VERSION "canboat-NMEA2000-curated"

NS_ :

BS_:

BU_: Vector__XXX
BO_ 2583628544 PGN_130827_furunoNavpilotStatus: 13 Vector__XXX
 SG_ Manufacturer_Code : 0|11@1+ (1.0,0) [0|2047] "" Vector__XXX
 SG_ Industry_Code : 13|3@1+ (1.0,0) [0|7] "" Vector__XXX
 SG_ Message_ID : 16|8@1+ (1.0,0) [0|255] "" Vector__XXX
 SG_ Rudder_Angle : 24|16@1+ (0.0001,0) [0.0|6.5535000000000005] "" Vector__XXX
 SG_ A : 40|16@1- (1.0,0) [-32768|32767] "" Vector__XXX
 SG_ B : 56|8@1+ (1.0,0) [0|255] "" Vector__XXX
 SG_ Commanded_Course : 64|16@1+ (0.0001,0) [0.0|6.5535000000000005] "" Vector__XXX
 SG_ C : 80|8@1+ (1.0,0) [0|255] "" Vector__XXX
 SG_ D : 88|16@1+ (1.0,0) [0|65535] "" Vector__XXX

BO_ 2583628544 PGN_130827_lowranceUnknown: 10 Vector__XXX
 SG_ Manufacturer_Code : 0|11@1+ (1.0,0) [0|2047] "" Vector__XXX
 SG_ Industry_Code : 13|3@1+ (1.0,0) [0|7] "" Vector__XXX
 SG_ A : 16|8@1+ (1.0,0) [0|255] "" Vector__XXX
 SG_ B : 24|8@1+ (1.0,0) [0|255] "" Vector__XXX
 SG_ C : 32|8@1+ (1.0,0) [0|255] "" Vector__XXX
 SG_ D : 40|8@1+ (1.0,0) [0|255] "" Vector__XXX
 SG_ E : 48|16@1+ (1.0,0) [0|65535] "" Vector__XXX
 SG_ F : 64|16@1+ (1.0,0) [0|65535] "" Vector__XXX

BO_ 2583628544 PGN_130827_sleipnerThrusterStatus: 13 Vector__XXX
 SG_ Manufacturer_Code : 0|11@1+ (1.0,0) [0|2047] "" Vector__XXX
 SG_ Industry_Code : 13|3@1+ (1.0,0) [0|7] "" Vector__XXX
 SG_ Controller_Type : 16|8@1+ (1.0,0) [0|255] "" Vector__XXX
 SG_ Thruster_Id : 24|4@1+ (1.0,0) [0|15] "" Vector__XXX
 SG_ State : 28|4@1+ (1.0,0) [0|15] "" Vector__XXX
 SG_ Unique_Number : 32|24@1+ (1.0,0) [0|16777215] "" Vector__XXX
 SG_ A : 56|8@1+ (1.0,0) [0|255] "" Vector__XXX
 SG_ B : 64|8@1+ (1.0,0) [0|255] "" Vector__XXX
 SG_ C : 72|8@1+ (1.0,0) [0|255] "" Vector__XXX
 SG_ D : 80|8@1+ (1.0,0) [0|255] "" Vector__XXX
 SG_ Thrust : 88|8@1- (1.0,0) [-128|127] "%" Vector__XXX
 SG_ E : 96|8@1+ (1.0,0) [0|255] "" Vector__XXX

BO_ 2315193344 PGN_130828_maretronDometicHvacControlStatus: 14 Vector__XXX
 SG_ Manufacturer_Code : 0|11@1+ (1.0,0) [0|2047] "" Vector__XXX
 SG_ Industry_Code : 13|3@1+ (1.0,0) [0|7] "" Vector__XXX
 SG_ CAN_ID : 16|32@1+ (1.0,0) [0|4294967295] "" Vector__XXX
 SG_ Configuration_Mode : 48|8@1+ (1.0,0) [0|255] "" Vector__XXX
 SG_ Status : 56|8@1+ (1.0,0) [0|255] "" Vector__XXX
 SG_ Fan_Mode_Speed : 64|8@1+ (1.0,0) [0|255] "" Vector__XXX
 SG_ Setpoint_Temperature : 72|8@1+ (1.0,0) [0|255] "" Vector__XXX
 SG_ Ambient_Temperature : 80|8@1+ (1.0,0) [0|255] "" Vector__XXX
 SG_ Outdoor_Temperature : 88|8@1+ (1.0,0) [0|255] "" Vector__XXX
 SG_ Fault_Status : 96|8@1+ (1.0,0) [0|255] "" Vector__XXX
 SG_ Additional_Sensor_Temperature : 104|8@1+ (1.0,0) [0|255] "" Vector__XXX

BO_ 2583628800 PGN_130828_simnetSetSerialNumber: 8 Vector__XXX
 SG_ Manufacturer_Code : 0|11@1+ (1.0,0) [0|2047] "" Vector__XXX
 SG_ Industry_Code : 13|3@1+ (1.0,0) [0|7] "" Vector__XXX

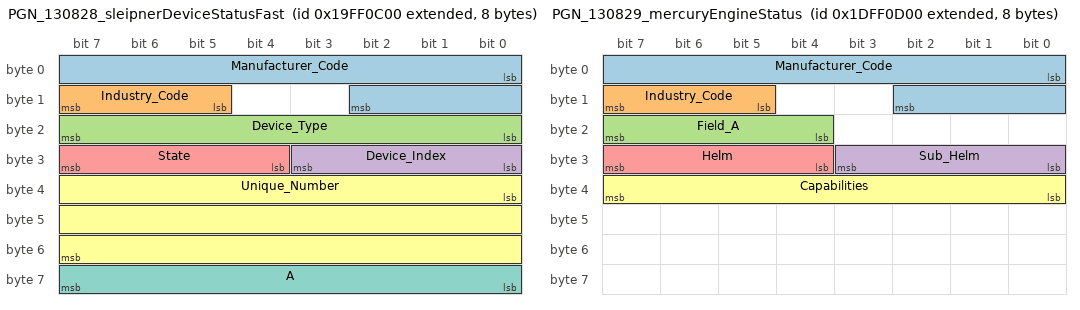
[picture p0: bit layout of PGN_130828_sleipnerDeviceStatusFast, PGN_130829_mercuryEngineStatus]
BO_ 2583628800 PGN_130828_sleipnerDeviceStatusFast: 8 Vector__XXX
 SG_ Manufacturer_Code : 0|11@1+ (1.0,0) [0|2047] "" Vector__XXX
 SG_ Industry_Code : 13|3@1+ (1.0,0) [0|7] "" Vector__XXX
 SG_ Device_Type : 16|8@1+ (1.0,0) [0|255] "" Vector__XXX
 SG_ Device_Index : 24|4@1+ (1.0,0) [0|15] "" Vector__XXX
 SG_ State : 28|4@1+ (1.0,0) [0|15] "" Vector__XXX
 SG_ Unique_Number : 32|24@1+ (1.0,0) [0|16777215] "" Vector__XXX
 SG_ A : 56|8@1+ (1.0,0) [0|255] "" Vector__XXX

BO_ 2650737920 PGN_130829_mercuryEngineStatus: 8 Vector__XXX
 SG_ Manufacturer_Code : 0|11@1+ (1.0,0) [0|2047] "" Vector__XXX
 SG_ Industry_Code : 13|3@1+ (1.0,0) [0|7] "" Vector__XXX
 SG_ Field_A : 20|4@1+ (1.0,0) [0|15] "" Vector__XXX
 SG_ Sub_Helm : 24|4@1+ (1.0,0) [0|15] "" Vector__XXX
 SG_ Helm : 28|4@1+ (1.0,0) [0|15] "" Vector__XXX
 SG_ Capabilities : 32|8@1+ (1.0,0) [0|255] "" Vector__XXX

BO_ 2516520448 PGN_130830_maretronDometicHvacStatus: 12 Vector__XXX
 SG_ Manufacturer_Code : 0|11@1+ (1.0,0) [0|2047] "" Vector__XXX
 SG_ Industry_Code : 13|3@1+ (1.0,0) [0|7] "" Vector__XXX
 SG_ Additional_Sensor_Temperature : 16|8@1+ (1.0,0) [0|255] "" Vector__XXX
 SG_ CAN_ID : 24|32@1+ (1.0,0) [0|4294967295] "" Vector__XXX
 SG_ State : 56|8@1+ (1.0,0) [0|255] "" Vector__XXX
 SG_ Hardware_Status : 64|8@1+ (1.0,0) [0|255] "" Vector__XXX
 SG_ Faults : 72|8@1+ (1.0,0) [0|255] "" Vector__XXX
 SG_ Line_Voltage : 80|8@1+ (1.0,0) [0|255] "" Vector__XXX
 SG_ Compressor_Current : 88|8@1+ (1.0,0) [0|255] "" Vector__XXX

BO_ 2583629312 PGN_130830_suzukiEngineData: 8 Vector__XXX
 SG_ Manufacturer_Code : 0|11@1+ (1.0,0) [0|2047] "" Vector__XXX
 SG_ Industry_Code : 13|3@1+ (1.0,0) [0|7] "" Vector__XXX

BO_ 2583629568 PGN_130831_maretronUniversalConfigurationFp: 223 Vector__XXX
 SG_ Manufacturer_Code : 0|11@1+ (1.0,0) [0|2047] "" Vector__XXX
 SG_ Industry_Code : 13|3@1+ (1.0,0) [0|7] "" Vector__XXX
 SG_ Data : 16|1768@1+ (1.0,0) [0|16635364987126134419907490844611231857889171561340108669757218330385068731224834608417815051548234195819468783937845710359164977421616154908223175941492902641772198991471137845920843845811776377869137773379678289214194183661112800944378464511794046030758602257005203964634516091405743061582849883160885255175229773660916874237270946647032424101972117051870087763059119895517977437771543686400460392041962138103436564399831189767740372774280024852942859855049773927338342604171805121253257539126169331943684033945189625789470637817855] "" Vector__XXX

BO_ 2583629568 PGN_130831_suzukiEngineAndStorageDeviceConfig: 8 Vector__XXX
 SG_ Manufacturer_Code : 0|11@1+ (1.0,0) [0|2047] "" Vector__XXX
 SG_ Industry_Code : 13|3@1+ (1.0,0) [0|7] "" Vector__XXX

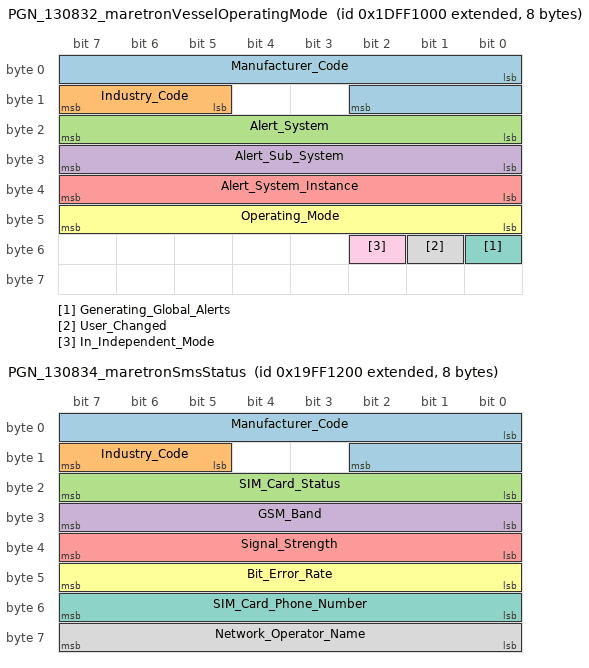
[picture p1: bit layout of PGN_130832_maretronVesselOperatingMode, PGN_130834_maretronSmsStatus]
BO_ 2650738688 PGN_130832_maretronVesselOperatingMode: 8 Vector__XXX
 SG_ Manufacturer_Code : 0|11@1+ (1.0,0) [0|2047] "" Vector__XXX
 SG_ Industry_Code : 13|3@1+ (1.0,0) [0|7] "" Vector__XXX
 SG_ Alert_System : 16|8@1+ (1.0,0) [0|255] "" Vector__XXX
 SG_ Alert_Sub_System : 24|8@1+ (1.0,0) [0|255] "" Vector__XXX
 SG_ Alert_System_Instance : 32|8@1+ (1.0,0) [0|255] "" Vector__XXX
 SG_ Operating_Mode : 40|8@1+ (1.0,0) [0|255] "" Vector__XXX
 SG_ Generating_Global_Alerts : 48|1@1+ (1.0,0) [0|1] "" Vector__XXX
 SG_ User_Changed : 49|1@1+ (1.0,0) [0|1] "" Vector__XXX
 SG_ In_Independent_Mode : 50|1@1+ (1.0,0) [0|1] "" Vector__XXX

BO_ 2583629824 PGN_130832_simnetFuelUsedHighResolution: 8 Vector__XXX
 SG_ Manufacturer_Code : 0|11@1+ (1.0,0) [0|2047] "" Vector__XXX
 SG_ Industry_Code : 13|3@1+ (1.0,0) [0|7] "" Vector__XXX

BO_ 2583630080 PGN_130833_bGUserAndRemoteRename: 30 Vector__XXX
 SG_ Manufacturer_Code : 0|11@1+ (1.0,0) [0|2047] "" Vector__XXX
 SG_ Industry_Code : 13|3@1+ (1.0,0) [0|7] "" Vector__XXX
 SG_ Data_Type : 16|12@1+ (1.0,0) [0|4095] "" Vector__XXX
 SG_ Length : 28|4@1+ (1.0,0) [0|15] "" Vector__XXX
 SG_ Decimals : 40|8@1+ (1.0,0) [0|255] "" Vector__XXX
 SG_ Short_name : 48|64@1+ (1.0,0) [0|18446744073709551615] "" Vector__XXX
 SG_ Long_name : 112|128@1+ (1.0,0) [0|340282366920938463463374607431768211455] "" Vector__XXX

BO_ 2650738944 PGN_130833_furunoShipParametersAndAntennaPosition: 15 Vector__XXX
 SG_ Manufacturer_Code : 0|11@1+ (1.0,0) [0|2047] "" Vector__XXX
 SG_ Industry_Code : 13|3@1+ (1.0,0) [0|7] "" Vector__XXX
 SG_ Equipment_Identification : 16|8@1+ (1.0,0) [0|255] "" Vector__XXX
 SG_ Antenna_position_X : 24|16@1- (0.01,0) [-327.68|327.67] "" Vector__XXX
 SG_ Antenna_position_Y : 40|16@1+ (0.1,0) [0.0|6553.5] "" Vector__XXX
 SG_ Antenna_position_Z : 56|16@1+ (0.1,0) [0.0|6553.5] "" Vector__XXX
 SG_ Ship_s_width : 72|16@1+ (0.1,0) [0.0|6553.5] "" Vector__XXX
 SG_ Ship_s_length : 88|16@1+ (0.1,0) [0.0|6553.5] "" Vector__XXX
 SG_ Ship_s_height : 104|16@1+ (0.1,0) [0.0|6553.5] "" Vector__XXX

BO_ 2650738944 PGN_130833_maretronVesselDataRecorderStatus: 19 Vector__XXX
 SG_ Manufacturer_Code : 0|11@1+ (1.0,0) [0|2047] "" Vector__XXX
 SG_ Industry_Code : 13|3@1+ (1.0,0) [0|7] "" Vector__XXX
 SG_ VDR_Recording_Status : 16|8@1+ (1.0,0) [0|255] "" Vector__XXX
 SG_ Memory_Capacity : 24|64@1+ (1.0,0) [0|18446744073709551615] "" Vector__XXX
 SG_ Memory_Used : 88|64@1+ (1.0,0) [0|18446744073709551615] "" Vector__XXX

BO_ 2650739200 PGN_130834_furunoSpeedCalculationPosition: 9 Vector__XXX
 SG_ Manufacturer_Code : 0|11@1+ (1.0,0) [0|2047] "" Vector__XXX
 SG_ Industry_Code : 13|3@1+ (1.0,0) [0|7] "" Vector__XXX
 SG_ Point_index : 16|8@1+ (1.0,0) [0|255] "" Vector__XXX
 SG_ Position_Y : 40|16@1+ (0.1,0) [0.0|6553.5] "" Vector__XXX
 SG_ Position_Z : 56|16@1+ (0.1,0) [0.0|6553.5] "" Vector__XXX

BO_ 2583630336 PGN_130834_maretronSmsStatus: 8 Vector__XXX
 SG_ Manufacturer_Code : 0|11@1+ (1.0,0) [0|2047] "" Vector__XXX
 SG_ Industry_Code : 13|3@1+ (1.0,0) [0|7] "" Vector__XXX
 SG_ SIM_Card_Status : 16|8@1+ (1.0,0) [0|255] "" Vector__XXX
 SG_ GSM_Band : 24|8@1+ (1.0,0) [0|255] "" Vector__XXX
 SG_ Signal_Strength : 32|8@1+ (1.0,0) [0|255] "" Vector__XXX
 SG_ Bit_Error_Rate : 40|8@1+ (1.0,0) [0|255] "" Vector__XXX
 SG_ SIM_Card_Phone_Number : 48|8@1+ (1.0,0) [0|255] "" Vector__XXX
 SG_ Network_Operator_Name : 56|8@1+ (1.0,0) [0|255] "" Vector__XXX

BO_ 2583630336 PGN_130834_simnetEngineAndTankConfiguration: 8 Vector__XXX
 SG_ Manufacturer_Code : 0|11@1+ (1.0,0) [0|2047] "" Vector__XXX
 SG_ Industry_Code : 13|3@1+ (1.0,0) [0|7] "" Vector__XXX

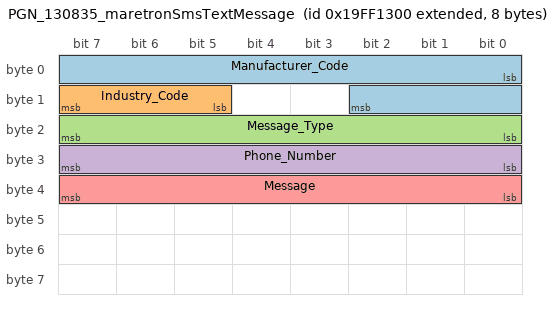
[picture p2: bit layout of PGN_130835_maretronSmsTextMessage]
BO_ 2583630592 PGN_130835_maretronSmsTextMessage: 8 Vector__XXX
 SG_ Manufacturer_Code : 0|11@1+ (1.0,0) [0|2047] "" Vector__XXX
 SG_ Industry_Code : 13|3@1+ (1.0,0) [0|7] "" Vector__XXX
 SG_ Message_Type : 16|8@1+ (1.0,0) [0|255] "" Vector__XXX
 SG_ Phone_Number : 24|8@1+ (1.0,0) [0|255] "" Vector__XXX
 SG_ Message : 32|8@1+ (1.0,0) [0|255] "" Vector__XXX

BO_ 2583630592 PGN_130835_simnetSetEngineAndTankConfiguration: 8 Vector__XXX
 SG_ Manufacturer_Code : 0|11@1+ (1.0,0) [0|2047] "" Vector__XXX
 SG_ Industry_Code : 13|3@1+ (1.0,0) [0|7] "" Vector__XXX

BO_ 2583630848 PGN_130836_maretronSwitchStatusCounter: 23 Vector__XXX
 SG_ Manufacturer_Code : 0|11@1+ (1.0,0) [0|2047] "" Vector__XXX
 SG_ Industry_Code : 13|3@1+ (1.0,0) [0|7] "" Vector__XXX
 SG_ Instance : 16|8@1+ (1.0,0) [0|255] "" Vector__XXX
 SG_ Indicator_Number : 24|8@1+ (1.0,0) [0|255] "" Vector__XXX
 SG_ Start_Date : 32|16@1+ (1.0,0) [0|65535] "" Vector__XXX
 SG_ Start_Time : 48|32@1+ (0.0001,0) [0.0|86401.0] "" Vector__XXX
 SG_ OFF_Counter : 80|32@1+ (1.0,0) [0|4294967295] "" Vector__XXX
 SG_ ON_Counter : 112|32@1+ (1.0,0) [0|4294967295] "" Vector__XXX
 SG_ ERROR_Counter : 144|32@1+ (1.0,0) [0|4294967295] "" Vector__XXX
 SG_ Switch_Status : 176|2@1+ (1.0,0) [0|3] "" Vector__XXX

BO_ 2583630848 PGN_130836_simnetFluidLevelSensorConfiguration: 14 Vector__XXX
 SG_ Manufacturer_Code : 0|11@1+ (1.0,0) [0|2047] "" Vector__XXX
 SG_ Industry_Code : 13|3@1+ (1.0,0) [0|7] "" Vector__XXX
 SG_ C : 16|8@1+ (1.0,0) [0|255] "" Vector__XXX
 SG_ Device : 24|8@1+ (1.0,0) [0|255] "" Vector__XXX
 SG_ Instance : 32|8@1+ (1.0,0) [0|255] "" Vector__XXX
 SG_ F : 40|4@1+ (1.0,0) [0|15] "" Vector__XXX
 SG_ Tank_type : 44|4@1+ (1.0,0) [0|15] "" Vector__XXX
 SG_ Capacity : 48|32@1+ (0.1,0) [0.0|429496729.5] "" Vector__XXX
 SG_ G : 80|8@1+ (1.0,0) [0|255] "" Vector__XXX
 SG_ H : 88|16@1- (1.0,0) [-32768|32767] "" Vector__XXX
 SG_ I : 104|8@1- (1.0,0) [-128|127] "" Vector__XXX

CM_ BO_ 2583628544 "NMEA2000: PGN 130827 - Furuno: NavPilot Status (type: Fast)";
CM_ BO_ 2583628544 "NMEA2000: PGN 130827 - Lowrance: unknown (type: Fast)";
CM_ BO_ 2583628544 "NMEA2000: PGN 130827 - Sleipner: Thruster Status (type: Fast)";
CM_ BO_ 2315193344 "NMEA2000: PGN 130828 - Maretron: Dometic HVAC Control Status (type: Fast)";
CM_ BO_ 2583628800 "NMEA2000: PGN 130828 - Simnet: Set Serial Number (type: Fast)";
CM_ BO_ 2583628800 "NMEA2000: PGN 130828 - Sleipner: Device Status (Fast) (type: Fast)";
CM_ BO_ 2650737920 "NMEA2000: PGN 130829 - Mercury: Engine Status (type: Fast)";
CM_ BO_ 2516520448 "NMEA2000: PGN 130830 - Maretron: Dometic HVAC Status (type: Fast)";
CM_ BO_ 2583629312 "NMEA2000: PGN 130830 - Suzuki: Engine Data (type: Fast)";
CM_ BO_ 2583629568 "NMEA2000: PGN 130831 - Maretron: Universal Configuration FP (type: Fast)";
CM_ BO_ 2583629568 "NMEA2000: PGN 130831 - Suzuki: Engine and Storage Device Config (type: Fast)";
CM_ BO_ 2650738688 "NMEA2000: PGN 130832 - Maretron: Vessel Operating Mode (type: Fast)";
CM_ BO_ 2583629824 "NMEA2000: PGN 130832 - Simnet: Fuel Used - High Resolution (type: Fast)";
CM_ BO_ 2583630080 "NMEA2000: PGN 130833 - B&G: User and Remote rename (type: Fast)";
CM_ BO_ 2650738944 "NMEA2000: PGN 130833 - Furuno: Ship Parameters and Antenna Position (type: Fast)";
CM_ BO_ 2650738944 "NMEA2000: PGN 130833 - Maretron: Vessel Data Recorder Status (type: Fast)";
CM_ BO_ 2650739200 "NMEA2000: PGN 130834 - Furuno: Speed-calculation Position (type: Fast)";
CM_ BO_ 2583630336 "NMEA2000: PGN 130834 - Maretron: SMS Status (type: Fast)";
CM_ BO_ 2583630336 "NMEA2000: PGN 130834 - Simnet: Engine and Tank Configuration (type: Fast)";
CM_ BO_ 2583630592 "NMEA2000: PGN 130835 - Maretron: SMS Text Message (type: Fast)";
CM_ BO_ 2583630592 "NMEA2000: PGN 130835 - Simnet: Set Engine and Tank Configuration (type: Fast)";
CM_ BO_ 2583630848 "NMEA2000: PGN 130836 - Maretron: Switch Status Counter (type: Fast)";
CM_ BO_ 2583630848 "NMEA2000: PGN 130836 - Simnet: Fluid Level Sensor Configuration (type: Fast)";
CM_ SG_ 2583628544 Manufacturer_Code "Furuno; canboat type: LOOKUP";
CM_ SG_ 2583628544 Industry_Code "Marine Industry; canboat type: LOOKUP";
CM_ SG_ 2583628544 Message_ID "NavPilot Status; canboat type: UINT8";
CM_ SG_ 2583628544 Rudder_Angle "canboat type: ANGLE_UFIX16";
CM_ SG_ 2583628544 A "canboat type: INT16";
CM_ SG_ 2583628544 B "canboat type: UINT8";
CM_ SG_ 2583628544 Commanded_Course "canboat type: ANGLE_UFIX16";
CM_ SG_ 2583628544 C "canboat type: UINT8";
CM_ SG_ 2583628544 D "canboat type: UINT16";
CM_ SG_ 2583628544 Manufacturer_Code "Lowrance; canboat type: LOOKUP";
CM_ SG_ 2583628544 Industry_Code "Marine Industry; canboat type: LOOKUP";
CM_ SG_ 2583628544 A "canboat type: UINT8";
CM_ SG_ 2583628544 B "canboat type: UINT8";
CM_ SG_ 2583628544 C "canboat type: UINT8";
CM_ SG_ 2583628544 D "canboat type: UINT8";
CM_ SG_ 2583628544 E "canboat type: UINT16";
CM_ SG_ 2583628544 F "canboat type: UINT16";
CM_ SG_ 2583628544 Manufacturer_Code "Sleipner Motor; canboat type: LOOKUP";
CM_ SG_ 2583628544 Industry_Code "Marine Industry; canboat type: LOOKUP";
CM_ SG_ 2583628544 Controller_Type "Constant per device; 24 = PPC520, 25 = PPC820; canboat type: UINT8";
CM_ SG_ 2583628544 Thruster_Id "Stable per-unit index within the thruster group; canboat type: UNSIGNED_INTEGER";
CM_ SG_ 2583628544 State "canboat type: LOOKUP";
CM_ SG_ 2583628544 Unique_Number "ISO Identity Number, as claimed by this device in PGN 60928; canboat type: UNSIGNED_INTEGER";
CM_ SG_ 2583628544 A "canboat type: UINT8";
CM_ SG_ 2583628544 B "canboat type: UINT8";
CM_ SG_ 2583628544 C "canboat type: UINT8";
CM_ SG_ 2583628544 D "canboat type: UINT8";
CM_ SG_ 2583628544 Thrust "Reported thrust, -100 to 100%; the sign is the direction; canboat type: PERCENTAGE_INT8";
CM_ SG_ 2583628544 E "canboat type: UINT8";
CM_ SG_ 2315193344 Manufacturer_Code "Maretron; canboat type: LOOKUP";
CM_ SG_ 2315193344 Industry_Code "Marine Industry; canboat type: LOOKUP";
CM_ SG_ 2315193344 CAN_ID "canboat type: UINT32";
CM_ SG_ 2315193344 Configuration_Mode "canboat type: UINT8";
CM_ SG_ 2315193344 Status "canboat type: UINT8";
CM_ SG_ 2315193344 Fan_Mode_Speed "canboat type: UINT8";
CM_ SG_ 2315193344 Setpoint_Temperature "canboat type: UINT8";
CM_ SG_ 2315193344 Ambient_Temperature "canboat type: UINT8";
CM_ SG_ 2315193344 Outdoor_Temperature "canboat type: UINT8";
CM_ SG_ 2315193344 Fault_Status "canboat type: UINT8";
CM_ SG_ 2315193344 Additional_Sensor_Temperature "canboat type: UINT8";
CM_ SG_ 2583628800 Manufacturer_Code "Simrad; canboat type: LOOKUP";
CM_ SG_ 2583628800 Industry_Code "Marine Industry; canboat type: LOOKUP";
CM_ SG_ 2583628800 Manufacturer_Code "Sleipner Motor; canboat type: LOOKUP";
CM_ SG_ 2583628800 Industry_Code "Marine Industry; canboat type: LOOKUP";
CM_ SG_ 2583628800 Device_Type "Constant per device; canboat type: UINT8";
CM_ SG_ 2583628800 Device_Index "Stable per-device index; canboat type: UNSIGNED_INTEGER";
CM_ SG_ 2583628800 State "canboat type: LOOKUP";
CM_ SG_ 2583628800 Unique_Number "ISO Identity Number, as claimed by this device in PGN 60928; canboat type: UNSIGNED_INTEGER";
CM_ SG_ 2583628800 A "canboat type: UINT8";
CM_ SG_ 2650737920 Manufacturer_Code "Mercury Marine; canboat type: LOOKUP";
CM_ SG_ 2650737920 Industry_Code "Marine Industry; canboat type: LOOKUP";
CM_ SG_ 2650737920 Field_A "Reserved (unused); canboat type: BINARY";
CM_ SG_ 2650737920 Sub_Helm "Helm-station sub-address (Mercury multi-helm); byte 3 low nibble; canboat type: BINARY";
CM_ SG_ 2650737920 Helm "Helm-station address (Mercury multi-helm); byte 3 high nibble; canboat type: BINARY";
CM_ SG_ 2650737920 Capabilities "Capability bitmask: bit0 = Beacon, bit1 = Cruise Control capability; canboat type: BINARY";
CM_ SG_ 2516520448 Manufacturer_Code "Maretron; canboat type: LOOKUP";
CM_ SG_ 2516520448 Industry_Code "Marine Industry; canboat type: LOOKUP";
CM_ SG_ 2516520448 Additional_Sensor_Temperature "canboat type: UINT8";
CM_ SG_ 2516520448 CAN_ID "canboat type: UINT32";
CM_ SG_ 2516520448 State "canboat type: UINT8";
CM_ SG_ 2516520448 Hardware_Status "canboat type: UINT8";
CM_ SG_ 2516520448 Faults "canboat type: UINT8";
CM_ SG_ 2516520448 Line_Voltage "canboat type: UINT8";
CM_ SG_ 2516520448 Compressor_Current "canboat type: UINT8";
CM_ SG_ 2583629312 Manufacturer_Code "Suzuki Motor Corporation; canboat type: LOOKUP";
CM_ SG_ 2583629312 Industry_Code "Marine Industry; canboat type: LOOKUP";
CM_ SG_ 2583629568 Manufacturer_Code "Maretron; canboat type: LOOKUP";
CM_ SG_ 2583629568 Industry_Code "Marine Industry; canboat type: LOOKUP";
CM_ SG_ 2583629568 Data "canboat type: BINARY";
CM_ SG_ 2583629568 Manufacturer_Code "Suzuki Motor Corporation; canboat type: LOOKUP";
CM_ SG_ 2583629568 Industry_Code "Marine Industry; canboat type: LOOKUP";
CM_ SG_ 2650738688 Manufacturer_Code "Maretron; canboat type: LOOKUP";
CM_ SG_ 2650738688 Industry_Code "Marine Industry; canboat type: LOOKUP";
CM_ SG_ 2650738688 Alert_System "canboat type: UINT8";
CM_ SG_ 2650738688 Alert_Sub_System "canboat type: UINT8";
CM_ SG_ 2650738688 Alert_System_Instance "canboat type: UINT8";
CM_ SG_ 2650738688 Operating_Mode "canboat type: UINT8";
CM_ SG_ 2650738688 Generating_Global_Alerts "canboat type: UNSIGNED_INTEGER";
CM_ SG_ 2650738688 User_Changed "canboat type: UNSIGNED_INTEGER";
CM_ SG_ 2650738688 In_Independent_Mode "canboat type: UNSIGNED_INTEGER";
CM_ SG_ 2583629824 Manufacturer_Code "Simrad; canboat type: LOOKUP";
CM_ SG_ 2583629824 Industry_Code "Marine Industry; canboat type: LOOKUP";
CM_ SG_ 2583630080 Manufacturer_Code "B & G; canboat type: LOOKUP";
CM_ SG_ 2583630080 Industry_Code "Marine Industry; canboat type: LOOKUP";
CM_ SG_ 2583630080 Data_Type "canboat type: DYNAMIC_FIELD_KEY";
CM_ SG_ 2583630080 Length "Length of field 8; canboat type: UNSIGNED_INTEGER";
CM_ SG_ 2583630080 Decimals "canboat type: LOOKUP";
CM_ SG_ 2583630080 Short_name "canboat type: STRING_FIX";
CM_ SG_ 2583630080 Long_name "canboat type: STRING_FIX";
CM_ SG_ 2650738944 Manufacturer_Code "Furuno; canboat type: LOOKUP";
CM_ SG_ 2650738944 Industry_Code "Marine Industry; canboat type: LOOKUP";
CM_ SG_ 2650738944 Equipment_Identification "canboat type: UINT8";
CM_ SG_ 2650738944 Antenna_position_X "Athwartship offset; canboat type: DISTANCE_FIX16_CM";
CM_ SG_ 2650738944 Antenna_position_Y "canboat type: LENGTH_UFIX16_DM";
CM_ SG_ 2650738944 Antenna_position_Z "canboat type: LENGTH_UFIX16_DM";
CM_ SG_ 2650738944 Ship_s_width "canboat type: LENGTH_UFIX16_DM";
CM_ SG_ 2650738944 Ship_s_length "canboat type: LENGTH_UFIX16_DM";
CM_ SG_ 2650738944 Ship_s_height "canboat type: LENGTH_UFIX16_DM";
CM_ SG_ 2650738944 Manufacturer_Code "Maretron; canboat type: LOOKUP";
CM_ SG_ 2650738944 Industry_Code "Marine Industry; canboat type: LOOKUP";
CM_ SG_ 2650738944 VDR_Recording_Status "canboat type: UINT8";
CM_ SG_ 2650738944 Memory_Capacity "canboat type: UINT64";
CM_ SG_ 2650738944 Memory_Used "canboat type: UINT64";
CM_ SG_ 2650739200 Manufacturer_Code "Furuno; canboat type: LOOKUP";
CM_ SG_ 2650739200 Industry_Code "Marine Industry; canboat type: LOOKUP";
CM_ SG_ 2650739200 Point_index "canboat type: UINT8";
CM_ SG_ 2650739200 Position_Y "canboat type: LENGTH_UFIX16_DM";
CM_ SG_ 2650739200 Position_Z "canboat type: LENGTH_UFIX16_DM";
CM_ SG_ 2583630336 Manufacturer_Code "Maretron; canboat type: LOOKUP";
CM_ SG_ 2583630336 Industry_Code "Marine Industry; canboat type: LOOKUP";
CM_ SG_ 2583630336 SIM_Card_Status "canboat type: UINT8";
CM_ SG_ 2583630336 GSM_Band "canboat type: UINT8";
CM_ SG_ 2583630336 Signal_Strength "canboat type: UINT8";
CM_ SG_ 2583630336 Bit_Error_Rate "canboat type: UINT8";
CM_ SG_ 2583630336 SIM_Card_Phone_Number "canboat type: STRING_LAU";
CM_ SG_ 2583630336 Network_Operator_Name "canboat type: STRING_LAU";
CM_ SG_ 2583630336 Manufacturer_Code "Simrad; canboat type: LOOKUP";
CM_ SG_ 2583630336 Industry_Code "Marine Industry; canboat type: LOOKUP";
CM_ SG_ 2583630592 Manufacturer_Code "Maretron; canboat type: LOOKUP";
CM_ SG_ 2583630592 Industry_Code "Marine Industry; canboat type: LOOKUP";
CM_ SG_ 2583630592 Message_Type "canboat type: UINT8";
CM_ SG_ 2583630592 Phone_Number "canboat type: STRING_LAU";
CM_ SG_ 2583630592 Message "canboat type: STRING_LAU";
CM_ SG_ 2583630592 Manufacturer_Code "Simrad; canboat type: LOOKUP";
CM_ SG_ 2583630592 Industry_Code "Marine Industry; canboat type: LOOKUP";
CM_ SG_ 2583630848 Manufacturer_Code "Maretron; canboat type: LOOKUP";
CM_ SG_ 2583630848 Industry_Code "Marine Industry; canboat type: LOOKUP";
CM_ SG_ 2583630848 Instance "canboat type: UINT8";
CM_ SG_ 2583630848 Indicator_Number "canboat type: UINT8";
CM_ SG_ 2583630848 Start_Date "canboat type: DATE";
CM_ SG_ 2583630848 Start_Time "Seconds since midnight; canboat type: TIME";
CM_ SG_ 2583630848 OFF_Counter "canboat type: UINT32";
CM_ SG_ 2583630848 ON_Counter "canboat type: UINT32";
CM_ SG_ 2583630848 ERROR_Counter "canboat type: UINT32";
CM_ SG_ 2583630848 Switch_Status "canboat type: LOOKUP";
CM_ SG_ 2583630848 Manufacturer_Code "Simrad; canboat type: LOOKUP";
CM_ SG_ 2583630848 Industry_Code "Marine Industry; canboat type: LOOKUP";
CM_ SG_ 2583630848 C "canboat type: UINT8";
CM_ SG_ 2583630848 Device "canboat type: UINT8";
CM_ SG_ 2583630848 Instance "canboat type: UINT8";
CM_ SG_ 2583630848 F "canboat type: UNSIGNED_INTEGER";
CM_ SG_ 2583630848 Tank_type "canboat type: LOOKUP";
CM_ SG_ 2583630848 Capacity "canboat type: VOLUME_UFIX32_DL";
CM_ SG_ 2583630848 G "canboat type: UINT8";
CM_ SG_ 2583630848 H "canboat type: INT16";
CM_ SG_ 2583630848 I "canboat type: INT8";
VAL_ 2583628544 Manufacturer_Code 69 "ARKS Enterprises" 78 "FW Murphy/Enovation Controls" 80 "Twin Disc" 85 "Kohler Power Systems" 88 "Hemisphere GPS" 135 "Airmar" 137 "Maretron" 140 "Lowrance" 144 "Mercury Marine" 147 "Nautibus Electronic" 148 "Blue Water Data" 154 "Westerbeke" 157 "ISSPRO" 161 "Offshore Systems (UK)" 163 "Evinrude/BRP" 165 "CPAC Systems" 168 "Xantrex Technology" 169 "Marlin Technologies" 172 "Yanmar Marine" 174 "Volvo Penta" 176 "Carling Technologies Inc. (Moritz Aerospace)" 185 "Beede Instruments" 192 "Floscan Instrument" 193 "Nobeltec" 198 "Mystic Valley Communications" 199 "Actia" 201 "Disenos Y Technologia" 211 "Digital Switching Systems" 215 "Xintex/Atena" 224 "EMMI NETWORK" 228 "ZF" 229 "Garmin" 233 "Yacht Monitoring Solutions" 235 "Sailormade Marine Telemetry/Tetra Technology" 243 "Eride" 257 "Honda Motor" 272 "Groco" 273 "Actisense" 274 "Amphenol LTW Technology" 275 "Navico" 283 "Hamilton Jet" 285 "Sea Recovery" 286 "Coelmo SRL Italy" 295 "BEP Marine" 304 "Empir Bus" 305 "NovAtel" 306 "Sleipner Motor" 307 "MBW Technologies" 315 "ICOM" 328 "Qwerty" 329 "Dief" 341 "Boening Automationstechnologie" 345 "Korean Maritime University" 351 "Thrane and Thrane" 355 "Mastervolt" 356 "Fischer Panda Generators" 358 "Victron Energy" 370 "Rolls Royce Marine" 373 "Electronic Design" 374 "Northern Lights" 378 "Glendinning" 381 "B & G" 384 "Rose Point Navigation Systems" 385 "Johnson Outdoors Marine Electronics Inc Geonav" 394 "Capi 2" 396 "Beyond Measure" 400 "Livorsi Marine" 404 "ComNav" 409 "Chetco" 419 "Fusion Electronics" 421 "Standard Horizon" 422 "True Heading" 426 "Egersund Marine Electronics" 427 "em-trak Marine Electronics" 431 "Tohatsu Co, JP" 437 "Digital Yacht" 438 "Comar Systems Limited" 440 "Cummins" 443 "VDO (aka Continental-Corporation)" 451 "Parker Hannifin aka Village Marine Tech" 459 "Alltek Marine Electronics" 460 "SAN GIORGIO S.E.I.N" 466 "Veethree Electronics & Marine" 470 "SI-TEX Marine Electronics" 471 "Sea Cross Marine" 475 "GME aka Standard Communications" 476 "Humminbird Marine Electronics" 478 "Ocean Sat" 481 "Chetco Digital Instruments" 493 "Watcheye" 499 "Lcj Capteurs" 502 "Attwood Marine" 503 "Naviop S.R.L." 504 "Vesper Marine" 510 "Marinesoft" 513 "Simarine" 517 "NoLand Engineering" 518 "Transas USA" 529 "National Instruments Korea" 530 "National Marine Electronics Association" 532 "Onwa Marine" 540 "Webasto" 571 "Marinecraft (South Korea)" 573 "McMurdo Group aka Orolia" 578 "Advansea" 579 "KVH" 580 "San Jose Technology" 583 "Yacht Control" 586 "Suzuki Motor" 591 "US Coast Guard" 595 "Ship Module aka Customware" 600 "Aquatic AV" 605 "Aventics" 606 "Intellian" 612 "SamwonIT" 614 "Arlt Tecnologies" 637 "Bavaria Yachts" 641 "Diverse Yacht Services" 644 "Wema U.S.A dba KUS" 658 "Shenzhen Jiuzhou Himunication" 688 "Rockford" 699 "Harman International" 704 "JL Audio" 708 "Lars Thrane" 715 "Autonnic" 717 "Yacht Devices" 734 "REAP Systems" 735 "AEM Performance Electronics" 739 "LxNav" 741 "Littelfuse, Inc (formerly Carling Technologies)" 743 "DaeMyung" 744 "Woosung" 748 "ISOTTA IFRA srl" 773 "Clarion US" 776 "HMI Systems" 777 "Ocean Signal" 778 "Seakeeper" 781 "Poly Planar" 785 "Fischer Panda DE" 795 "Broyda Industries" 796 "Canadian Automotive" 797 "Tides Marine" 798 "Lumishore" 799 "Still Water Designs and Audio" 802 "BJ Technologies (Beneteau)" 803 "Gill Sensors" 811 "Blue Water Desalination" 815 "FLIR" 824 "Undheim Systems" 826 "Lewmar" 838 "TeamSurv" 844 "Fell Marine" 847 "Oceanvolt" 862 "Prospec" 868 "Data Panel" 890 "L3 Technologies" 894 "Rhodan Marine Systems" 896 "Nexfour Solutions" 905 "ASA Electronics" 909 "Marines Co (South Korea)" 911 "Nautic-on" 917 "Sentinel" 929 "JL Marine Systems" 930 "Ecotronix" 944 "Zontisa Marine" 951 "EXOR International" 962 "Timbolier Industries" 963 "TJC Micro" 968 "Cox Powertrain" 969 "Blue Seas" 981 "Kobelt Manufacturing" 992 "Blue Ocean IOT" 997 "Xenta Systems" 999 "Signal K" 1004 "Ultraflex" 1008 "Lintest SmartBoat" 1011 "Soundmax" 1020 "Team Italia Marine (Onyx Marine Automation s.r.l)" 1021 "Entratech" 1022 "ITC" 1029 "The Marine Guardian" 1047 "Sonic" 1051 "ProNav" 1053 "Vetus Maxwell INC." 1056 "Lithium Pros" 1059 "Boatrax" 1062 "Marol Co ltd" 1065 "CALYPSO Instruments" 1066 "Spot Zero Water" 1069 "Lithionics Battery" 1070 "Quick-teck Electronics" 1075 "Uniden America" 1083 "Nauticoncept" 1084 "Shadow-Caster LED lighting" 1085 "Wet Sounds" 1088 "E-T-A Circuit Breakers" 1092 "Scheiber" 1100 "Smart Yachts International Limited" 1109 "Dockmate" 1114 "Bobs Machine" 1118 "L3Harris ASV" 1119 "Balmar" 1120 "Elettromedia" 1127 "Electromaax" 1140 "Across Oceans Systems" 1145 "Kiwi Yachting" 1150 "BSB Artificial Intelligence" 1151 "Orca Technologies" 1154 "TBS Electronics" 1158 "Technoton Electroics" 1160 "MG Energy Systems" 1169 "Sea Machine Robotics" 1171 "Vista Manufacturing" 1183 "Zipwake" 1186 "Sailmon" 1192 "Airmoniq Pro Kft" 1194 "Sierra Marine" 1200 "Xinuo Information Technology (Xiamen)" 1218 "Septentrio" 1233 "NKE Marine Electronics" 1238 "SuperTrack Aps" 1239 "Honda Electronics" 1245 "Raritan Engineering" 1249 "Integrated Power Solutions AG" 1260 "Interactive Technologies" 1283 "LTG-Tech" 1299 "Energy Solutions (UK)" 1300 "WATT Fuel Cell" 1302 "Pro Mainer" 1305 "Dragonfly Energy" 1306 "Koden Electronics" 1311 "Humphree" 1316 "Hinkley Yachts" 1317 "Global Marine Management GmbH (GMM)" 1320 "Triskel Marine" 1330 "Warwick Control Technologies" 1331 "Dolphin Charger" 1337 "Barnacle Systems" 1348 "Radian IoT" 1353 "Ocean LED Marine" 1359 "BluNav" 1361 "OVA (Nantong Saiyang Electronics Co., Ltd)" 1368 "RAD Propulsion" 1369 "Electric Yacht" 1372 "Elco Motor Yachts" 1384 "Tecnoseal Foundry S.r.l" 1385 "Pro Charging Systems" 1389 "EVEX" 1398 "Gobius Sensor Technology" 1403 "Arco Marine" 1408 "Lenco Marine" 1413 "Naocontrol" 1417 "Revatek" 1438 "Aeolionics" 1439 "PredictWind" 1440 "Egis Mobile Electric" 1445 "Starboard Yacht Group" 1446 "Roswell Marine" 1451 "ePropulsion (Guangdong ePropulsion Technology Ltd.)" 1452 "Micro-Air" 1453 "Vital Battery" 1458 "Ride Controller" 1460 "Tocaro Blue" 1461 "Vanquish Yachts" 1471 "FT Technologies" 1478 "Alps Alpine" 1481 "E-Force Marine" 1482 "CMC Marine" 1483 "Nanjing Sandemarine Information Technology" 1850 "Teleflex Marine (SeaStar Solutions)" 1851 "Raymarine" 1852 "Navionics" 1853 "Japan Radio" 1854 "Northstar Technologies" 1855 "Furuno" 1856 "Trimble" 1857 "Simrad" 1858 "Litton" 1859 "Kvasar" 1860 "MMP" 1861 "Vector Cantech" 1862 "Yamaha Marine" 1863 "Faria Instruments" ;
VAL_ 2583628544 Industry_Code 0 "Global" 1 "Highway" 2 "Agriculture" 3 "Construction" 4 "Marine Industry" 5 "Industrial" ;
VAL_ 2583628544 Manufacturer_Code 69 "ARKS Enterprises" 78 "FW Murphy/Enovation Controls" 80 "Twin Disc" 85 "Kohler Power Systems" 88 "Hemisphere GPS" 135 "Airmar" 137 "Maretron" 140 "Lowrance" 144 "Mercury Marine" 147 "Nautibus Electronic" 148 "Blue Water Data" 154 "Westerbeke" 157 "ISSPRO" 161 "Offshore Systems (UK)" 163 "Evinrude/BRP" 165 "CPAC Systems" 168 "Xantrex Technology" 169 "Marlin Technologies" 172 "Yanmar Marine" 174 "Volvo Penta" 176 "Carling Technologies Inc. (Moritz Aerospace)" 185 "Beede Instruments" 192 "Floscan Instrument" 193 "Nobeltec" 198 "Mystic Valley Communications" 199 "Actia" 201 "Disenos Y Technologia" 211 "Digital Switching Systems" 215 "Xintex/Atena" 224 "EMMI NETWORK" 228 "ZF" 229 "Garmin" 233 "Yacht Monitoring Solutions" 235 "Sailormade Marine Telemetry/Tetra Technology" 243 "Eride" 257 "Honda Motor" 272 "Groco" 273 "Actisense" 274 "Amphenol LTW Technology" 275 "Navico" 283 "Hamilton Jet" 285 "Sea Recovery" 286 "Coelmo SRL Italy" 295 "BEP Marine" 304 "Empir Bus" 305 "NovAtel" 306 "Sleipner Motor" 307 "MBW Technologies" 315 "ICOM" 328 "Qwerty" 329 "Dief" 341 "Boening Automationstechnologie" 345 "Korean Maritime University" 351 "Thrane and Thrane" 355 "Mastervolt" 356 "Fischer Panda Generators" 358 "Victron Energy" 370 "Rolls Royce Marine" 373 "Electronic Design" 374 "Northern Lights" 378 "Glendinning" 381 "B & G" 384 "Rose Point Navigation Systems" 385 "Johnson Outdoors Marine Electronics Inc Geonav" 394 "Capi 2" 396 "Beyond Measure" 400 "Livorsi Marine" 404 "ComNav" 409 "Chetco" 419 "Fusion Electronics" 421 "Standard Horizon" 422 "True Heading" 426 "Egersund Marine Electronics" 427 "em-trak Marine Electronics" 431 "Tohatsu Co, JP" 437 "Digital Yacht" 438 "Comar Systems Limited" 440 "Cummins" 443 "VDO (aka Continental-Corporation)" 451 "Parker Hannifin aka Village Marine Tech" 459 "Alltek Marine Electronics" 460 "SAN GIORGIO S.E.I.N" 466 "Veethree Electronics & Marine" 470 "SI-TEX Marine Electronics" 471 "Sea Cross Marine" 475 "GME aka Standard Communications" 476 "Humminbird Marine Electronics" 478 "Ocean Sat" 481 "Chetco Digital Instruments" 493 "Watcheye" 499 "Lcj Capteurs" 502 "Attwood Marine" 503 "Naviop S.R.L." 504 "Vesper Marine" 510 "Marinesoft" 513 "Simarine" 517 "NoLand Engineering" 518 "Transas USA" 529 "National Instruments Korea" 530 "National Marine Electronics Association" 532 "Onwa Marine" 540 "Webasto" 571 "Marinecraft (South Korea)" 573 "McMurdo Group aka Orolia" 578 "Advansea" 579 "KVH" 580 "San Jose Technology" 583 "Yacht Control" 586 "Suzuki Motor" 591 "US Coast Guard" 595 "Ship Module aka Customware" 600 "Aquatic AV" 605 "Aventics" 606 "Intellian" 612 "SamwonIT" 614 "Arlt Tecnologies" 637 "Bavaria Yachts" 641 "Diverse Yacht Services" 644 "Wema U.S.A dba KUS" 658 "Shenzhen Jiuzhou Himunication" 688 "Rockford" 699 "Harman International" 704 "JL Audio" 708 "Lars Thrane" 715 "Autonnic" 717 "Yacht Devices" 734 "REAP Systems" 735 "AEM Performance Electronics" 739 "LxNav" 741 "Littelfuse, Inc (formerly Carling Technologies)" 743 "DaeMyung" 744 "Woosung" 748 "ISOTTA IFRA srl" 773 "Clarion US" 776 "HMI Systems" 777 "Ocean Signal" 778 "Seakeeper" 781 "Poly Planar" 785 "Fischer Panda DE" 795 "Broyda Industries" 796 "Canadian Automotive" 797 "Tides Marine" 798 "Lumishore" 799 "Still Water Designs and Audio" 802 "BJ Technologies (Beneteau)" 803 "Gill Sensors" 811 "Blue Water Desalination" 815 "FLIR" 824 "Undheim Systems" 826 "Lewmar" 838 "TeamSurv" 844 "Fell Marine" 847 "Oceanvolt" 862 "Prospec" 868 "Data Panel" 890 "L3 Technologies" 894 "Rhodan Marine Systems" 896 "Nexfour Solutions" 905 "ASA Electronics" 909 "Marines Co (South Korea)" 911 "Nautic-on" 917 "Sentinel" 929 "JL Marine Systems" 930 "Ecotronix" 944 "Zontisa Marine" 951 "EXOR International" 962 "Timbolier Industries" 963 "TJC Micro" 968 "Cox Powertrain" 969 "Blue Seas" 981 "Kobelt Manufacturing" 992 "Blue Ocean IOT" 997 "Xenta Systems" 999 "Signal K" 1004 "Ultraflex" 1008 "Lintest SmartBoat" 1011 "Soundmax" 1020 "Team Italia Marine (Onyx Marine Automation s.r.l)" 1021 "Entratech" 1022 "ITC" 1029 "The Marine Guardian" 1047 "Sonic" 1051 "ProNav" 1053 "Vetus Maxwell INC." 1056 "Lithium Pros" 1059 "Boatrax" 1062 "Marol Co ltd" 1065 "CALYPSO Instruments" 1066 "Spot Zero Water" 1069 "Lithionics Battery" 1070 "Quick-teck Electronics" 1075 "Uniden America" 1083 "Nauticoncept" 1084 "Shadow-Caster LED lighting" 1085 "Wet Sounds" 1088 "E-T-A Circuit Breakers" 1092 "Scheiber" 1100 "Smart Yachts International Limited" 1109 "Dockmate" 1114 "Bobs Machine" 1118 "L3Harris ASV" 1119 "Balmar" 1120 "Elettromedia" 1127 "Electromaax" 1140 "Across Oceans Systems" 1145 "Kiwi Yachting" 1150 "BSB Artificial Intelligence" 1151 "Orca Technologies" 1154 "TBS Electronics" 1158 "Technoton Electroics" 1160 "MG Energy Systems" 1169 "Sea Machine Robotics" 1171 "Vista Manufacturing" 1183 "Zipwake" 1186 "Sailmon" 1192 "Airmoniq Pro Kft" 1194 "Sierra Marine" 1200 "Xinuo Information Technology (Xiamen)" 1218 "Septentrio" 1233 "NKE Marine Electronics" 1238 "SuperTrack Aps" 1239 "Honda Electronics" 1245 "Raritan Engineering" 1249 "Integrated Power Solutions AG" 1260 "Interactive Technologies" 1283 "LTG-Tech" 1299 "Energy Solutions (UK)" 1300 "WATT Fuel Cell" 1302 "Pro Mainer" 1305 "Dragonfly Energy" 1306 "Koden Electronics" 1311 "Humphree" 1316 "Hinkley Yachts" 1317 "Global Marine Management GmbH (GMM)" 1320 "Triskel Marine" 1330 "Warwick Control Technologies" 1331 "Dolphin Charger" 1337 "Barnacle Systems" 1348 "Radian IoT" 1353 "Ocean LED Marine" 1359 "BluNav" 1361 "OVA (Nantong Saiyang Electronics Co., Ltd)" 1368 "RAD Propulsion" 1369 "Electric Yacht" 1372 "Elco Motor Yachts" 1384 "Tecnoseal Foundry S.r.l" 1385 "Pro Charging Systems" 1389 "EVEX" 1398 "Gobius Sensor Technology" 1403 "Arco Marine" 1408 "Lenco Marine" 1413 "Naocontrol" 1417 "Revatek" 1438 "Aeolionics" 1439 "PredictWind" 1440 "Egis Mobile Electric" 1445 "Starboard Yacht Group" 1446 "Roswell Marine" 1451 "ePropulsion (Guangdong ePropulsion Technology Ltd.)" 1452 "Micro-Air" 1453 "Vital Battery" 1458 "Ride Controller" 1460 "Tocaro Blue" 1461 "Vanquish Yachts" 1471 "FT Technologies" 1478 "Alps Alpine" 1481 "E-Force Marine" 1482 "CMC Marine" 1483 "Nanjing Sandemarine Information Technology" 1850 "Teleflex Marine (SeaStar Solutions)" 1851 "Raymarine" 1852 "Navionics" 1853 "Japan Radio" 1854 "Northstar Technologies" 1855 "Furuno" 1856 "Trimble" 1857 "Simrad" 1858 "Litton" 1859 "Kvasar" 1860 "MMP" 1861 "Vector Cantech" 1862 "Yamaha Marine" 1863 "Faria Instruments" ;
VAL_ 2583628544 Industry_Code 0 "Global" 1 "Highway" 2 "Agriculture" 3 "Construction" 4 "Marine Industry" 5 "Industrial" ;
VAL_ 2583628544 Manufacturer_Code 69 "ARKS Enterprises" 78 "FW Murphy/Enovation Controls" 80 "Twin Disc" 85 "Kohler Power Systems" 88 "Hemisphere GPS" 135 "Airmar" 137 "Maretron" 140 "Lowrance" 144 "Mercury Marine" 147 "Nautibus Electronic" 148 "Blue Water Data" 154 "Westerbeke" 157 "ISSPRO" 161 "Offshore Systems (UK)" 163 "Evinrude/BRP" 165 "CPAC Systems" 168 "Xantrex Technology" 169 "Marlin Technologies" 172 "Yanmar Marine" 174 "Volvo Penta" 176 "Carling Technologies Inc. (Moritz Aerospace)" 185 "Beede Instruments" 192 "Floscan Instrument" 193 "Nobeltec" 198 "Mystic Valley Communications" 199 "Actia" 201 "Disenos Y Technologia" 211 "Digital Switching Systems" 215 "Xintex/Atena" 224 "EMMI NETWORK" 228 "ZF" 229 "Garmin" 233 "Yacht Monitoring Solutions" 235 "Sailormade Marine Telemetry/Tetra Technology" 243 "Eride" 257 "Honda Motor" 272 "Groco" 273 "Actisense" 274 "Amphenol LTW Technology" 275 "Navico" 283 "Hamilton Jet" 285 "Sea Recovery" 286 "Coelmo SRL Italy" 295 "BEP Marine" 304 "Empir Bus" 305 "NovAtel" 306 "Sleipner Motor" 307 "MBW Technologies" 315 "ICOM" 328 "Qwerty" 329 "Dief" 341 "Boening Automationstechnologie" 345 "Korean Maritime University" 351 "Thrane and Thrane" 355 "Mastervolt" 356 "Fischer Panda Generators" 358 "Victron Energy" 370 "Rolls Royce Marine" 373 "Electronic Design" 374 "Northern Lights" 378 "Glendinning" 381 "B & G" 384 "Rose Point Navigation Systems" 385 "Johnson Outdoors Marine Electronics Inc Geonav" 394 "Capi 2" 396 "Beyond Measure" 400 "Livorsi Marine" 404 "ComNav" 409 "Chetco" 419 "Fusion Electronics" 421 "Standard Horizon" 422 "True Heading" 426 "Egersund Marine Electronics" 427 "em-trak Marine Electronics" 431 "Tohatsu Co, JP" 437 "Digital Yacht" 438 "Comar Systems Limited" 440 "Cummins" 443 "VDO (aka Continental-Corporation)" 451 "Parker Hannifin aka Village Marine Tech" 459 "Alltek Marine Electronics" 460 "SAN GIORGIO S.E.I.N" 466 "Veethree Electronics & Marine" 470 "SI-TEX Marine Electronics" 471 "Sea Cross Marine" 475 "GME aka Standard Communications" 476 "Humminbird Marine Electronics" 478 "Ocean Sat" 481 "Chetco Digital Instruments" 493 "Watcheye" 499 "Lcj Capteurs" 502 "Attwood Marine" 503 "Naviop S.R.L." 504 "Vesper Marine" 510 "Marinesoft" 513 "Simarine" 517 "NoLand Engineering" 518 "Transas USA" 529 "National Instruments Korea" 530 "National Marine Electronics Association" 532 "Onwa Marine" 540 "Webasto" 571 "Marinecraft (South Korea)" 573 "McMurdo Group aka Orolia" 578 "Advansea" 579 "KVH" 580 "San Jose Technology" 583 "Yacht Control" 586 "Suzuki Motor" 591 "US Coast Guard" 595 "Ship Module aka Customware" 600 "Aquatic AV" 605 "Aventics" 606 "Intellian" 612 "SamwonIT" 614 "Arlt Tecnologies" 637 "Bavaria Yachts" 641 "Diverse Yacht Services" 644 "Wema U.S.A dba KUS" 658 "Shenzhen Jiuzhou Himunication" 688 "Rockford" 699 "Harman International" 704 "JL Audio" 708 "Lars Thrane" 715 "Autonnic" 717 "Yacht Devices" 734 "REAP Systems" 735 "AEM Performance Electronics" 739 "LxNav" 741 "Littelfuse, Inc (formerly Carling Technologies)" 743 "DaeMyung" 744 "Woosung" 748 "ISOTTA IFRA srl" 773 "Clarion US" 776 "HMI Systems" 777 "Ocean Signal" 778 "Seakeeper" 781 "Poly Planar" 785 "Fischer Panda DE" 795 "Broyda Industries" 796 "Canadian Automotive" 797 "Tides Marine" 798 "Lumishore" 799 "Still Water Designs and Audio" 802 "BJ Technologies (Beneteau)" 803 "Gill Sensors" 811 "Blue Water Desalination" 815 "FLIR" 824 "Undheim Systems" 826 "Lewmar" 838 "TeamSurv" 844 "Fell Marine" 847 "Oceanvolt" 862 "Prospec" 868 "Data Panel" 890 "L3 Technologies" 894 "Rhodan Marine Systems" 896 "Nexfour Solutions" 905 "ASA Electronics" 909 "Marines Co (South Korea)" 911 "Nautic-on" 917 "Sentinel" 929 "JL Marine Systems" 930 "Ecotronix" 944 "Zontisa Marine" 951 "EXOR International" 962 "Timbolier Industries" 963 "TJC Micro" 968 "Cox Powertrain" 969 "Blue Seas" 981 "Kobelt Manufacturing" 992 "Blue Ocean IOT" 997 "Xenta Systems" 999 "Signal K" 1004 "Ultraflex" 1008 "Lintest SmartBoat" 1011 "Soundmax" 1020 "Team Italia Marine (Onyx Marine Automation s.r.l)" 1021 "Entratech" 1022 "ITC" 1029 "The Marine Guardian" 1047 "Sonic" 1051 "ProNav" 1053 "Vetus Maxwell INC." 1056 "Lithium Pros" 1059 "Boatrax" 1062 "Marol Co ltd" 1065 "CALYPSO Instruments" 1066 "Spot Zero Water" 1069 "Lithionics Battery" 1070 "Quick-teck Electronics" 1075 "Uniden America" 1083 "Nauticoncept" 1084 "Shadow-Caster LED lighting" 1085 "Wet Sounds" 1088 "E-T-A Circuit Breakers" 1092 "Scheiber" 1100 "Smart Yachts International Limited" 1109 "Dockmate" 1114 "Bobs Machine" 1118 "L3Harris ASV" 1119 "Balmar" 1120 "Elettromedia" 1127 "Electromaax" 1140 "Across Oceans Systems" 1145 "Kiwi Yachting" 1150 "BSB Artificial Intelligence" 1151 "Orca Technologies" 1154 "TBS Electronics" 1158 "Technoton Electroics" 1160 "MG Energy Systems" 1169 "Sea Machine Robotics" 1171 "Vista Manufacturing" 1183 "Zipwake" 1186 "Sailmon" 1192 "Airmoniq Pro Kft" 1194 "Sierra Marine" 1200 "Xinuo Information Technology (Xiamen)" 1218 "Septentrio" 1233 "NKE Marine Electronics" 1238 "SuperTrack Aps" 1239 "Honda Electronics" 1245 "Raritan Engineering" 1249 "Integrated Power Solutions AG" 1260 "Interactive Technologies" 1283 "LTG-Tech" 1299 "Energy Solutions (UK)" 1300 "WATT Fuel Cell" 1302 "Pro Mainer" 1305 "Dragonfly Energy" 1306 "Koden Electronics" 1311 "Humphree" 1316 "Hinkley Yachts" 1317 "Global Marine Management GmbH (GMM)" 1320 "Triskel Marine" 1330 "Warwick Control Technologies" 1331 "Dolphin Charger" 1337 "Barnacle Systems" 1348 "Radian IoT" 1353 "Ocean LED Marine" 1359 "BluNav" 1361 "OVA (Nantong Saiyang Electronics Co., Ltd)" 1368 "RAD Propulsion" 1369 "Electric Yacht" 1372 "Elco Motor Yachts" 1384 "Tecnoseal Foundry S.r.l" 1385 "Pro Charging Systems" 1389 "EVEX" 1398 "Gobius Sensor Technology" 1403 "Arco Marine" 1408 "Lenco Marine" 1413 "Naocontrol" 1417 "Revatek" 1438 "Aeolionics" 1439 "PredictWind" 1440 "Egis Mobile Electric" 1445 "Starboard Yacht Group" 1446 "Roswell Marine" 1451 "ePropulsion (Guangdong ePropulsion Technology Ltd.)" 1452 "Micro-Air" 1453 "Vital Battery" 1458 "Ride Controller" 1460 "Tocaro Blue" 1461 "Vanquish Yachts" 1471 "FT Technologies" 1478 "Alps Alpine" 1481 "E-Force Marine" 1482 "CMC Marine" 1483 "Nanjing Sandemarine Information Technology" 1850 "Teleflex Marine (SeaStar Solutions)" 1851 "Raymarine" 1852 "Navionics" 1853 "Japan Radio" 1854 "Northstar Technologies" 1855 "Furuno" 1856 "Trimble" 1857 "Simrad" 1858 "Litton" 1859 "Kvasar" 1860 "MMP" 1861 "Vector Cantech" 1862 "Yamaha Marine" 1863 "Faria Instruments" ;
VAL_ 2583628544 Industry_Code 0 "Global" 1 "Highway" 2 "Agriculture" 3 "Construction" 4 "Marine Industry" 5 "Industrial" ;
VAL_ 2583628544 State 0 "Stowing or deploying" 1 "False" 10 "Ready" 11 "Thrusting" ;
VAL_ 2315193344 Manufacturer_Code 69 "ARKS Enterprises" 78 "FW Murphy/Enovation Controls" 80 "Twin Disc" 85 "Kohler Power Systems" 88 "Hemisphere GPS" 135 "Airmar" 137 "Maretron" 140 "Lowrance" 144 "Mercury Marine" 147 "Nautibus Electronic" 148 "Blue Water Data" 154 "Westerbeke" 157 "ISSPRO" 161 "Offshore Systems (UK)" 163 "Evinrude/BRP" 165 "CPAC Systems" 168 "Xantrex Technology" 169 "Marlin Technologies" 172 "Yanmar Marine" 174 "Volvo Penta" 176 "Carling Technologies Inc. (Moritz Aerospace)" 185 "Beede Instruments" 192 "Floscan Instrument" 193 "Nobeltec" 198 "Mystic Valley Communications" 199 "Actia" 201 "Disenos Y Technologia" 211 "Digital Switching Systems" 215 "Xintex/Atena" 224 "EMMI NETWORK" 228 "ZF" 229 "Garmin" 233 "Yacht Monitoring Solutions" 235 "Sailormade Marine Telemetry/Tetra Technology" 243 "Eride" 257 "Honda Motor" 272 "Groco" 273 "Actisense" 274 "Amphenol LTW Technology" 275 "Navico" 283 "Hamilton Jet" 285 "Sea Recovery" 286 "Coelmo SRL Italy" 295 "BEP Marine" 304 "Empir Bus" 305 "NovAtel" 306 "Sleipner Motor" 307 "MBW Technologies" 315 "ICOM" 328 "Qwerty" 329 "Dief" 341 "Boening Automationstechnologie" 345 "Korean Maritime University" 351 "Thrane and Thrane" 355 "Mastervolt" 356 "Fischer Panda Generators" 358 "Victron Energy" 370 "Rolls Royce Marine" 373 "Electronic Design" 374 "Northern Lights" 378 "Glendinning" 381 "B & G" 384 "Rose Point Navigation Systems" 385 "Johnson Outdoors Marine Electronics Inc Geonav" 394 "Capi 2" 396 "Beyond Measure" 400 "Livorsi Marine" 404 "ComNav" 409 "Chetco" 419 "Fusion Electronics" 421 "Standard Horizon" 422 "True Heading" 426 "Egersund Marine Electronics" 427 "em-trak Marine Electronics" 431 "Tohatsu Co, JP" 437 "Digital Yacht" 438 "Comar Systems Limited" 440 "Cummins" 443 "VDO (aka Continental-Corporation)" 451 "Parker Hannifin aka Village Marine Tech" 459 "Alltek Marine Electronics" 460 "SAN GIORGIO S.E.I.N" 466 "Veethree Electronics & Marine" 470 "SI-TEX Marine Electronics" 471 "Sea Cross Marine" 475 "GME aka Standard Communications" 476 "Humminbird Marine Electronics" 478 "Ocean Sat" 481 "Chetco Digital Instruments" 493 "Watcheye" 499 "Lcj Capteurs" 502 "Attwood Marine" 503 "Naviop S.R.L." 504 "Vesper Marine" 510 "Marinesoft" 513 "Simarine" 517 "NoLand Engineering" 518 "Transas USA" 529 "National Instruments Korea" 530 "National Marine Electronics Association" 532 "Onwa Marine" 540 "Webasto" 571 "Marinecraft (South Korea)" 573 "McMurdo Group aka Orolia" 578 "Advansea" 579 "KVH" 580 "San Jose Technology" 583 "Yacht Control" 586 "Suzuki Motor" 591 "US Coast Guard" 595 "Ship Module aka Customware" 600 "Aquatic AV" 605 "Aventics" 606 "Intellian" 612 "SamwonIT" 614 "Arlt Tecnologies" 637 "Bavaria Yachts" 641 "Diverse Yacht Services" 644 "Wema U.S.A dba KUS" 658 "Shenzhen Jiuzhou Himunication" 688 "Rockford" 699 "Harman International" 704 "JL Audio" 708 "Lars Thrane" 715 "Autonnic" 717 "Yacht Devices" 734 "REAP Systems" 735 "AEM Performance Electronics" 739 "LxNav" 741 "Littelfuse, Inc (formerly Carling Technologies)" 743 "DaeMyung" 744 "Woosung" 748 "ISOTTA IFRA srl" 773 "Clarion US" 776 "HMI Systems" 777 "Ocean Signal" 778 "Seakeeper" 781 "Poly Planar" 785 "Fischer Panda DE" 795 "Broyda Industries" 796 "Canadian Automotive" 797 "Tides Marine" 798 "Lumishore" 799 "Still Water Designs and Audio" 802 "BJ Technologies (Beneteau)" 803 "Gill Sensors" 811 "Blue Water Desalination" 815 "FLIR" 824 "Undheim Systems" 826 "Lewmar" 838 "TeamSurv" 844 "Fell Marine" 847 "Oceanvolt" 862 "Prospec" 868 "Data Panel" 890 "L3 Technologies" 894 "Rhodan Marine Systems" 896 "Nexfour Solutions" 905 "ASA Electronics" 909 "Marines Co (South Korea)" 911 "Nautic-on" 917 "Sentinel" 929 "JL Marine Systems" 930 "Ecotronix" 944 "Zontisa Marine" 951 "EXOR International" 962 "Timbolier Industries" 963 "TJC Micro" 968 "Cox Powertrain" 969 "Blue Seas" 981 "Kobelt Manufacturing" 992 "Blue Ocean IOT" 997 "Xenta Systems" 999 "Signal K" 1004 "Ultraflex" 1008 "Lintest SmartBoat" 1011 "Soundmax" 1020 "Team Italia Marine (Onyx Marine Automation s.r.l)" 1021 "Entratech" 1022 "ITC" 1029 "The Marine Guardian" 1047 "Sonic" 1051 "ProNav" 1053 "Vetus Maxwell INC." 1056 "Lithium Pros" 1059 "Boatrax" 1062 "Marol Co ltd" 1065 "CALYPSO Instruments" 1066 "Spot Zero Water" 1069 "Lithionics Battery" 1070 "Quick-teck Electronics" 1075 "Uniden America" 1083 "Nauticoncept" 1084 "Shadow-Caster LED lighting" 1085 "Wet Sounds" 1088 "E-T-A Circuit Breakers" 1092 "Scheiber" 1100 "Smart Yachts International Limited" 1109 "Dockmate" 1114 "Bobs Machine" 1118 "L3Harris ASV" 1119 "Balmar" 1120 "Elettromedia" 1127 "Electromaax" 1140 "Across Oceans Systems" 1145 "Kiwi Yachting" 1150 "BSB Artificial Intelligence" 1151 "Orca Technologies" 1154 "TBS Electronics" 1158 "Technoton Electroics" 1160 "MG Energy Systems" 1169 "Sea Machine Robotics" 1171 "Vista Manufacturing" 1183 "Zipwake" 1186 "Sailmon" 1192 "Airmoniq Pro Kft" 1194 "Sierra Marine" 1200 "Xinuo Information Technology (Xiamen)" 1218 "Septentrio" 1233 "NKE Marine Electronics" 1238 "SuperTrack Aps" 1239 "Honda Electronics" 1245 "Raritan Engineering" 1249 "Integrated Power Solutions AG" 1260 "Interactive Technologies" 1283 "LTG-Tech" 1299 "Energy Solutions (UK)" 1300 "WATT Fuel Cell" 1302 "Pro Mainer" 1305 "Dragonfly Energy" 1306 "Koden Electronics" 1311 "Humphree" 1316 "Hinkley Yachts" 1317 "Global Marine Management GmbH (GMM)" 1320 "Triskel Marine" 1330 "Warwick Control Technologies" 1331 "Dolphin Charger" 1337 "Barnacle Systems" 1348 "Radian IoT" 1353 "Ocean LED Marine" 1359 "BluNav" 1361 "OVA (Nantong Saiyang Electronics Co., Ltd)" 1368 "RAD Propulsion" 1369 "Electric Yacht" 1372 "Elco Motor Yachts" 1384 "Tecnoseal Foundry S.r.l" 1385 "Pro Charging Systems" 1389 "EVEX" 1398 "Gobius Sensor Technology" 1403 "Arco Marine" 1408 "Lenco Marine" 1413 "Naocontrol" 1417 "Revatek" 1438 "Aeolionics" 1439 "PredictWind" 1440 "Egis Mobile Electric" 1445 "Starboard Yacht Group" 1446 "Roswell Marine" 1451 "ePropulsion (Guangdong ePropulsion Technology Ltd.)" 1452 "Micro-Air" 1453 "Vital Battery" 1458 "Ride Controller" 1460 "Tocaro Blue" 1461 "Vanquish Yachts" 1471 "FT Technologies" 1478 "Alps Alpine" 1481 "E-Force Marine" 1482 "CMC Marine" 1483 "Nanjing Sandemarine Information Technology" 1850 "Teleflex Marine (SeaStar Solutions)" 1851 "Raymarine" 1852 "Navionics" 1853 "Japan Radio" 1854 "Northstar Technologies" 1855 "Furuno" 1856 "Trimble" 1857 "Simrad" 1858 "Litton" 1859 "Kvasar" 1860 "MMP" 1861 "Vector Cantech" 1862 "Yamaha Marine" 1863 "Faria Instruments" ;
VAL_ 2315193344 Industry_Code 0 "Global" 1 "Highway" 2 "Agriculture" 3 "Construction" 4 "Marine Industry" 5 "Industrial" ;
VAL_ 2583628800 Manufacturer_Code 69 "ARKS Enterprises" 78 "FW Murphy/Enovation Controls" 80 "Twin Disc" 85 "Kohler Power Systems" 88 "Hemisphere GPS" 135 "Airmar" 137 "Maretron" 140 "Lowrance" 144 "Mercury Marine" 147 "Nautibus Electronic" 148 "Blue Water Data" 154 "Westerbeke" 157 "ISSPRO" 161 "Offshore Systems (UK)" 163 "Evinrude/BRP" 165 "CPAC Systems" 168 "Xantrex Technology" 169 "Marlin Technologies" 172 "Yanmar Marine" 174 "Volvo Penta" 176 "Carling Technologies Inc. (Moritz Aerospace)" 185 "Beede Instruments" 192 "Floscan Instrument" 193 "Nobeltec" 198 "Mystic Valley Communications" 199 "Actia" 201 "Disenos Y Technologia" 211 "Digital Switching Systems" 215 "Xintex/Atena" 224 "EMMI NETWORK" 228 "ZF" 229 "Garmin" 233 "Yacht Monitoring Solutions" 235 "Sailormade Marine Telemetry/Tetra Technology" 243 "Eride" 257 "Honda Motor" 272 "Groco" 273 "Actisense" 274 "Amphenol LTW Technology" 275 "Navico" 283 "Hamilton Jet" 285 "Sea Recovery" 286 "Coelmo SRL Italy" 295 "BEP Marine" 304 "Empir Bus" 305 "NovAtel" 306 "Sleipner Motor" 307 "MBW Technologies" 315 "ICOM" 328 "Qwerty" 329 "Dief" 341 "Boening Automationstechnologie" 345 "Korean Maritime University" 351 "Thrane and Thrane" 355 "Mastervolt" 356 "Fischer Panda Generators" 358 "Victron Energy" 370 "Rolls Royce Marine" 373 "Electronic Design" 374 "Northern Lights" 378 "Glendinning" 381 "B & G" 384 "Rose Point Navigation Systems" 385 "Johnson Outdoors Marine Electronics Inc Geonav" 394 "Capi 2" 396 "Beyond Measure" 400 "Livorsi Marine" 404 "ComNav" 409 "Chetco" 419 "Fusion Electronics" 421 "Standard Horizon" 422 "True Heading" 426 "Egersund Marine Electronics" 427 "em-trak Marine Electronics" 431 "Tohatsu Co, JP" 437 "Digital Yacht" 438 "Comar Systems Limited" 440 "Cummins" 443 "VDO (aka Continental-Corporation)" 451 "Parker Hannifin aka Village Marine Tech" 459 "Alltek Marine Electronics" 460 "SAN GIORGIO S.E.I.N" 466 "Veethree Electronics & Marine" 470 "SI-TEX Marine Electronics" 471 "Sea Cross Marine" 475 "GME aka Standard Communications" 476 "Humminbird Marine Electronics" 478 "Ocean Sat" 481 "Chetco Digital Instruments" 493 "Watcheye" 499 "Lcj Capteurs" 502 "Attwood Marine" 503 "Naviop S.R.L." 504 "Vesper Marine" 510 "Marinesoft" 513 "Simarine" 517 "NoLand Engineering" 518 "Transas USA" 529 "National Instruments Korea" 530 "National Marine Electronics Association" 532 "Onwa Marine" 540 "Webasto" 571 "Marinecraft (South Korea)" 573 "McMurdo Group aka Orolia" 578 "Advansea" 579 "KVH" 580 "San Jose Technology" 583 "Yacht Control" 586 "Suzuki Motor" 591 "US Coast Guard" 595 "Ship Module aka Customware" 600 "Aquatic AV" 605 "Aventics" 606 "Intellian" 612 "SamwonIT" 614 "Arlt Tecnologies" 637 "Bavaria Yachts" 641 "Diverse Yacht Services" 644 "Wema U.S.A dba KUS" 658 "Shenzhen Jiuzhou Himunication" 688 "Rockford" 699 "Harman International" 704 "JL Audio" 708 "Lars Thrane" 715 "Autonnic" 717 "Yacht Devices" 734 "REAP Systems" 735 "AEM Performance Electronics" 739 "LxNav" 741 "Littelfuse, Inc (formerly Carling Technologies)" 743 "DaeMyung" 744 "Woosung" 748 "ISOTTA IFRA srl" 773 "Clarion US" 776 "HMI Systems" 777 "Ocean Signal" 778 "Seakeeper" 781 "Poly Planar" 785 "Fischer Panda DE" 795 "Broyda Industries" 796 "Canadian Automotive" 797 "Tides Marine" 798 "Lumishore" 799 "Still Water Designs and Audio" 802 "BJ Technologies (Beneteau)" 803 "Gill Sensors" 811 "Blue Water Desalination" 815 "FLIR" 824 "Undheim Systems" 826 "Lewmar" 838 "TeamSurv" 844 "Fell Marine" 847 "Oceanvolt" 862 "Prospec" 868 "Data Panel" 890 "L3 Technologies" 894 "Rhodan Marine Systems" 896 "Nexfour Solutions" 905 "ASA Electronics" 909 "Marines Co (South Korea)" 911 "Nautic-on" 917 "Sentinel" 929 "JL Marine Systems" 930 "Ecotronix" 944 "Zontisa Marine" 951 "EXOR International" 962 "Timbolier Industries" 963 "TJC Micro" 968 "Cox Powertrain" 969 "Blue Seas" 981 "Kobelt Manufacturing" 992 "Blue Ocean IOT" 997 "Xenta Systems" 999 "Signal K" 1004 "Ultraflex" 1008 "Lintest SmartBoat" 1011 "Soundmax" 1020 "Team Italia Marine (Onyx Marine Automation s.r.l)" 1021 "Entratech" 1022 "ITC" 1029 "The Marine Guardian" 1047 "Sonic" 1051 "ProNav" 1053 "Vetus Maxwell INC." 1056 "Lithium Pros" 1059 "Boatrax" 1062 "Marol Co ltd" 1065 "CALYPSO Instruments" 1066 "Spot Zero Water" 1069 "Lithionics Battery" 1070 "Quick-teck Electronics" 1075 "Uniden America" 1083 "Nauticoncept" 1084 "Shadow-Caster LED lighting" 1085 "Wet Sounds" 1088 "E-T-A Circuit Breakers" 1092 "Scheiber" 1100 "Smart Yachts International Limited" 1109 "Dockmate" 1114 "Bobs Machine" 1118 "L3Harris ASV" 1119 "Balmar" 1120 "Elettromedia" 1127 "Electromaax" 1140 "Across Oceans Systems" 1145 "Kiwi Yachting" 1150 "BSB Artificial Intelligence" 1151 "Orca Technologies" 1154 "TBS Electronics" 1158 "Technoton Electroics" 1160 "MG Energy Systems" 1169 "Sea Machine Robotics" 1171 "Vista Manufacturing" 1183 "Zipwake" 1186 "Sailmon" 1192 "Airmoniq Pro Kft" 1194 "Sierra Marine" 1200 "Xinuo Information Technology (Xiamen)" 1218 "Septentrio" 1233 "NKE Marine Electronics" 1238 "SuperTrack Aps" 1239 "Honda Electronics" 1245 "Raritan Engineering" 1249 "Integrated Power Solutions AG" 1260 "Interactive Technologies" 1283 "LTG-Tech" 1299 "Energy Solutions (UK)" 1300 "WATT Fuel Cell" 1302 "Pro Mainer" 1305 "Dragonfly Energy" 1306 "Koden Electronics" 1311 "Humphree" 1316 "Hinkley Yachts" 1317 "Global Marine Management GmbH (GMM)" 1320 "Triskel Marine" 1330 "Warwick Control Technologies" 1331 "Dolphin Charger" 1337 "Barnacle Systems" 1348 "Radian IoT" 1353 "Ocean LED Marine" 1359 "BluNav" 1361 "OVA (Nantong Saiyang Electronics Co., Ltd)" 1368 "RAD Propulsion" 1369 "Electric Yacht" 1372 "Elco Motor Yachts" 1384 "Tecnoseal Foundry S.r.l" 1385 "Pro Charging Systems" 1389 "EVEX" 1398 "Gobius Sensor Technology" 1403 "Arco Marine" 1408 "Lenco Marine" 1413 "Naocontrol" 1417 "Revatek" 1438 "Aeolionics" 1439 "PredictWind" 1440 "Egis Mobile Electric" 1445 "Starboard Yacht Group" 1446 "Roswell Marine" 1451 "ePropulsion (Guangdong ePropulsion Technology Ltd.)" 1452 "Micro-Air" 1453 "Vital Battery" 1458 "Ride Controller" 1460 "Tocaro Blue" 1461 "Vanquish Yachts" 1471 "FT Technologies" 1478 "Alps Alpine" 1481 "E-Force Marine" 1482 "CMC Marine" 1483 "Nanjing Sandemarine Information Technology" 1850 "Teleflex Marine (SeaStar Solutions)" 1851 "Raymarine" 1852 "Navionics" 1853 "Japan Radio" 1854 "Northstar Technologies" 1855 "Furuno" 1856 "Trimble" 1857 "Simrad" 1858 "Litton" 1859 "Kvasar" 1860 "MMP" 1861 "Vector Cantech" 1862 "Yamaha Marine" 1863 "Faria Instruments" ;
VAL_ 2583628800 Industry_Code 0 "Global" 1 "Highway" 2 "Agriculture" 3 "Construction" 4 "Marine Industry" 5 "Industrial" ;
VAL_ 2583628800 Manufacturer_Code 69 "ARKS Enterprises" 78 "FW Murphy/Enovation Controls" 80 "Twin Disc" 85 "Kohler Power Systems" 88 "Hemisphere GPS" 135 "Airmar" 137 "Maretron" 140 "Lowrance" 144 "Mercury Marine" 147 "Nautibus Electronic" 148 "Blue Water Data" 154 "Westerbeke" 157 "ISSPRO" 161 "Offshore Systems (UK)" 163 "Evinrude/BRP" 165 "CPAC Systems" 168 "Xantrex Technology" 169 "Marlin Technologies" 172 "Yanmar Marine" 174 "Volvo Penta" 176 "Carling Technologies Inc. (Moritz Aerospace)" 185 "Beede Instruments" 192 "Floscan Instrument" 193 "Nobeltec" 198 "Mystic Valley Communications" 199 "Actia" 201 "Disenos Y Technologia" 211 "Digital Switching Systems" 215 "Xintex/Atena" 224 "EMMI NETWORK" 228 "ZF" 229 "Garmin" 233 "Yacht Monitoring Solutions" 235 "Sailormade Marine Telemetry/Tetra Technology" 243 "Eride" 257 "Honda Motor" 272 "Groco" 273 "Actisense" 274 "Amphenol LTW Technology" 275 "Navico" 283 "Hamilton Jet" 285 "Sea Recovery" 286 "Coelmo SRL Italy" 295 "BEP Marine" 304 "Empir Bus" 305 "NovAtel" 306 "Sleipner Motor" 307 "MBW Technologies" 315 "ICOM" 328 "Qwerty" 329 "Dief" 341 "Boening Automationstechnologie" 345 "Korean Maritime University" 351 "Thrane and Thrane" 355 "Mastervolt" 356 "Fischer Panda Generators" 358 "Victron Energy" 370 "Rolls Royce Marine" 373 "Electronic Design" 374 "Northern Lights" 378 "Glendinning" 381 "B & G" 384 "Rose Point Navigation Systems" 385 "Johnson Outdoors Marine Electronics Inc Geonav" 394 "Capi 2" 396 "Beyond Measure" 400 "Livorsi Marine" 404 "ComNav" 409 "Chetco" 419 "Fusion Electronics" 421 "Standard Horizon" 422 "True Heading" 426 "Egersund Marine Electronics" 427 "em-trak Marine Electronics" 431 "Tohatsu Co, JP" 437 "Digital Yacht" 438 "Comar Systems Limited" 440 "Cummins" 443 "VDO (aka Continental-Corporation)" 451 "Parker Hannifin aka Village Marine Tech" 459 "Alltek Marine Electronics" 460 "SAN GIORGIO S.E.I.N" 466 "Veethree Electronics & Marine" 470 "SI-TEX Marine Electronics" 471 "Sea Cross Marine" 475 "GME aka Standard Communications" 476 "Humminbird Marine Electronics" 478 "Ocean Sat" 481 "Chetco Digital Instruments" 493 "Watcheye" 499 "Lcj Capteurs" 502 "Attwood Marine" 503 "Naviop S.R.L." 504 "Vesper Marine" 510 "Marinesoft" 513 "Simarine" 517 "NoLand Engineering" 518 "Transas USA" 529 "National Instruments Korea" 530 "National Marine Electronics Association" 532 "Onwa Marine" 540 "Webasto" 571 "Marinecraft (South Korea)" 573 "McMurdo Group aka Orolia" 578 "Advansea" 579 "KVH" 580 "San Jose Technology" 583 "Yacht Control" 586 "Suzuki Motor" 591 "US Coast Guard" 595 "Ship Module aka Customware" 600 "Aquatic AV" 605 "Aventics" 606 "Intellian" 612 "SamwonIT" 614 "Arlt Tecnologies" 637 "Bavaria Yachts" 641 "Diverse Yacht Services" 644 "Wema U.S.A dba KUS" 658 "Shenzhen Jiuzhou Himunication" 688 "Rockford" 699 "Harman International" 704 "JL Audio" 708 "Lars Thrane" 715 "Autonnic" 717 "Yacht Devices" 734 "REAP Systems" 735 "AEM Performance Electronics" 739 "LxNav" 741 "Littelfuse, Inc (formerly Carling Technologies)" 743 "DaeMyung" 744 "Woosung" 748 "ISOTTA IFRA srl" 773 "Clarion US" 776 "HMI Systems" 777 "Ocean Signal" 778 "Seakeeper" 781 "Poly Planar" 785 "Fischer Panda DE" 795 "Broyda Industries" 796 "Canadian Automotive" 797 "Tides Marine" 798 "Lumishore" 799 "Still Water Designs and Audio" 802 "BJ Technologies (Beneteau)" 803 "Gill Sensors" 811 "Blue Water Desalination" 815 "FLIR" 824 "Undheim Systems" 826 "Lewmar" 838 "TeamSurv" 844 "Fell Marine" 847 "Oceanvolt" 862 "Prospec" 868 "Data Panel" 890 "L3 Technologies" 894 "Rhodan Marine Systems" 896 "Nexfour Solutions" 905 "ASA Electronics" 909 "Marines Co (South Korea)" 911 "Nautic-on" 917 "Sentinel" 929 "JL Marine Systems" 930 "Ecotronix" 944 "Zontisa Marine" 951 "EXOR International" 962 "Timbolier Industries" 963 "TJC Micro" 968 "Cox Powertrain" 969 "Blue Seas" 981 "Kobelt Manufacturing" 992 "Blue Ocean IOT" 997 "Xenta Systems" 999 "Signal K" 1004 "Ultraflex" 1008 "Lintest SmartBoat" 1011 "Soundmax" 1020 "Team Italia Marine (Onyx Marine Automation s.r.l)" 1021 "Entratech" 1022 "ITC" 1029 "The Marine Guardian" 1047 "Sonic" 1051 "ProNav" 1053 "Vetus Maxwell INC." 1056 "Lithium Pros" 1059 "Boatrax" 1062 "Marol Co ltd" 1065 "CALYPSO Instruments" 1066 "Spot Zero Water" 1069 "Lithionics Battery" 1070 "Quick-teck Electronics" 1075 "Uniden America" 1083 "Nauticoncept" 1084 "Shadow-Caster LED lighting" 1085 "Wet Sounds" 1088 "E-T-A Circuit Breakers" 1092 "Scheiber" 1100 "Smart Yachts International Limited" 1109 "Dockmate" 1114 "Bobs Machine" 1118 "L3Harris ASV" 1119 "Balmar" 1120 "Elettromedia" 1127 "Electromaax" 1140 "Across Oceans Systems" 1145 "Kiwi Yachting" 1150 "BSB Artificial Intelligence" 1151 "Orca Technologies" 1154 "TBS Electronics" 1158 "Technoton Electroics" 1160 "MG Energy Systems" 1169 "Sea Machine Robotics" 1171 "Vista Manufacturing" 1183 "Zipwake" 1186 "Sailmon" 1192 "Airmoniq Pro Kft" 1194 "Sierra Marine" 1200 "Xinuo Information Technology (Xiamen)" 1218 "Septentrio" 1233 "NKE Marine Electronics" 1238 "SuperTrack Aps" 1239 "Honda Electronics" 1245 "Raritan Engineering" 1249 "Integrated Power Solutions AG" 1260 "Interactive Technologies" 1283 "LTG-Tech" 1299 "Energy Solutions (UK)" 1300 "WATT Fuel Cell" 1302 "Pro Mainer" 1305 "Dragonfly Energy" 1306 "Koden Electronics" 1311 "Humphree" 1316 "Hinkley Yachts" 1317 "Global Marine Management GmbH (GMM)" 1320 "Triskel Marine" 1330 "Warwick Control Technologies" 1331 "Dolphin Charger" 1337 "Barnacle Systems" 1348 "Radian IoT" 1353 "Ocean LED Marine" 1359 "BluNav" 1361 "OVA (Nantong Saiyang Electronics Co., Ltd)" 1368 "RAD Propulsion" 1369 "Electric Yacht" 1372 "Elco Motor Yachts" 1384 "Tecnoseal Foundry S.r.l" 1385 "Pro Charging Systems" 1389 "EVEX" 1398 "Gobius Sensor Technology" 1403 "Arco Marine" 1408 "Lenco Marine" 1413 "Naocontrol" 1417 "Revatek" 1438 "Aeolionics" 1439 "PredictWind" 1440 "Egis Mobile Electric" 1445 "Starboard Yacht Group" 1446 "Roswell Marine" 1451 "ePropulsion (Guangdong ePropulsion Technology Ltd.)" 1452 "Micro-Air" 1453 "Vital Battery" 1458 "Ride Controller" 1460 "Tocaro Blue" 1461 "Vanquish Yachts" 1471 "FT Technologies" 1478 "Alps Alpine" 1481 "E-Force Marine" 1482 "CMC Marine" 1483 "Nanjing Sandemarine Information Technology" 1850 "Teleflex Marine (SeaStar Solutions)" 1851 "Raymarine" 1852 "Navionics" 1853 "Japan Radio" 1854 "Northstar Technologies" 1855 "Furuno" 1856 "Trimble" 1857 "Simrad" 1858 "Litton" 1859 "Kvasar" 1860 "MMP" 1861 "Vector Cantech" 1862 "Yamaha Marine" 1863 "Faria Instruments" ;
VAL_ 2583628800 Industry_Code 0 "Global" 1 "Highway" 2 "Agriculture" 3 "Construction" 4 "Marine Industry" 5 "Industrial" ;
VAL_ 2583628800 State 0 "Stowing or deploying" 1 "False" 10 "Ready" 11 "Thrusting" ;
VAL_ 2650737920 Manufacturer_Code 69 "ARKS Enterprises" 78 "FW Murphy/Enovation Controls" 80 "Twin Disc" 85 "Kohler Power Systems" 88 "Hemisphere GPS" 135 "Airmar" 137 "Maretron" 140 "Lowrance" 144 "Mercury Marine" 147 "Nautibus Electronic" 148 "Blue Water Data" 154 "Westerbeke" 157 "ISSPRO" 161 "Offshore Systems (UK)" 163 "Evinrude/BRP" 165 "CPAC Systems" 168 "Xantrex Technology" 169 "Marlin Technologies" 172 "Yanmar Marine" 174 "Volvo Penta" 176 "Carling Technologies Inc. (Moritz Aerospace)" 185 "Beede Instruments" 192 "Floscan Instrument" 193 "Nobeltec" 198 "Mystic Valley Communications" 199 "Actia" 201 "Disenos Y Technologia" 211 "Digital Switching Systems" 215 "Xintex/Atena" 224 "EMMI NETWORK" 228 "ZF" 229 "Garmin" 233 "Yacht Monitoring Solutions" 235 "Sailormade Marine Telemetry/Tetra Technology" 243 "Eride" 257 "Honda Motor" 272 "Groco" 273 "Actisense" 274 "Amphenol LTW Technology" 275 "Navico" 283 "Hamilton Jet" 285 "Sea Recovery" 286 "Coelmo SRL Italy" 295 "BEP Marine" 304 "Empir Bus" 305 "NovAtel" 306 "Sleipner Motor" 307 "MBW Technologies" 315 "ICOM" 328 "Qwerty" 329 "Dief" 341 "Boening Automationstechnologie" 345 "Korean Maritime University" 351 "Thrane and Thrane" 355 "Mastervolt" 356 "Fischer Panda Generators" 358 "Victron Energy" 370 "Rolls Royce Marine" 373 "Electronic Design" 374 "Northern Lights" 378 "Glendinning" 381 "B & G" 384 "Rose Point Navigation Systems" 385 "Johnson Outdoors Marine Electronics Inc Geonav" 394 "Capi 2" 396 "Beyond Measure" 400 "Livorsi Marine" 404 "ComNav" 409 "Chetco" 419 "Fusion Electronics" 421 "Standard Horizon" 422 "True Heading" 426 "Egersund Marine Electronics" 427 "em-trak Marine Electronics" 431 "Tohatsu Co, JP" 437 "Digital Yacht" 438 "Comar Systems Limited" 440 "Cummins" 443 "VDO (aka Continental-Corporation)" 451 "Parker Hannifin aka Village Marine Tech" 459 "Alltek Marine Electronics" 460 "SAN GIORGIO S.E.I.N" 466 "Veethree Electronics & Marine" 470 "SI-TEX Marine Electronics" 471 "Sea Cross Marine" 475 "GME aka Standard Communications" 476 "Humminbird Marine Electronics" 478 "Ocean Sat" 481 "Chetco Digital Instruments" 493 "Watcheye" 499 "Lcj Capteurs" 502 "Attwood Marine" 503 "Naviop S.R.L." 504 "Vesper Marine" 510 "Marinesoft" 513 "Simarine" 517 "NoLand Engineering" 518 "Transas USA" 529 "National Instruments Korea" 530 "National Marine Electronics Association" 532 "Onwa Marine" 540 "Webasto" 571 "Marinecraft (South Korea)" 573 "McMurdo Group aka Orolia" 578 "Advansea" 579 "KVH" 580 "San Jose Technology" 583 "Yacht Control" 586 "Suzuki Motor" 591 "US Coast Guard" 595 "Ship Module aka Customware" 600 "Aquatic AV" 605 "Aventics" 606 "Intellian" 612 "SamwonIT" 614 "Arlt Tecnologies" 637 "Bavaria Yachts" 641 "Diverse Yacht Services" 644 "Wema U.S.A dba KUS" 658 "Shenzhen Jiuzhou Himunication" 688 "Rockford" 699 "Harman International" 704 "JL Audio" 708 "Lars Thrane" 715 "Autonnic" 717 "Yacht Devices" 734 "REAP Systems" 735 "AEM Performance Electronics" 739 "LxNav" 741 "Littelfuse, Inc (formerly Carling Technologies)" 743 "DaeMyung" 744 "Woosung" 748 "ISOTTA IFRA srl" 773 "Clarion US" 776 "HMI Systems" 777 "Ocean Signal" 778 "Seakeeper" 781 "Poly Planar" 785 "Fischer Panda DE" 795 "Broyda Industries" 796 "Canadian Automotive" 797 "Tides Marine" 798 "Lumishore" 799 "Still Water Designs and Audio" 802 "BJ Technologies (Beneteau)" 803 "Gill Sensors" 811 "Blue Water Desalination" 815 "FLIR" 824 "Undheim Systems" 826 "Lewmar" 838 "TeamSurv" 844 "Fell Marine" 847 "Oceanvolt" 862 "Prospec" 868 "Data Panel" 890 "L3 Technologies" 894 "Rhodan Marine Systems" 896 "Nexfour Solutions" 905 "ASA Electronics" 909 "Marines Co (South Korea)" 911 "Nautic-on" 917 "Sentinel" 929 "JL Marine Systems" 930 "Ecotronix" 944 "Zontisa Marine" 951 "EXOR International" 962 "Timbolier Industries" 963 "TJC Micro" 968 "Cox Powertrain" 969 "Blue Seas" 981 "Kobelt Manufacturing" 992 "Blue Ocean IOT" 997 "Xenta Systems" 999 "Signal K" 1004 "Ultraflex" 1008 "Lintest SmartBoat" 1011 "Soundmax" 1020 "Team Italia Marine (Onyx Marine Automation s.r.l)" 1021 "Entratech" 1022 "ITC" 1029 "The Marine Guardian" 1047 "Sonic" 1051 "ProNav" 1053 "Vetus Maxwell INC." 1056 "Lithium Pros" 1059 "Boatrax" 1062 "Marol Co ltd" 1065 "CALYPSO Instruments" 1066 "Spot Zero Water" 1069 "Lithionics Battery" 1070 "Quick-teck Electronics" 1075 "Uniden America" 1083 "Nauticoncept" 1084 "Shadow-Caster LED lighting" 1085 "Wet Sounds" 1088 "E-T-A Circuit Breakers" 1092 "Scheiber" 1100 "Smart Yachts International Limited" 1109 "Dockmate" 1114 "Bobs Machine" 1118 "L3Harris ASV" 1119 "Balmar" 1120 "Elettromedia" 1127 "Electromaax" 1140 "Across Oceans Systems" 1145 "Kiwi Yachting" 1150 "BSB Artificial Intelligence" 1151 "Orca Technologies" 1154 "TBS Electronics" 1158 "Technoton Electroics" 1160 "MG Energy Systems" 1169 "Sea Machine Robotics" 1171 "Vista Manufacturing" 1183 "Zipwake" 1186 "Sailmon" 1192 "Airmoniq Pro Kft" 1194 "Sierra Marine" 1200 "Xinuo Information Technology (Xiamen)" 1218 "Septentrio" 1233 "NKE Marine Electronics" 1238 "SuperTrack Aps" 1239 "Honda Electronics" 1245 "Raritan Engineering" 1249 "Integrated Power Solutions AG" 1260 "Interactive Technologies" 1283 "LTG-Tech" 1299 "Energy Solutions (UK)" 1300 "WATT Fuel Cell" 1302 "Pro Mainer" 1305 "Dragonfly Energy" 1306 "Koden Electronics" 1311 "Humphree" 1316 "Hinkley Yachts" 1317 "Global Marine Management GmbH (GMM)" 1320 "Triskel Marine" 1330 "Warwick Control Technologies" 1331 "Dolphin Charger" 1337 "Barnacle Systems" 1348 "Radian IoT" 1353 "Ocean LED Marine" 1359 "BluNav" 1361 "OVA (Nantong Saiyang Electronics Co., Ltd)" 1368 "RAD Propulsion" 1369 "Electric Yacht" 1372 "Elco Motor Yachts" 1384 "Tecnoseal Foundry S.r.l" 1385 "Pro Charging Systems" 1389 "EVEX" 1398 "Gobius Sensor Technology" 1403 "Arco Marine" 1408 "Lenco Marine" 1413 "Naocontrol" 1417 "Revatek" 1438 "Aeolionics" 1439 "PredictWind" 1440 "Egis Mobile Electric" 1445 "Starboard Yacht Group" 1446 "Roswell Marine" 1451 "ePropulsion (Guangdong ePropulsion Technology Ltd.)" 1452 "Micro-Air" 1453 "Vital Battery" 1458 "Ride Controller" 1460 "Tocaro Blue" 1461 "Vanquish Yachts" 1471 "FT Technologies" 1478 "Alps Alpine" 1481 "E-Force Marine" 1482 "CMC Marine" 1483 "Nanjing Sandemarine Information Technology" 1850 "Teleflex Marine (SeaStar Solutions)" 1851 "Raymarine" 1852 "Navionics" 1853 "Japan Radio" 1854 "Northstar Technologies" 1855 "Furuno" 1856 "Trimble" 1857 "Simrad" 1858 "Litton" 1859 "Kvasar" 1860 "MMP" 1861 "Vector Cantech" 1862 "Yamaha Marine" 1863 "Faria Instruments" ;
VAL_ 2650737920 Industry_Code 0 "Global" 1 "Highway" 2 "Agriculture" 3 "Construction" 4 "Marine Industry" 5 "Industrial" ;
VAL_ 2516520448 Manufacturer_Code 69 "ARKS Enterprises" 78 "FW Murphy/Enovation Controls" 80 "Twin Disc" 85 "Kohler Power Systems" 88 "Hemisphere GPS" 135 "Airmar" 137 "Maretron" 140 "Lowrance" 144 "Mercury Marine" 147 "Nautibus Electronic" 148 "Blue Water Data" 154 "Westerbeke" 157 "ISSPRO" 161 "Offshore Systems (UK)" 163 "Evinrude/BRP" 165 "CPAC Systems" 168 "Xantrex Technology" 169 "Marlin Technologies" 172 "Yanmar Marine" 174 "Volvo Penta" 176 "Carling Technologies Inc. (Moritz Aerospace)" 185 "Beede Instruments" 192 "Floscan Instrument" 193 "Nobeltec" 198 "Mystic Valley Communications" 199 "Actia" 201 "Disenos Y Technologia" 211 "Digital Switching Systems" 215 "Xintex/Atena" 224 "EMMI NETWORK" 228 "ZF" 229 "Garmin" 233 "Yacht Monitoring Solutions" 235 "Sailormade Marine Telemetry/Tetra Technology" 243 "Eride" 257 "Honda Motor" 272 "Groco" 273 "Actisense" 274 "Amphenol LTW Technology" 275 "Navico" 283 "Hamilton Jet" 285 "Sea Recovery" 286 "Coelmo SRL Italy" 295 "BEP Marine" 304 "Empir Bus" 305 "NovAtel" 306 "Sleipner Motor" 307 "MBW Technologies" 315 "ICOM" 328 "Qwerty" 329 "Dief" 341 "Boening Automationstechnologie" 345 "Korean Maritime University" 351 "Thrane and Thrane" 355 "Mastervolt" 356 "Fischer Panda Generators" 358 "Victron Energy" 370 "Rolls Royce Marine" 373 "Electronic Design" 374 "Northern Lights" 378 "Glendinning" 381 "B & G" 384 "Rose Point Navigation Systems" 385 "Johnson Outdoors Marine Electronics Inc Geonav" 394 "Capi 2" 396 "Beyond Measure" 400 "Livorsi Marine" 404 "ComNav" 409 "Chetco" 419 "Fusion Electronics" 421 "Standard Horizon" 422 "True Heading" 426 "Egersund Marine Electronics" 427 "em-trak Marine Electronics" 431 "Tohatsu Co, JP" 437 "Digital Yacht" 438 "Comar Systems Limited" 440 "Cummins" 443 "VDO (aka Continental-Corporation)" 451 "Parker Hannifin aka Village Marine Tech" 459 "Alltek Marine Electronics" 460 "SAN GIORGIO S.E.I.N" 466 "Veethree Electronics & Marine" 470 "SI-TEX Marine Electronics" 471 "Sea Cross Marine" 475 "GME aka Standard Communications" 476 "Humminbird Marine Electronics" 478 "Ocean Sat" 481 "Chetco Digital Instruments" 493 "Watcheye" 499 "Lcj Capteurs" 502 "Attwood Marine" 503 "Naviop S.R.L." 504 "Vesper Marine" 510 "Marinesoft" 513 "Simarine" 517 "NoLand Engineering" 518 "Transas USA" 529 "National Instruments Korea" 530 "National Marine Electronics Association" 532 "Onwa Marine" 540 "Webasto" 571 "Marinecraft (South Korea)" 573 "McMurdo Group aka Orolia" 578 "Advansea" 579 "KVH" 580 "San Jose Technology" 583 "Yacht Control" 586 "Suzuki Motor" 591 "US Coast Guard" 595 "Ship Module aka Customware" 600 "Aquatic AV" 605 "Aventics" 606 "Intellian" 612 "SamwonIT" 614 "Arlt Tecnologies" 637 "Bavaria Yachts" 641 "Diverse Yacht Services" 644 "Wema U.S.A dba KUS" 658 "Shenzhen Jiuzhou Himunication" 688 "Rockford" 699 "Harman International" 704 "JL Audio" 708 "Lars Thrane" 715 "Autonnic" 717 "Yacht Devices" 734 "REAP Systems" 735 "AEM Performance Electronics" 739 "LxNav" 741 "Littelfuse, Inc (formerly Carling Technologies)" 743 "DaeMyung" 744 "Woosung" 748 "ISOTTA IFRA srl" 773 "Clarion US" 776 "HMI Systems" 777 "Ocean Signal" 778 "Seakeeper" 781 "Poly Planar" 785 "Fischer Panda DE" 795 "Broyda Industries" 796 "Canadian Automotive" 797 "Tides Marine" 798 "Lumishore" 799 "Still Water Designs and Audio" 802 "BJ Technologies (Beneteau)" 803 "Gill Sensors" 811 "Blue Water Desalination" 815 "FLIR" 824 "Undheim Systems" 826 "Lewmar" 838 "TeamSurv" 844 "Fell Marine" 847 "Oceanvolt" 862 "Prospec" 868 "Data Panel" 890 "L3 Technologies" 894 "Rhodan Marine Systems" 896 "Nexfour Solutions" 905 "ASA Electronics" 909 "Marines Co (South Korea)" 911 "Nautic-on" 917 "Sentinel" 929 "JL Marine Systems" 930 "Ecotronix" 944 "Zontisa Marine" 951 "EXOR International" 962 "Timbolier Industries" 963 "TJC Micro" 968 "Cox Powertrain" 969 "Blue Seas" 981 "Kobelt Manufacturing" 992 "Blue Ocean IOT" 997 "Xenta Systems" 999 "Signal K" 1004 "Ultraflex" 1008 "Lintest SmartBoat" 1011 "Soundmax" 1020 "Team Italia Marine (Onyx Marine Automation s.r.l)" 1021 "Entratech" 1022 "ITC" 1029 "The Marine Guardian" 1047 "Sonic" 1051 "ProNav" 1053 "Vetus Maxwell INC." 1056 "Lithium Pros" 1059 "Boatrax" 1062 "Marol Co ltd" 1065 "CALYPSO Instruments" 1066 "Spot Zero Water" 1069 "Lithionics Battery" 1070 "Quick-teck Electronics" 1075 "Uniden America" 1083 "Nauticoncept" 1084 "Shadow-Caster LED lighting" 1085 "Wet Sounds" 1088 "E-T-A Circuit Breakers" 1092 "Scheiber" 1100 "Smart Yachts International Limited" 1109 "Dockmate" 1114 "Bobs Machine" 1118 "L3Harris ASV" 1119 "Balmar" 1120 "Elettromedia" 1127 "Electromaax" 1140 "Across Oceans Systems" 1145 "Kiwi Yachting" 1150 "BSB Artificial Intelligence" 1151 "Orca Technologies" 1154 "TBS Electronics" 1158 "Technoton Electroics" 1160 "MG Energy Systems" 1169 "Sea Machine Robotics" 1171 "Vista Manufacturing" 1183 "Zipwake" 1186 "Sailmon" 1192 "Airmoniq Pro Kft" 1194 "Sierra Marine" 1200 "Xinuo Information Technology (Xiamen)" 1218 "Septentrio" 1233 "NKE Marine Electronics" 1238 "SuperTrack Aps" 1239 "Honda Electronics" 1245 "Raritan Engineering" 1249 "Integrated Power Solutions AG" 1260 "Interactive Technologies" 1283 "LTG-Tech" 1299 "Energy Solutions (UK)" 1300 "WATT Fuel Cell" 1302 "Pro Mainer" 1305 "Dragonfly Energy" 1306 "Koden Electronics" 1311 "Humphree" 1316 "Hinkley Yachts" 1317 "Global Marine Management GmbH (GMM)" 1320 "Triskel Marine" 1330 "Warwick Control Technologies" 1331 "Dolphin Charger" 1337 "Barnacle Systems" 1348 "Radian IoT" 1353 "Ocean LED Marine" 1359 "BluNav" 1361 "OVA (Nantong Saiyang Electronics Co., Ltd)" 1368 "RAD Propulsion" 1369 "Electric Yacht" 1372 "Elco Motor Yachts" 1384 "Tecnoseal Foundry S.r.l" 1385 "Pro Charging Systems" 1389 "EVEX" 1398 "Gobius Sensor Technology" 1403 "Arco Marine" 1408 "Lenco Marine" 1413 "Naocontrol" 1417 "Revatek" 1438 "Aeolionics" 1439 "PredictWind" 1440 "Egis Mobile Electric" 1445 "Starboard Yacht Group" 1446 "Roswell Marine" 1451 "ePropulsion (Guangdong ePropulsion Technology Ltd.)" 1452 "Micro-Air" 1453 "Vital Battery" 1458 "Ride Controller" 1460 "Tocaro Blue" 1461 "Vanquish Yachts" 1471 "FT Technologies" 1478 "Alps Alpine" 1481 "E-Force Marine" 1482 "CMC Marine" 1483 "Nanjing Sandemarine Information Technology" 1850 "Teleflex Marine (SeaStar Solutions)" 1851 "Raymarine" 1852 "Navionics" 1853 "Japan Radio" 1854 "Northstar Technologies" 1855 "Furuno" 1856 "Trimble" 1857 "Simrad" 1858 "Litton" 1859 "Kvasar" 1860 "MMP" 1861 "Vector Cantech" 1862 "Yamaha Marine" 1863 "Faria Instruments" ;
VAL_ 2516520448 Industry_Code 0 "Global" 1 "Highway" 2 "Agriculture" 3 "Construction" 4 "Marine Industry" 5 "Industrial" ;
VAL_ 2583629312 Manufacturer_Code 69 "ARKS Enterprises" 78 "FW Murphy/Enovation Controls" 80 "Twin Disc" 85 "Kohler Power Systems" 88 "Hemisphere GPS" 135 "Airmar" 137 "Maretron" 140 "Lowrance" 144 "Mercury Marine" 147 "Nautibus Electronic" 148 "Blue Water Data" 154 "Westerbeke" 157 "ISSPRO" 161 "Offshore Systems (UK)" 163 "Evinrude/BRP" 165 "CPAC Systems" 168 "Xantrex Technology" 169 "Marlin Technologies" 172 "Yanmar Marine" 174 "Volvo Penta" 176 "Carling Technologies Inc. (Moritz Aerospace)" 185 "Beede Instruments" 192 "Floscan Instrument" 193 "Nobeltec" 198 "Mystic Valley Communications" 199 "Actia" 201 "Disenos Y Technologia" 211 "Digital Switching Systems" 215 "Xintex/Atena" 224 "EMMI NETWORK" 228 "ZF" 229 "Garmin" 233 "Yacht Monitoring Solutions" 235 "Sailormade Marine Telemetry/Tetra Technology" 243 "Eride" 257 "Honda Motor" 272 "Groco" 273 "Actisense" 274 "Amphenol LTW Technology" 275 "Navico" 283 "Hamilton Jet" 285 "Sea Recovery" 286 "Coelmo SRL Italy" 295 "BEP Marine" 304 "Empir Bus" 305 "NovAtel" 306 "Sleipner Motor" 307 "MBW Technologies" 315 "ICOM" 328 "Qwerty" 329 "Dief" 341 "Boening Automationstechnologie" 345 "Korean Maritime University" 351 "Thrane and Thrane" 355 "Mastervolt" 356 "Fischer Panda Generators" 358 "Victron Energy" 370 "Rolls Royce Marine" 373 "Electronic Design" 374 "Northern Lights" 378 "Glendinning" 381 "B & G" 384 "Rose Point Navigation Systems" 385 "Johnson Outdoors Marine Electronics Inc Geonav" 394 "Capi 2" 396 "Beyond Measure" 400 "Livorsi Marine" 404 "ComNav" 409 "Chetco" 419 "Fusion Electronics" 421 "Standard Horizon" 422 "True Heading" 426 "Egersund Marine Electronics" 427 "em-trak Marine Electronics" 431 "Tohatsu Co, JP" 437 "Digital Yacht" 438 "Comar Systems Limited" 440 "Cummins" 443 "VDO (aka Continental-Corporation)" 451 "Parker Hannifin aka Village Marine Tech" 459 "Alltek Marine Electronics" 460 "SAN GIORGIO S.E.I.N" 466 "Veethree Electronics & Marine" 470 "SI-TEX Marine Electronics" 471 "Sea Cross Marine" 475 "GME aka Standard Communications" 476 "Humminbird Marine Electronics" 478 "Ocean Sat" 481 "Chetco Digital Instruments" 493 "Watcheye" 499 "Lcj Capteurs" 502 "Attwood Marine" 503 "Naviop S.R.L." 504 "Vesper Marine" 510 "Marinesoft" 513 "Simarine" 517 "NoLand Engineering" 518 "Transas USA" 529 "National Instruments Korea" 530 "National Marine Electronics Association" 532 "Onwa Marine" 540 "Webasto" 571 "Marinecraft (South Korea)" 573 "McMurdo Group aka Orolia" 578 "Advansea" 579 "KVH" 580 "San Jose Technology" 583 "Yacht Control" 586 "Suzuki Motor" 591 "US Coast Guard" 595 "Ship Module aka Customware" 600 "Aquatic AV" 605 "Aventics" 606 "Intellian" 612 "SamwonIT" 614 "Arlt Tecnologies" 637 "Bavaria Yachts" 641 "Diverse Yacht Services" 644 "Wema U.S.A dba KUS" 658 "Shenzhen Jiuzhou Himunication" 688 "Rockford" 699 "Harman International" 704 "JL Audio" 708 "Lars Thrane" 715 "Autonnic" 717 "Yacht Devices" 734 "REAP Systems" 735 "AEM Performance Electronics" 739 "LxNav" 741 "Littelfuse, Inc (formerly Carling Technologies)" 743 "DaeMyung" 744 "Woosung" 748 "ISOTTA IFRA srl" 773 "Clarion US" 776 "HMI Systems" 777 "Ocean Signal" 778 "Seakeeper" 781 "Poly Planar" 785 "Fischer Panda DE" 795 "Broyda Industries" 796 "Canadian Automotive" 797 "Tides Marine" 798 "Lumishore" 799 "Still Water Designs and Audio" 802 "BJ Technologies (Beneteau)" 803 "Gill Sensors" 811 "Blue Water Desalination" 815 "FLIR" 824 "Undheim Systems" 826 "Lewmar" 838 "TeamSurv" 844 "Fell Marine" 847 "Oceanvolt" 862 "Prospec" 868 "Data Panel" 890 "L3 Technologies" 894 "Rhodan Marine Systems" 896 "Nexfour Solutions" 905 "ASA Electronics" 909 "Marines Co (South Korea)" 911 "Nautic-on" 917 "Sentinel" 929 "JL Marine Systems" 930 "Ecotronix" 944 "Zontisa Marine" 951 "EXOR International" 962 "Timbolier Industries" 963 "TJC Micro" 968 "Cox Powertrain" 969 "Blue Seas" 981 "Kobelt Manufacturing" 992 "Blue Ocean IOT" 997 "Xenta Systems" 999 "Signal K" 1004 "Ultraflex" 1008 "Lintest SmartBoat" 1011 "Soundmax" 1020 "Team Italia Marine (Onyx Marine Automation s.r.l)" 1021 "Entratech" 1022 "ITC" 1029 "The Marine Guardian" 1047 "Sonic" 1051 "ProNav" 1053 "Vetus Maxwell INC." 1056 "Lithium Pros" 1059 "Boatrax" 1062 "Marol Co ltd" 1065 "CALYPSO Instruments" 1066 "Spot Zero Water" 1069 "Lithionics Battery" 1070 "Quick-teck Electronics" 1075 "Uniden America" 1083 "Nauticoncept" 1084 "Shadow-Caster LED lighting" 1085 "Wet Sounds" 1088 "E-T-A Circuit Breakers" 1092 "Scheiber" 1100 "Smart Yachts International Limited" 1109 "Dockmate" 1114 "Bobs Machine" 1118 "L3Harris ASV" 1119 "Balmar" 1120 "Elettromedia" 1127 "Electromaax" 1140 "Across Oceans Systems" 1145 "Kiwi Yachting" 1150 "BSB Artificial Intelligence" 1151 "Orca Technologies" 1154 "TBS Electronics" 1158 "Technoton Electroics" 1160 "MG Energy Systems" 1169 "Sea Machine Robotics" 1171 "Vista Manufacturing" 1183 "Zipwake" 1186 "Sailmon" 1192 "Airmoniq Pro Kft" 1194 "Sierra Marine" 1200 "Xinuo Information Technology (Xiamen)" 1218 "Septentrio" 1233 "NKE Marine Electronics" 1238 "SuperTrack Aps" 1239 "Honda Electronics" 1245 "Raritan Engineering" 1249 "Integrated Power Solutions AG" 1260 "Interactive Technologies" 1283 "LTG-Tech" 1299 "Energy Solutions (UK)" 1300 "WATT Fuel Cell" 1302 "Pro Mainer" 1305 "Dragonfly Energy" 1306 "Koden Electronics" 1311 "Humphree" 1316 "Hinkley Yachts" 1317 "Global Marine Management GmbH (GMM)" 1320 "Triskel Marine" 1330 "Warwick Control Technologies" 1331 "Dolphin Charger" 1337 "Barnacle Systems" 1348 "Radian IoT" 1353 "Ocean LED Marine" 1359 "BluNav" 1361 "OVA (Nantong Saiyang Electronics Co., Ltd)" 1368 "RAD Propulsion" 1369 "Electric Yacht" 1372 "Elco Motor Yachts" 1384 "Tecnoseal Foundry S.r.l" 1385 "Pro Charging Systems" 1389 "EVEX" 1398 "Gobius Sensor Technology" 1403 "Arco Marine" 1408 "Lenco Marine" 1413 "Naocontrol" 1417 "Revatek" 1438 "Aeolionics" 1439 "PredictWind" 1440 "Egis Mobile Electric" 1445 "Starboard Yacht Group" 1446 "Roswell Marine" 1451 "ePropulsion (Guangdong ePropulsion Technology Ltd.)" 1452 "Micro-Air" 1453 "Vital Battery" 1458 "Ride Controller" 1460 "Tocaro Blue" 1461 "Vanquish Yachts" 1471 "FT Technologies" 1478 "Alps Alpine" 1481 "E-Force Marine" 1482 "CMC Marine" 1483 "Nanjing Sandemarine Information Technology" 1850 "Teleflex Marine (SeaStar Solutions)" 1851 "Raymarine" 1852 "Navionics" 1853 "Japan Radio" 1854 "Northstar Technologies" 1855 "Furuno" 1856 "Trimble" 1857 "Simrad" 1858 "Litton" 1859 "Kvasar" 1860 "MMP" 1861 "Vector Cantech" 1862 "Yamaha Marine" 1863 "Faria Instruments" ;
VAL_ 2583629312 Industry_Code 0 "Global" 1 "Highway" 2 "Agriculture" 3 "Construction" 4 "Marine Industry" 5 "Industrial" ;
VAL_ 2583629568 Manufacturer_Code 69 "ARKS Enterprises" 78 "FW Murphy/Enovation Controls" 80 "Twin Disc" 85 "Kohler Power Systems" 88 "Hemisphere GPS" 135 "Airmar" 137 "Maretron" 140 "Lowrance" 144 "Mercury Marine" 147 "Nautibus Electronic" 148 "Blue Water Data" 154 "Westerbeke" 157 "ISSPRO" 161 "Offshore Systems (UK)" 163 "Evinrude/BRP" 165 "CPAC Systems" 168 "Xantrex Technology" 169 "Marlin Technologies" 172 "Yanmar Marine" 174 "Volvo Penta" 176 "Carling Technologies Inc. (Moritz Aerospace)" 185 "Beede Instruments" 192 "Floscan Instrument" 193 "Nobeltec" 198 "Mystic Valley Communications" 199 "Actia" 201 "Disenos Y Technologia" 211 "Digital Switching Systems" 215 "Xintex/Atena" 224 "EMMI NETWORK" 228 "ZF" 229 "Garmin" 233 "Yacht Monitoring Solutions" 235 "Sailormade Marine Telemetry/Tetra Technology" 243 "Eride" 257 "Honda Motor" 272 "Groco" 273 "Actisense" 274 "Amphenol LTW Technology" 275 "Navico" 283 "Hamilton Jet" 285 "Sea Recovery" 286 "Coelmo SRL Italy" 295 "BEP Marine" 304 "Empir Bus" 305 "NovAtel" 306 "Sleipner Motor" 307 "MBW Technologies" 315 "ICOM" 328 "Qwerty" 329 "Dief" 341 "Boening Automationstechnologie" 345 "Korean Maritime University" 351 "Thrane and Thrane" 355 "Mastervolt" 356 "Fischer Panda Generators" 358 "Victron Energy" 370 "Rolls Royce Marine" 373 "Electronic Design" 374 "Northern Lights" 378 "Glendinning" 381 "B & G" 384 "Rose Point Navigation Systems" 385 "Johnson Outdoors Marine Electronics Inc Geonav" 394 "Capi 2" 396 "Beyond Measure" 400 "Livorsi Marine" 404 "ComNav" 409 "Chetco" 419 "Fusion Electronics" 421 "Standard Horizon" 422 "True Heading" 426 "Egersund Marine Electronics" 427 "em-trak Marine Electronics" 431 "Tohatsu Co, JP" 437 "Digital Yacht" 438 "Comar Systems Limited" 440 "Cummins" 443 "VDO (aka Continental-Corporation)" 451 "Parker Hannifin aka Village Marine Tech" 459 "Alltek Marine Electronics" 460 "SAN GIORGIO S.E.I.N" 466 "Veethree Electronics & Marine" 470 "SI-TEX Marine Electronics" 471 "Sea Cross Marine" 475 "GME aka Standard Communications" 476 "Humminbird Marine Electronics" 478 "Ocean Sat" 481 "Chetco Digital Instruments" 493 "Watcheye" 499 "Lcj Capteurs" 502 "Attwood Marine" 503 "Naviop S.R.L." 504 "Vesper Marine" 510 "Marinesoft" 513 "Simarine" 517 "NoLand Engineering" 518 "Transas USA" 529 "National Instruments Korea" 530 "National Marine Electronics Association" 532 "Onwa Marine" 540 "Webasto" 571 "Marinecraft (South Korea)" 573 "McMurdo Group aka Orolia" 578 "Advansea" 579 "KVH" 580 "San Jose Technology" 583 "Yacht Control" 586 "Suzuki Motor" 591 "US Coast Guard" 595 "Ship Module aka Customware" 600 "Aquatic AV" 605 "Aventics" 606 "Intellian" 612 "SamwonIT" 614 "Arlt Tecnologies" 637 "Bavaria Yachts" 641 "Diverse Yacht Services" 644 "Wema U.S.A dba KUS" 658 "Shenzhen Jiuzhou Himunication" 688 "Rockford" 699 "Harman International" 704 "JL Audio" 708 "Lars Thrane" 715 "Autonnic" 717 "Yacht Devices" 734 "REAP Systems" 735 "AEM Performance Electronics" 739 "LxNav" 741 "Littelfuse, Inc (formerly Carling Technologies)" 743 "DaeMyung" 744 "Woosung" 748 "ISOTTA IFRA srl" 773 "Clarion US" 776 "HMI Systems" 777 "Ocean Signal" 778 "Seakeeper" 781 "Poly Planar" 785 "Fischer Panda DE" 795 "Broyda Industries" 796 "Canadian Automotive" 797 "Tides Marine" 798 "Lumishore" 799 "Still Water Designs and Audio" 802 "BJ Technologies (Beneteau)" 803 "Gill Sensors" 811 "Blue Water Desalination" 815 "FLIR" 824 "Undheim Systems" 826 "Lewmar" 838 "TeamSurv" 844 "Fell Marine" 847 "Oceanvolt" 862 "Prospec" 868 "Data Panel" 890 "L3 Technologies" 894 "Rhodan Marine Systems" 896 "Nexfour Solutions" 905 "ASA Electronics" 909 "Marines Co (South Korea)" 911 "Nautic-on" 917 "Sentinel" 929 "JL Marine Systems" 930 "Ecotronix" 944 "Zontisa Marine" 951 "EXOR International" 962 "Timbolier Industries" 963 "TJC Micro" 968 "Cox Powertrain" 969 "Blue Seas" 981 "Kobelt Manufacturing" 992 "Blue Ocean IOT" 997 "Xenta Systems" 999 "Signal K" 1004 "Ultraflex" 1008 "Lintest SmartBoat" 1011 "Soundmax" 1020 "Team Italia Marine (Onyx Marine Automation s.r.l)" 1021 "Entratech" 1022 "ITC" 1029 "The Marine Guardian" 1047 "Sonic" 1051 "ProNav" 1053 "Vetus Maxwell INC." 1056 "Lithium Pros" 1059 "Boatrax" 1062 "Marol Co ltd" 1065 "CALYPSO Instruments" 1066 "Spot Zero Water" 1069 "Lithionics Battery" 1070 "Quick-teck Electronics" 1075 "Uniden America" 1083 "Nauticoncept" 1084 "Shadow-Caster LED lighting" 1085 "Wet Sounds" 1088 "E-T-A Circuit Breakers" 1092 "Scheiber" 1100 "Smart Yachts International Limited" 1109 "Dockmate" 1114 "Bobs Machine" 1118 "L3Harris ASV" 1119 "Balmar" 1120 "Elettromedia" 1127 "Electromaax" 1140 "Across Oceans Systems" 1145 "Kiwi Yachting" 1150 "BSB Artificial Intelligence" 1151 "Orca Technologies" 1154 "TBS Electronics" 1158 "Technoton Electroics" 1160 "MG Energy Systems" 1169 "Sea Machine Robotics" 1171 "Vista Manufacturing" 1183 "Zipwake" 1186 "Sailmon" 1192 "Airmoniq Pro Kft" 1194 "Sierra Marine" 1200 "Xinuo Information Technology (Xiamen)" 1218 "Septentrio" 1233 "NKE Marine Electronics" 1238 "SuperTrack Aps" 1239 "Honda Electronics" 1245 "Raritan Engineering" 1249 "Integrated Power Solutions AG" 1260 "Interactive Technologies" 1283 "LTG-Tech" 1299 "Energy Solutions (UK)" 1300 "WATT Fuel Cell" 1302 "Pro Mainer" 1305 "Dragonfly Energy" 1306 "Koden Electronics" 1311 "Humphree" 1316 "Hinkley Yachts" 1317 "Global Marine Management GmbH (GMM)" 1320 "Triskel Marine" 1330 "Warwick Control Technologies" 1331 "Dolphin Charger" 1337 "Barnacle Systems" 1348 "Radian IoT" 1353 "Ocean LED Marine" 1359 "BluNav" 1361 "OVA (Nantong Saiyang Electronics Co., Ltd)" 1368 "RAD Propulsion" 1369 "Electric Yacht" 1372 "Elco Motor Yachts" 1384 "Tecnoseal Foundry S.r.l" 1385 "Pro Charging Systems" 1389 "EVEX" 1398 "Gobius Sensor Technology" 1403 "Arco Marine" 1408 "Lenco Marine" 1413 "Naocontrol" 1417 "Revatek" 1438 "Aeolionics" 1439 "PredictWind" 1440 "Egis Mobile Electric" 1445 "Starboard Yacht Group" 1446 "Roswell Marine" 1451 "ePropulsion (Guangdong ePropulsion Technology Ltd.)" 1452 "Micro-Air" 1453 "Vital Battery" 1458 "Ride Controller" 1460 "Tocaro Blue" 1461 "Vanquish Yachts" 1471 "FT Technologies" 1478 "Alps Alpine" 1481 "E-Force Marine" 1482 "CMC Marine" 1483 "Nanjing Sandemarine Information Technology" 1850 "Teleflex Marine (SeaStar Solutions)" 1851 "Raymarine" 1852 "Navionics" 1853 "Japan Radio" 1854 "Northstar Technologies" 1855 "Furuno" 1856 "Trimble" 1857 "Simrad" 1858 "Litton" 1859 "Kvasar" 1860 "MMP" 1861 "Vector Cantech" 1862 "Yamaha Marine" 1863 "Faria Instruments" ;
VAL_ 2583629568 Industry_Code 0 "Global" 1 "Highway" 2 "Agriculture" 3 "Construction" 4 "Marine Industry" 5 "Industrial" ;
VAL_ 2583629568 Manufacturer_Code 69 "ARKS Enterprises" 78 "FW Murphy/Enovation Controls" 80 "Twin Disc" 85 "Kohler Power Systems" 88 "Hemisphere GPS" 135 "Airmar" 137 "Maretron" 140 "Lowrance" 144 "Mercury Marine" 147 "Nautibus Electronic" 148 "Blue Water Data" 154 "Westerbeke" 157 "ISSPRO" 161 "Offshore Systems (UK)" 163 "Evinrude/BRP" 165 "CPAC Systems" 168 "Xantrex Technology" 169 "Marlin Technologies" 172 "Yanmar Marine" 174 "Volvo Penta" 176 "Carling Technologies Inc. (Moritz Aerospace)" 185 "Beede Instruments" 192 "Floscan Instrument" 193 "Nobeltec" 198 "Mystic Valley Communications" 199 "Actia" 201 "Disenos Y Technologia" 211 "Digital Switching Systems" 215 "Xintex/Atena" 224 "EMMI NETWORK" 228 "ZF" 229 "Garmin" 233 "Yacht Monitoring Solutions" 235 "Sailormade Marine Telemetry/Tetra Technology" 243 "Eride" 257 "Honda Motor" 272 "Groco" 273 "Actisense" 274 "Amphenol LTW Technology" 275 "Navico" 283 "Hamilton Jet" 285 "Sea Recovery" 286 "Coelmo SRL Italy" 295 "BEP Marine" 304 "Empir Bus" 305 "NovAtel" 306 "Sleipner Motor" 307 "MBW Technologies" 315 "ICOM" 328 "Qwerty" 329 "Dief" 341 "Boening Automationstechnologie" 345 "Korean Maritime University" 351 "Thrane and Thrane" 355 "Mastervolt" 356 "Fischer Panda Generators" 358 "Victron Energy" 370 "Rolls Royce Marine" 373 "Electronic Design" 374 "Northern Lights" 378 "Glendinning" 381 "B & G" 384 "Rose Point Navigation Systems" 385 "Johnson Outdoors Marine Electronics Inc Geonav" 394 "Capi 2" 396 "Beyond Measure" 400 "Livorsi Marine" 404 "ComNav" 409 "Chetco" 419 "Fusion Electronics" 421 "Standard Horizon" 422 "True Heading" 426 "Egersund Marine Electronics" 427 "em-trak Marine Electronics" 431 "Tohatsu Co, JP" 437 "Digital Yacht" 438 "Comar Systems Limited" 440 "Cummins" 443 "VDO (aka Continental-Corporation)" 451 "Parker Hannifin aka Village Marine Tech" 459 "Alltek Marine Electronics" 460 "SAN GIORGIO S.E.I.N" 466 "Veethree Electronics & Marine" 470 "SI-TEX Marine Electronics" 471 "Sea Cross Marine" 475 "GME aka Standard Communications" 476 "Humminbird Marine Electronics" 478 "Ocean Sat" 481 "Chetco Digital Instruments" 493 "Watcheye" 499 "Lcj Capteurs" 502 "Attwood Marine" 503 "Naviop S.R.L." 504 "Vesper Marine" 510 "Marinesoft" 513 "Simarine" 517 "NoLand Engineering" 518 "Transas USA" 529 "National Instruments Korea" 530 "National Marine Electronics Association" 532 "Onwa Marine" 540 "Webasto" 571 "Marinecraft (South Korea)" 573 "McMurdo Group aka Orolia" 578 "Advansea" 579 "KVH" 580 "San Jose Technology" 583 "Yacht Control" 586 "Suzuki Motor" 591 "US Coast Guard" 595 "Ship Module aka Customware" 600 "Aquatic AV" 605 "Aventics" 606 "Intellian" 612 "SamwonIT" 614 "Arlt Tecnologies" 637 "Bavaria Yachts" 641 "Diverse Yacht Services" 644 "Wema U.S.A dba KUS" 658 "Shenzhen Jiuzhou Himunication" 688 "Rockford" 699 "Harman International" 704 "JL Audio" 708 "Lars Thrane" 715 "Autonnic" 717 "Yacht Devices" 734 "REAP Systems" 735 "AEM Performance Electronics" 739 "LxNav" 741 "Littelfuse, Inc (formerly Carling Technologies)" 743 "DaeMyung" 744 "Woosung" 748 "ISOTTA IFRA srl" 773 "Clarion US" 776 "HMI Systems" 777 "Ocean Signal" 778 "Seakeeper" 781 "Poly Planar" 785 "Fischer Panda DE" 795 "Broyda Industries" 796 "Canadian Automotive" 797 "Tides Marine" 798 "Lumishore" 799 "Still Water Designs and Audio" 802 "BJ Technologies (Beneteau)" 803 "Gill Sensors" 811 "Blue Water Desalination" 815 "FLIR" 824 "Undheim Systems" 826 "Lewmar" 838 "TeamSurv" 844 "Fell Marine" 847 "Oceanvolt" 862 "Prospec" 868 "Data Panel" 890 "L3 Technologies" 894 "Rhodan Marine Systems" 896 "Nexfour Solutions" 905 "ASA Electronics" 909 "Marines Co (South Korea)" 911 "Nautic-on" 917 "Sentinel" 929 "JL Marine Systems" 930 "Ecotronix" 944 "Zontisa Marine" 951 "EXOR International" 962 "Timbolier Industries" 963 "TJC Micro" 968 "Cox Powertrain" 969 "Blue Seas" 981 "Kobelt Manufacturing" 992 "Blue Ocean IOT" 997 "Xenta Systems" 999 "Signal K" 1004 "Ultraflex" 1008 "Lintest SmartBoat" 1011 "Soundmax" 1020 "Team Italia Marine (Onyx Marine Automation s.r.l)" 1021 "Entratech" 1022 "ITC" 1029 "The Marine Guardian" 1047 "Sonic" 1051 "ProNav" 1053 "Vetus Maxwell INC." 1056 "Lithium Pros" 1059 "Boatrax" 1062 "Marol Co ltd" 1065 "CALYPSO Instruments" 1066 "Spot Zero Water" 1069 "Lithionics Battery" 1070 "Quick-teck Electronics" 1075 "Uniden America" 1083 "Nauticoncept" 1084 "Shadow-Caster LED lighting" 1085 "Wet Sounds" 1088 "E-T-A Circuit Breakers" 1092 "Scheiber" 1100 "Smart Yachts International Limited" 1109 "Dockmate" 1114 "Bobs Machine" 1118 "L3Harris ASV" 1119 "Balmar" 1120 "Elettromedia" 1127 "Electromaax" 1140 "Across Oceans Systems" 1145 "Kiwi Yachting" 1150 "BSB Artificial Intelligence" 1151 "Orca Technologies" 1154 "TBS Electronics" 1158 "Technoton Electroics" 1160 "MG Energy Systems" 1169 "Sea Machine Robotics" 1171 "Vista Manufacturing" 1183 "Zipwake" 1186 "Sailmon" 1192 "Airmoniq Pro Kft" 1194 "Sierra Marine" 1200 "Xinuo Information Technology (Xiamen)" 1218 "Septentrio" 1233 "NKE Marine Electronics" 1238 "SuperTrack Aps" 1239 "Honda Electronics" 1245 "Raritan Engineering" 1249 "Integrated Power Solutions AG" 1260 "Interactive Technologies" 1283 "LTG-Tech" 1299 "Energy Solutions (UK)" 1300 "WATT Fuel Cell" 1302 "Pro Mainer" 1305 "Dragonfly Energy" 1306 "Koden Electronics" 1311 "Humphree" 1316 "Hinkley Yachts" 1317 "Global Marine Management GmbH (GMM)" 1320 "Triskel Marine" 1330 "Warwick Control Technologies" 1331 "Dolphin Charger" 1337 "Barnacle Systems" 1348 "Radian IoT" 1353 "Ocean LED Marine" 1359 "BluNav" 1361 "OVA (Nantong Saiyang Electronics Co., Ltd)" 1368 "RAD Propulsion" 1369 "Electric Yacht" 1372 "Elco Motor Yachts" 1384 "Tecnoseal Foundry S.r.l" 1385 "Pro Charging Systems" 1389 "EVEX" 1398 "Gobius Sensor Technology" 1403 "Arco Marine" 1408 "Lenco Marine" 1413 "Naocontrol" 1417 "Revatek" 1438 "Aeolionics" 1439 "PredictWind" 1440 "Egis Mobile Electric" 1445 "Starboard Yacht Group" 1446 "Roswell Marine" 1451 "ePropulsion (Guangdong ePropulsion Technology Ltd.)" 1452 "Micro-Air" 1453 "Vital Battery" 1458 "Ride Controller" 1460 "Tocaro Blue" 1461 "Vanquish Yachts" 1471 "FT Technologies" 1478 "Alps Alpine" 1481 "E-Force Marine" 1482 "CMC Marine" 1483 "Nanjing Sandemarine Information Technology" 1850 "Teleflex Marine (SeaStar Solutions)" 1851 "Raymarine" 1852 "Navionics" 1853 "Japan Radio" 1854 "Northstar Technologies" 1855 "Furuno" 1856 "Trimble" 1857 "Simrad" 1858 "Litton" 1859 "Kvasar" 1860 "MMP" 1861 "Vector Cantech" 1862 "Yamaha Marine" 1863 "Faria Instruments" ;
VAL_ 2583629568 Industry_Code 0 "Global" 1 "Highway" 2 "Agriculture" 3 "Construction" 4 "Marine Industry" 5 "Industrial" ;
VAL_ 2650738688 Manufacturer_Code 69 "ARKS Enterprises" 78 "FW Murphy/Enovation Controls" 80 "Twin Disc" 85 "Kohler Power Systems" 88 "Hemisphere GPS" 135 "Airmar" 137 "Maretron" 140 "Lowrance" 144 "Mercury Marine" 147 "Nautibus Electronic" 148 "Blue Water Data" 154 "Westerbeke" 157 "ISSPRO" 161 "Offshore Systems (UK)" 163 "Evinrude/BRP" 165 "CPAC Systems" 168 "Xantrex Technology" 169 "Marlin Technologies" 172 "Yanmar Marine" 174 "Volvo Penta" 176 "Carling Technologies Inc. (Moritz Aerospace)" 185 "Beede Instruments" 192 "Floscan Instrument" 193 "Nobeltec" 198 "Mystic Valley Communications" 199 "Actia" 201 "Disenos Y Technologia" 211 "Digital Switching Systems" 215 "Xintex/Atena" 224 "EMMI NETWORK" 228 "ZF" 229 "Garmin" 233 "Yacht Monitoring Solutions" 235 "Sailormade Marine Telemetry/Tetra Technology" 243 "Eride" 257 "Honda Motor" 272 "Groco" 273 "Actisense" 274 "Amphenol LTW Technology" 275 "Navico" 283 "Hamilton Jet" 285 "Sea Recovery" 286 "Coelmo SRL Italy" 295 "BEP Marine" 304 "Empir Bus" 305 "NovAtel" 306 "Sleipner Motor" 307 "MBW Technologies" 315 "ICOM" 328 "Qwerty" 329 "Dief" 341 "Boening Automationstechnologie" 345 "Korean Maritime University" 351 "Thrane and Thrane" 355 "Mastervolt" 356 "Fischer Panda Generators" 358 "Victron Energy" 370 "Rolls Royce Marine" 373 "Electronic Design" 374 "Northern Lights" 378 "Glendinning" 381 "B & G" 384 "Rose Point Navigation Systems" 385 "Johnson Outdoors Marine Electronics Inc Geonav" 394 "Capi 2" 396 "Beyond Measure" 400 "Livorsi Marine" 404 "ComNav" 409 "Chetco" 419 "Fusion Electronics" 421 "Standard Horizon" 422 "True Heading" 426 "Egersund Marine Electronics" 427 "em-trak Marine Electronics" 431 "Tohatsu Co, JP" 437 "Digital Yacht" 438 "Comar Systems Limited" 440 "Cummins" 443 "VDO (aka Continental-Corporation)" 451 "Parker Hannifin aka Village Marine Tech" 459 "Alltek Marine Electronics" 460 "SAN GIORGIO S.E.I.N" 466 "Veethree Electronics & Marine" 470 "SI-TEX Marine Electronics" 471 "Sea Cross Marine" 475 "GME aka Standard Communications" 476 "Humminbird Marine Electronics" 478 "Ocean Sat" 481 "Chetco Digital Instruments" 493 "Watcheye" 499 "Lcj Capteurs" 502 "Attwood Marine" 503 "Naviop S.R.L." 504 "Vesper Marine" 510 "Marinesoft" 513 "Simarine" 517 "NoLand Engineering" 518 "Transas USA" 529 "National Instruments Korea" 530 "National Marine Electronics Association" 532 "Onwa Marine" 540 "Webasto" 571 "Marinecraft (South Korea)" 573 "McMurdo Group aka Orolia" 578 "Advansea" 579 "KVH" 580 "San Jose Technology" 583 "Yacht Control" 586 "Suzuki Motor" 591 "US Coast Guard" 595 "Ship Module aka Customware" 600 "Aquatic AV" 605 "Aventics" 606 "Intellian" 612 "SamwonIT" 614 "Arlt Tecnologies" 637 "Bavaria Yachts" 641 "Diverse Yacht Services" 644 "Wema U.S.A dba KUS" 658 "Shenzhen Jiuzhou Himunication" 688 "Rockford" 699 "Harman International" 704 "JL Audio" 708 "Lars Thrane" 715 "Autonnic" 717 "Yacht Devices" 734 "REAP Systems" 735 "AEM Performance Electronics" 739 "LxNav" 741 "Littelfuse, Inc (formerly Carling Technologies)" 743 "DaeMyung" 744 "Woosung" 748 "ISOTTA IFRA srl" 773 "Clarion US" 776 "HMI Systems" 777 "Ocean Signal" 778 "Seakeeper" 781 "Poly Planar" 785 "Fischer Panda DE" 795 "Broyda Industries" 796 "Canadian Automotive" 797 "Tides Marine" 798 "Lumishore" 799 "Still Water Designs and Audio" 802 "BJ Technologies (Beneteau)" 803 "Gill Sensors" 811 "Blue Water Desalination" 815 "FLIR" 824 "Undheim Systems" 826 "Lewmar" 838 "TeamSurv" 844 "Fell Marine" 847 "Oceanvolt" 862 "Prospec" 868 "Data Panel" 890 "L3 Technologies" 894 "Rhodan Marine Systems" 896 "Nexfour Solutions" 905 "ASA Electronics" 909 "Marines Co (South Korea)" 911 "Nautic-on" 917 "Sentinel" 929 "JL Marine Systems" 930 "Ecotronix" 944 "Zontisa Marine" 951 "EXOR International" 962 "Timbolier Industries" 963 "TJC Micro" 968 "Cox Powertrain" 969 "Blue Seas" 981 "Kobelt Manufacturing" 992 "Blue Ocean IOT" 997 "Xenta Systems" 999 "Signal K" 1004 "Ultraflex" 1008 "Lintest SmartBoat" 1011 "Soundmax" 1020 "Team Italia Marine (Onyx Marine Automation s.r.l)" 1021 "Entratech" 1022 "ITC" 1029 "The Marine Guardian" 1047 "Sonic" 1051 "ProNav" 1053 "Vetus Maxwell INC." 1056 "Lithium Pros" 1059 "Boatrax" 1062 "Marol Co ltd" 1065 "CALYPSO Instruments" 1066 "Spot Zero Water" 1069 "Lithionics Battery" 1070 "Quick-teck Electronics" 1075 "Uniden America" 1083 "Nauticoncept" 1084 "Shadow-Caster LED lighting" 1085 "Wet Sounds" 1088 "E-T-A Circuit Breakers" 1092 "Scheiber" 1100 "Smart Yachts International Limited" 1109 "Dockmate" 1114 "Bobs Machine" 1118 "L3Harris ASV" 1119 "Balmar" 1120 "Elettromedia" 1127 "Electromaax" 1140 "Across Oceans Systems" 1145 "Kiwi Yachting" 1150 "BSB Artificial Intelligence" 1151 "Orca Technologies" 1154 "TBS Electronics" 1158 "Technoton Electroics" 1160 "MG Energy Systems" 1169 "Sea Machine Robotics" 1171 "Vista Manufacturing" 1183 "Zipwake" 1186 "Sailmon" 1192 "Airmoniq Pro Kft" 1194 "Sierra Marine" 1200 "Xinuo Information Technology (Xiamen)" 1218 "Septentrio" 1233 "NKE Marine Electronics" 1238 "SuperTrack Aps" 1239 "Honda Electronics" 1245 "Raritan Engineering" 1249 "Integrated Power Solutions AG" 1260 "Interactive Technologies" 1283 "LTG-Tech" 1299 "Energy Solutions (UK)" 1300 "WATT Fuel Cell" 1302 "Pro Mainer" 1305 "Dragonfly Energy" 1306 "Koden Electronics" 1311 "Humphree" 1316 "Hinkley Yachts" 1317 "Global Marine Management GmbH (GMM)" 1320 "Triskel Marine" 1330 "Warwick Control Technologies" 1331 "Dolphin Charger" 1337 "Barnacle Systems" 1348 "Radian IoT" 1353 "Ocean LED Marine" 1359 "BluNav" 1361 "OVA (Nantong Saiyang Electronics Co., Ltd)" 1368 "RAD Propulsion" 1369 "Electric Yacht" 1372 "Elco Motor Yachts" 1384 "Tecnoseal Foundry S.r.l" 1385 "Pro Charging Systems" 1389 "EVEX" 1398 "Gobius Sensor Technology" 1403 "Arco Marine" 1408 "Lenco Marine" 1413 "Naocontrol" 1417 "Revatek" 1438 "Aeolionics" 1439 "PredictWind" 1440 "Egis Mobile Electric" 1445 "Starboard Yacht Group" 1446 "Roswell Marine" 1451 "ePropulsion (Guangdong ePropulsion Technology Ltd.)" 1452 "Micro-Air" 1453 "Vital Battery" 1458 "Ride Controller" 1460 "Tocaro Blue" 1461 "Vanquish Yachts" 1471 "FT Technologies" 1478 "Alps Alpine" 1481 "E-Force Marine" 1482 "CMC Marine" 1483 "Nanjing Sandemarine Information Technology" 1850 "Teleflex Marine (SeaStar Solutions)" 1851 "Raymarine" 1852 "Navionics" 1853 "Japan Radio" 1854 "Northstar Technologies" 1855 "Furuno" 1856 "Trimble" 1857 "Simrad" 1858 "Litton" 1859 "Kvasar" 1860 "MMP" 1861 "Vector Cantech" 1862 "Yamaha Marine" 1863 "Faria Instruments" ;
VAL_ 2650738688 Industry_Code 0 "Global" 1 "Highway" 2 "Agriculture" 3 "Construction" 4 "Marine Industry" 5 "Industrial" ;
VAL_ 2583629824 Manufacturer_Code 69 "ARKS Enterprises" 78 "FW Murphy/Enovation Controls" 80 "Twin Disc" 85 "Kohler Power Systems" 88 "Hemisphere GPS" 135 "Airmar" 137 "Maretron" 140 "Lowrance" 144 "Mercury Marine" 147 "Nautibus Electronic" 148 "Blue Water Data" 154 "Westerbeke" 157 "ISSPRO" 161 "Offshore Systems (UK)" 163 "Evinrude/BRP" 165 "CPAC Systems" 168 "Xantrex Technology" 169 "Marlin Technologies" 172 "Yanmar Marine" 174 "Volvo Penta" 176 "Carling Technologies Inc. (Moritz Aerospace)" 185 "Beede Instruments" 192 "Floscan Instrument" 193 "Nobeltec" 198 "Mystic Valley Communications" 199 "Actia" 201 "Disenos Y Technologia" 211 "Digital Switching Systems" 215 "Xintex/Atena" 224 "EMMI NETWORK" 228 "ZF" 229 "Garmin" 233 "Yacht Monitoring Solutions" 235 "Sailormade Marine Telemetry/Tetra Technology" 243 "Eride" 257 "Honda Motor" 272 "Groco" 273 "Actisense" 274 "Amphenol LTW Technology" 275 "Navico" 283 "Hamilton Jet" 285 "Sea Recovery" 286 "Coelmo SRL Italy" 295 "BEP Marine" 304 "Empir Bus" 305 "NovAtel" 306 "Sleipner Motor" 307 "MBW Technologies" 315 "ICOM" 328 "Qwerty" 329 "Dief" 341 "Boening Automationstechnologie" 345 "Korean Maritime University" 351 "Thrane and Thrane" 355 "Mastervolt" 356 "Fischer Panda Generators" 358 "Victron Energy" 370 "Rolls Royce Marine" 373 "Electronic Design" 374 "Northern Lights" 378 "Glendinning" 381 "B & G" 384 "Rose Point Navigation Systems" 385 "Johnson Outdoors Marine Electronics Inc Geonav" 394 "Capi 2" 396 "Beyond Measure" 400 "Livorsi Marine" 404 "ComNav" 409 "Chetco" 419 "Fusion Electronics" 421 "Standard Horizon" 422 "True Heading" 426 "Egersund Marine Electronics" 427 "em-trak Marine Electronics" 431 "Tohatsu Co, JP" 437 "Digital Yacht" 438 "Comar Systems Limited" 440 "Cummins" 443 "VDO (aka Continental-Corporation)" 451 "Parker Hannifin aka Village Marine Tech" 459 "Alltek Marine Electronics" 460 "SAN GIORGIO S.E.I.N" 466 "Veethree Electronics & Marine" 470 "SI-TEX Marine Electronics" 471 "Sea Cross Marine" 475 "GME aka Standard Communications" 476 "Humminbird Marine Electronics" 478 "Ocean Sat" 481 "Chetco Digital Instruments" 493 "Watcheye" 499 "Lcj Capteurs" 502 "Attwood Marine" 503 "Naviop S.R.L." 504 "Vesper Marine" 510 "Marinesoft" 513 "Simarine" 517 "NoLand Engineering" 518 "Transas USA" 529 "National Instruments Korea" 530 "National Marine Electronics Association" 532 "Onwa Marine" 540 "Webasto" 571 "Marinecraft (South Korea)" 573 "McMurdo Group aka Orolia" 578 "Advansea" 579 "KVH" 580 "San Jose Technology" 583 "Yacht Control" 586 "Suzuki Motor" 591 "US Coast Guard" 595 "Ship Module aka Customware" 600 "Aquatic AV" 605 "Aventics" 606 "Intellian" 612 "SamwonIT" 614 "Arlt Tecnologies" 637 "Bavaria Yachts" 641 "Diverse Yacht Services" 644 "Wema U.S.A dba KUS" 658 "Shenzhen Jiuzhou Himunication" 688 "Rockford" 699 "Harman International" 704 "JL Audio" 708 "Lars Thrane" 715 "Autonnic" 717 "Yacht Devices" 734 "REAP Systems" 735 "AEM Performance Electronics" 739 "LxNav" 741 "Littelfuse, Inc (formerly Carling Technologies)" 743 "DaeMyung" 744 "Woosung" 748 "ISOTTA IFRA srl" 773 "Clarion US" 776 "HMI Systems" 777 "Ocean Signal" 778 "Seakeeper" 781 "Poly Planar" 785 "Fischer Panda DE" 795 "Broyda Industries" 796 "Canadian Automotive" 797 "Tides Marine" 798 "Lumishore" 799 "Still Water Designs and Audio" 802 "BJ Technologies (Beneteau)" 803 "Gill Sensors" 811 "Blue Water Desalination" 815 "FLIR" 824 "Undheim Systems" 826 "Lewmar" 838 "TeamSurv" 844 "Fell Marine" 847 "Oceanvolt" 862 "Prospec" 868 "Data Panel" 890 "L3 Technologies" 894 "Rhodan Marine Systems" 896 "Nexfour Solutions" 905 "ASA Electronics" 909 "Marines Co (South Korea)" 911 "Nautic-on" 917 "Sentinel" 929 "JL Marine Systems" 930 "Ecotronix" 944 "Zontisa Marine" 951 "EXOR International" 962 "Timbolier Industries" 963 "TJC Micro" 968 "Cox Powertrain" 969 "Blue Seas" 981 "Kobelt Manufacturing" 992 "Blue Ocean IOT" 997 "Xenta Systems" 999 "Signal K" 1004 "Ultraflex" 1008 "Lintest SmartBoat" 1011 "Soundmax" 1020 "Team Italia Marine (Onyx Marine Automation s.r.l)" 1021 "Entratech" 1022 "ITC" 1029 "The Marine Guardian" 1047 "Sonic" 1051 "ProNav" 1053 "Vetus Maxwell INC." 1056 "Lithium Pros" 1059 "Boatrax" 1062 "Marol Co ltd" 1065 "CALYPSO Instruments" 1066 "Spot Zero Water" 1069 "Lithionics Battery" 1070 "Quick-teck Electronics" 1075 "Uniden America" 1083 "Nauticoncept" 1084 "Shadow-Caster LED lighting" 1085 "Wet Sounds" 1088 "E-T-A Circuit Breakers" 1092 "Scheiber" 1100 "Smart Yachts International Limited" 1109 "Dockmate" 1114 "Bobs Machine" 1118 "L3Harris ASV" 1119 "Balmar" 1120 "Elettromedia" 1127 "Electromaax" 1140 "Across Oceans Systems" 1145 "Kiwi Yachting" 1150 "BSB Artificial Intelligence" 1151 "Orca Technologies" 1154 "TBS Electronics" 1158 "Technoton Electroics" 1160 "MG Energy Systems" 1169 "Sea Machine Robotics" 1171 "Vista Manufacturing" 1183 "Zipwake" 1186 "Sailmon" 1192 "Airmoniq Pro Kft" 1194 "Sierra Marine" 1200 "Xinuo Information Technology (Xiamen)" 1218 "Septentrio" 1233 "NKE Marine Electronics" 1238 "SuperTrack Aps" 1239 "Honda Electronics" 1245 "Raritan Engineering" 1249 "Integrated Power Solutions AG" 1260 "Interactive Technologies" 1283 "LTG-Tech" 1299 "Energy Solutions (UK)" 1300 "WATT Fuel Cell" 1302 "Pro Mainer" 1305 "Dragonfly Energy" 1306 "Koden Electronics" 1311 "Humphree" 1316 "Hinkley Yachts" 1317 "Global Marine Management GmbH (GMM)" 1320 "Triskel Marine" 1330 "Warwick Control Technologies" 1331 "Dolphin Charger" 1337 "Barnacle Systems" 1348 "Radian IoT" 1353 "Ocean LED Marine" 1359 "BluNav" 1361 "OVA (Nantong Saiyang Electronics Co., Ltd)" 1368 "RAD Propulsion" 1369 "Electric Yacht" 1372 "Elco Motor Yachts" 1384 "Tecnoseal Foundry S.r.l" 1385 "Pro Charging Systems" 1389 "EVEX" 1398 "Gobius Sensor Technology" 1403 "Arco Marine" 1408 "Lenco Marine" 1413 "Naocontrol" 1417 "Revatek" 1438 "Aeolionics" 1439 "PredictWind" 1440 "Egis Mobile Electric" 1445 "Starboard Yacht Group" 1446 "Roswell Marine" 1451 "ePropulsion (Guangdong ePropulsion Technology Ltd.)" 1452 "Micro-Air" 1453 "Vital Battery" 1458 "Ride Controller" 1460 "Tocaro Blue" 1461 "Vanquish Yachts" 1471 "FT Technologies" 1478 "Alps Alpine" 1481 "E-Force Marine" 1482 "CMC Marine" 1483 "Nanjing Sandemarine Information Technology" 1850 "Teleflex Marine (SeaStar Solutions)" 1851 "Raymarine" 1852 "Navionics" 1853 "Japan Radio" 1854 "Northstar Technologies" 1855 "Furuno" 1856 "Trimble" 1857 "Simrad" 1858 "Litton" 1859 "Kvasar" 1860 "MMP" 1861 "Vector Cantech" 1862 "Yamaha Marine" 1863 "Faria Instruments" ;
VAL_ 2583629824 Industry_Code 0 "Global" 1 "Highway" 2 "Agriculture" 3 "Construction" 4 "Marine Industry" 5 "Industrial" ;
VAL_ 2583630080 Manufacturer_Code 69 "ARKS Enterprises" 78 "FW Murphy/Enovation Controls" 80 "Twin Disc" 85 "Kohler Power Systems" 88 "Hemisphere GPS" 135 "Airmar" 137 "Maretron" 140 "Lowrance" 144 "Mercury Marine" 147 "Nautibus Electronic" 148 "Blue Water Data" 154 "Westerbeke" 157 "ISSPRO" 161 "Offshore Systems (UK)" 163 "Evinrude/BRP" 165 "CPAC Systems" 168 "Xantrex Technology" 169 "Marlin Technologies" 172 "Yanmar Marine" 174 "Volvo Penta" 176 "Carling Technologies Inc. (Moritz Aerospace)" 185 "Beede Instruments" 192 "Floscan Instrument" 193 "Nobeltec" 198 "Mystic Valley Communications" 199 "Actia" 201 "Disenos Y Technologia" 211 "Digital Switching Systems" 215 "Xintex/Atena" 224 "EMMI NETWORK" 228 "ZF" 229 "Garmin" 233 "Yacht Monitoring Solutions" 235 "Sailormade Marine Telemetry/Tetra Technology" 243 "Eride" 257 "Honda Motor" 272 "Groco" 273 "Actisense" 274 "Amphenol LTW Technology" 275 "Navico" 283 "Hamilton Jet" 285 "Sea Recovery" 286 "Coelmo SRL Italy" 295 "BEP Marine" 304 "Empir Bus" 305 "NovAtel" 306 "Sleipner Motor" 307 "MBW Technologies" 315 "ICOM" 328 "Qwerty" 329 "Dief" 341 "Boening Automationstechnologie" 345 "Korean Maritime University" 351 "Thrane and Thrane" 355 "Mastervolt" 356 "Fischer Panda Generators" 358 "Victron Energy" 370 "Rolls Royce Marine" 373 "Electronic Design" 374 "Northern Lights" 378 "Glendinning" 381 "B & G" 384 "Rose Point Navigation Systems" 385 "Johnson Outdoors Marine Electronics Inc Geonav" 394 "Capi 2" 396 "Beyond Measure" 400 "Livorsi Marine" 404 "ComNav" 409 "Chetco" 419 "Fusion Electronics" 421 "Standard Horizon" 422 "True Heading" 426 "Egersund Marine Electronics" 427 "em-trak Marine Electronics" 431 "Tohatsu Co, JP" 437 "Digital Yacht" 438 "Comar Systems Limited" 440 "Cummins" 443 "VDO (aka Continental-Corporation)" 451 "Parker Hannifin aka Village Marine Tech" 459 "Alltek Marine Electronics" 460 "SAN GIORGIO S.E.I.N" 466 "Veethree Electronics & Marine" 470 "SI-TEX Marine Electronics" 471 "Sea Cross Marine" 475 "GME aka Standard Communications" 476 "Humminbird Marine Electronics" 478 "Ocean Sat" 481 "Chetco Digital Instruments" 493 "Watcheye" 499 "Lcj Capteurs" 502 "Attwood Marine" 503 "Naviop S.R.L." 504 "Vesper Marine" 510 "Marinesoft" 513 "Simarine" 517 "NoLand Engineering" 518 "Transas USA" 529 "National Instruments Korea" 530 "National Marine Electronics Association" 532 "Onwa Marine" 540 "Webasto" 571 "Marinecraft (South Korea)" 573 "McMurdo Group aka Orolia" 578 "Advansea" 579 "KVH" 580 "San Jose Technology" 583 "Yacht Control" 586 "Suzuki Motor" 591 "US Coast Guard" 595 "Ship Module aka Customware" 600 "Aquatic AV" 605 "Aventics" 606 "Intellian" 612 "SamwonIT" 614 "Arlt Tecnologies" 637 "Bavaria Yachts" 641 "Diverse Yacht Services" 644 "Wema U.S.A dba KUS" 658 "Shenzhen Jiuzhou Himunication" 688 "Rockford" 699 "Harman International" 704 "JL Audio" 708 "Lars Thrane" 715 "Autonnic" 717 "Yacht Devices" 734 "REAP Systems" 735 "AEM Performance Electronics" 739 "LxNav" 741 "Littelfuse, Inc (formerly Carling Technologies)" 743 "DaeMyung" 744 "Woosung" 748 "ISOTTA IFRA srl" 773 "Clarion US" 776 "HMI Systems" 777 "Ocean Signal" 778 "Seakeeper" 781 "Poly Planar" 785 "Fischer Panda DE" 795 "Broyda Industries" 796 "Canadian Automotive" 797 "Tides Marine" 798 "Lumishore" 799 "Still Water Designs and Audio" 802 "BJ Technologies (Beneteau)" 803 "Gill Sensors" 811 "Blue Water Desalination" 815 "FLIR" 824 "Undheim Systems" 826 "Lewmar" 838 "TeamSurv" 844 "Fell Marine" 847 "Oceanvolt" 862 "Prospec" 868 "Data Panel" 890 "L3 Technologies" 894 "Rhodan Marine Systems" 896 "Nexfour Solutions" 905 "ASA Electronics" 909 "Marines Co (South Korea)" 911 "Nautic-on" 917 "Sentinel" 929 "JL Marine Systems" 930 "Ecotronix" 944 "Zontisa Marine" 951 "EXOR International" 962 "Timbolier Industries" 963 "TJC Micro" 968 "Cox Powertrain" 969 "Blue Seas" 981 "Kobelt Manufacturing" 992 "Blue Ocean IOT" 997 "Xenta Systems" 999 "Signal K" 1004 "Ultraflex" 1008 "Lintest SmartBoat" 1011 "Soundmax" 1020 "Team Italia Marine (Onyx Marine Automation s.r.l)" 1021 "Entratech" 1022 "ITC" 1029 "The Marine Guardian" 1047 "Sonic" 1051 "ProNav" 1053 "Vetus Maxwell INC." 1056 "Lithium Pros" 1059 "Boatrax" 1062 "Marol Co ltd" 1065 "CALYPSO Instruments" 1066 "Spot Zero Water" 1069 "Lithionics Battery" 1070 "Quick-teck Electronics" 1075 "Uniden America" 1083 "Nauticoncept" 1084 "Shadow-Caster LED lighting" 1085 "Wet Sounds" 1088 "E-T-A Circuit Breakers" 1092 "Scheiber" 1100 "Smart Yachts International Limited" 1109 "Dockmate" 1114 "Bobs Machine" 1118 "L3Harris ASV" 1119 "Balmar" 1120 "Elettromedia" 1127 "Electromaax" 1140 "Across Oceans Systems" 1145 "Kiwi Yachting" 1150 "BSB Artificial Intelligence" 1151 "Orca Technologies" 1154 "TBS Electronics" 1158 "Technoton Electroics" 1160 "MG Energy Systems" 1169 "Sea Machine Robotics" 1171 "Vista Manufacturing" 1183 "Zipwake" 1186 "Sailmon" 1192 "Airmoniq Pro Kft" 1194 "Sierra Marine" 1200 "Xinuo Information Technology (Xiamen)" 1218 "Septentrio" 1233 "NKE Marine Electronics" 1238 "SuperTrack Aps" 1239 "Honda Electronics" 1245 "Raritan Engineering" 1249 "Integrated Power Solutions AG" 1260 "Interactive Technologies" 1283 "LTG-Tech" 1299 "Energy Solutions (UK)" 1300 "WATT Fuel Cell" 1302 "Pro Mainer" 1305 "Dragonfly Energy" 1306 "Koden Electronics" 1311 "Humphree" 1316 "Hinkley Yachts" 1317 "Global Marine Management GmbH (GMM)" 1320 "Triskel Marine" 1330 "Warwick Control Technologies" 1331 "Dolphin Charger" 1337 "Barnacle Systems" 1348 "Radian IoT" 1353 "Ocean LED Marine" 1359 "BluNav" 1361 "OVA (Nantong Saiyang Electronics Co., Ltd)" 1368 "RAD Propulsion" 1369 "Electric Yacht" 1372 "Elco Motor Yachts" 1384 "Tecnoseal Foundry S.r.l" 1385 "Pro Charging Systems" 1389 "EVEX" 1398 "Gobius Sensor Technology" 1403 "Arco Marine" 1408 "Lenco Marine" 1413 "Naocontrol" 1417 "Revatek" 1438 "Aeolionics" 1439 "PredictWind" 1440 "Egis Mobile Electric" 1445 "Starboard Yacht Group" 1446 "Roswell Marine" 1451 "ePropulsion (Guangdong ePropulsion Technology Ltd.)" 1452 "Micro-Air" 1453 "Vital Battery" 1458 "Ride Controller" 1460 "Tocaro Blue" 1461 "Vanquish Yachts" 1471 "FT Technologies" 1478 "Alps Alpine" 1481 "E-Force Marine" 1482 "CMC Marine" 1483 "Nanjing Sandemarine Information Technology" 1850 "Teleflex Marine (SeaStar Solutions)" 1851 "Raymarine" 1852 "Navionics" 1853 "Japan Radio" 1854 "Northstar Technologies" 1855 "Furuno" 1856 "Trimble" 1857 "Simrad" 1858 "Litton" 1859 "Kvasar" 1860 "MMP" 1861 "Vector Cantech" 1862 "Yamaha Marine" 1863 "Faria Instruments" ;
VAL_ 2583630080 Industry_Code 0 "Global" 1 "Highway" 2 "Agriculture" 3 "Construction" 4 "Marine Industry" 5 "Industrial" ;
VAL_ 2583630080 Decimals 0 "0" 1 "1" 2 "2" 3 "3" 4 "4" 254 "Auto" ;
VAL_ 2650738944 Manufacturer_Code 69 "ARKS Enterprises" 78 "FW Murphy/Enovation Controls" 80 "Twin Disc" 85 "Kohler Power Systems" 88 "Hemisphere GPS" 135 "Airmar" 137 "Maretron" 140 "Lowrance" 144 "Mercury Marine" 147 "Nautibus Electronic" 148 "Blue Water Data" 154 "Westerbeke" 157 "ISSPRO" 161 "Offshore Systems (UK)" 163 "Evinrude/BRP" 165 "CPAC Systems" 168 "Xantrex Technology" 169 "Marlin Technologies" 172 "Yanmar Marine" 174 "Volvo Penta" 176 "Carling Technologies Inc. (Moritz Aerospace)" 185 "Beede Instruments" 192 "Floscan Instrument" 193 "Nobeltec" 198 "Mystic Valley Communications" 199 "Actia" 201 "Disenos Y Technologia" 211 "Digital Switching Systems" 215 "Xintex/Atena" 224 "EMMI NETWORK" 228 "ZF" 229 "Garmin" 233 "Yacht Monitoring Solutions" 235 "Sailormade Marine Telemetry/Tetra Technology" 243 "Eride" 257 "Honda Motor" 272 "Groco" 273 "Actisense" 274 "Amphenol LTW Technology" 275 "Navico" 283 "Hamilton Jet" 285 "Sea Recovery" 286 "Coelmo SRL Italy" 295 "BEP Marine" 304 "Empir Bus" 305 "NovAtel" 306 "Sleipner Motor" 307 "MBW Technologies" 315 "ICOM" 328 "Qwerty" 329 "Dief" 341 "Boening Automationstechnologie" 345 "Korean Maritime University" 351 "Thrane and Thrane" 355 "Mastervolt" 356 "Fischer Panda Generators" 358 "Victron Energy" 370 "Rolls Royce Marine" 373 "Electronic Design" 374 "Northern Lights" 378 "Glendinning" 381 "B & G" 384 "Rose Point Navigation Systems" 385 "Johnson Outdoors Marine Electronics Inc Geonav" 394 "Capi 2" 396 "Beyond Measure" 400 "Livorsi Marine" 404 "ComNav" 409 "Chetco" 419 "Fusion Electronics" 421 "Standard Horizon" 422 "True Heading" 426 "Egersund Marine Electronics" 427 "em-trak Marine Electronics" 431 "Tohatsu Co, JP" 437 "Digital Yacht" 438 "Comar Systems Limited" 440 "Cummins" 443 "VDO (aka Continental-Corporation)" 451 "Parker Hannifin aka Village Marine Tech" 459 "Alltek Marine Electronics" 460 "SAN GIORGIO S.E.I.N" 466 "Veethree Electronics & Marine" 470 "SI-TEX Marine Electronics" 471 "Sea Cross Marine" 475 "GME aka Standard Communications" 476 "Humminbird Marine Electronics" 478 "Ocean Sat" 481 "Chetco Digital Instruments" 493 "Watcheye" 499 "Lcj Capteurs" 502 "Attwood Marine" 503 "Naviop S.R.L." 504 "Vesper Marine" 510 "Marinesoft" 513 "Simarine" 517 "NoLand Engineering" 518 "Transas USA" 529 "National Instruments Korea" 530 "National Marine Electronics Association" 532 "Onwa Marine" 540 "Webasto" 571 "Marinecraft (South Korea)" 573 "McMurdo Group aka Orolia" 578 "Advansea" 579 "KVH" 580 "San Jose Technology" 583 "Yacht Control" 586 "Suzuki Motor" 591 "US Coast Guard" 595 "Ship Module aka Customware" 600 "Aquatic AV" 605 "Aventics" 606 "Intellian" 612 "SamwonIT" 614 "Arlt Tecnologies" 637 "Bavaria Yachts" 641 "Diverse Yacht Services" 644 "Wema U.S.A dba KUS" 658 "Shenzhen Jiuzhou Himunication" 688 "Rockford" 699 "Harman International" 704 "JL Audio" 708 "Lars Thrane" 715 "Autonnic" 717 "Yacht Devices" 734 "REAP Systems" 735 "AEM Performance Electronics" 739 "LxNav" 741 "Littelfuse, Inc (formerly Carling Technologies)" 743 "DaeMyung" 744 "Woosung" 748 "ISOTTA IFRA srl" 773 "Clarion US" 776 "HMI Systems" 777 "Ocean Signal" 778 "Seakeeper" 781 "Poly Planar" 785 "Fischer Panda DE" 795 "Broyda Industries" 796 "Canadian Automotive" 797 "Tides Marine" 798 "Lumishore" 799 "Still Water Designs and Audio" 802 "BJ Technologies (Beneteau)" 803 "Gill Sensors" 811 "Blue Water Desalination" 815 "FLIR" 824 "Undheim Systems" 826 "Lewmar" 838 "TeamSurv" 844 "Fell Marine" 847 "Oceanvolt" 862 "Prospec" 868 "Data Panel" 890 "L3 Technologies" 894 "Rhodan Marine Systems" 896 "Nexfour Solutions" 905 "ASA Electronics" 909 "Marines Co (South Korea)" 911 "Nautic-on" 917 "Sentinel" 929 "JL Marine Systems" 930 "Ecotronix" 944 "Zontisa Marine" 951 "EXOR International" 962 "Timbolier Industries" 963 "TJC Micro" 968 "Cox Powertrain" 969 "Blue Seas" 981 "Kobelt Manufacturing" 992 "Blue Ocean IOT" 997 "Xenta Systems" 999 "Signal K" 1004 "Ultraflex" 1008 "Lintest SmartBoat" 1011 "Soundmax" 1020 "Team Italia Marine (Onyx Marine Automation s.r.l)" 1021 "Entratech" 1022 "ITC" 1029 "The Marine Guardian" 1047 "Sonic" 1051 "ProNav" 1053 "Vetus Maxwell INC." 1056 "Lithium Pros" 1059 "Boatrax" 1062 "Marol Co ltd" 1065 "CALYPSO Instruments" 1066 "Spot Zero Water" 1069 "Lithionics Battery" 1070 "Quick-teck Electronics" 1075 "Uniden America" 1083 "Nauticoncept" 1084 "Shadow-Caster LED lighting" 1085 "Wet Sounds" 1088 "E-T-A Circuit Breakers" 1092 "Scheiber" 1100 "Smart Yachts International Limited" 1109 "Dockmate" 1114 "Bobs Machine" 1118 "L3Harris ASV" 1119 "Balmar" 1120 "Elettromedia" 1127 "Electromaax" 1140 "Across Oceans Systems" 1145 "Kiwi Yachting" 1150 "BSB Artificial Intelligence" 1151 "Orca Technologies" 1154 "TBS Electronics" 1158 "Technoton Electroics" 1160 "MG Energy Systems" 1169 "Sea Machine Robotics" 1171 "Vista Manufacturing" 1183 "Zipwake" 1186 "Sailmon" 1192 "Airmoniq Pro Kft" 1194 "Sierra Marine" 1200 "Xinuo Information Technology (Xiamen)" 1218 "Septentrio" 1233 "NKE Marine Electronics" 1238 "SuperTrack Aps" 1239 "Honda Electronics" 1245 "Raritan Engineering" 1249 "Integrated Power Solutions AG" 1260 "Interactive Technologies" 1283 "LTG-Tech" 1299 "Energy Solutions (UK)" 1300 "WATT Fuel Cell" 1302 "Pro Mainer" 1305 "Dragonfly Energy" 1306 "Koden Electronics" 1311 "Humphree" 1316 "Hinkley Yachts" 1317 "Global Marine Management GmbH (GMM)" 1320 "Triskel Marine" 1330 "Warwick Control Technologies" 1331 "Dolphin Charger" 1337 "Barnacle Systems" 1348 "Radian IoT" 1353 "Ocean LED Marine" 1359 "BluNav" 1361 "OVA (Nantong Saiyang Electronics Co., Ltd)" 1368 "RAD Propulsion" 1369 "Electric Yacht" 1372 "Elco Motor Yachts" 1384 "Tecnoseal Foundry S.r.l" 1385 "Pro Charging Systems" 1389 "EVEX" 1398 "Gobius Sensor Technology" 1403 "Arco Marine" 1408 "Lenco Marine" 1413 "Naocontrol" 1417 "Revatek" 1438 "Aeolionics" 1439 "PredictWind" 1440 "Egis Mobile Electric" 1445 "Starboard Yacht Group" 1446 "Roswell Marine" 1451 "ePropulsion (Guangdong ePropulsion Technology Ltd.)" 1452 "Micro-Air" 1453 "Vital Battery" 1458 "Ride Controller" 1460 "Tocaro Blue" 1461 "Vanquish Yachts" 1471 "FT Technologies" 1478 "Alps Alpine" 1481 "E-Force Marine" 1482 "CMC Marine" 1483 "Nanjing Sandemarine Information Technology" 1850 "Teleflex Marine (SeaStar Solutions)" 1851 "Raymarine" 1852 "Navionics" 1853 "Japan Radio" 1854 "Northstar Technologies" 1855 "Furuno" 1856 "Trimble" 1857 "Simrad" 1858 "Litton" 1859 "Kvasar" 1860 "MMP" 1861 "Vector Cantech" 1862 "Yamaha Marine" 1863 "Faria Instruments" ;
VAL_ 2650738944 Industry_Code 0 "Global" 1 "Highway" 2 "Agriculture" 3 "Construction" 4 "Marine Industry" 5 "Industrial" ;
VAL_ 2650738944 Manufacturer_Code 69 "ARKS Enterprises" 78 "FW Murphy/Enovation Controls" 80 "Twin Disc" 85 "Kohler Power Systems" 88 "Hemisphere GPS" 135 "Airmar" 137 "Maretron" 140 "Lowrance" 144 "Mercury Marine" 147 "Nautibus Electronic" 148 "Blue Water Data" 154 "Westerbeke" 157 "ISSPRO" 161 "Offshore Systems (UK)" 163 "Evinrude/BRP" 165 "CPAC Systems" 168 "Xantrex Technology" 169 "Marlin Technologies" 172 "Yanmar Marine" 174 "Volvo Penta" 176 "Carling Technologies Inc. (Moritz Aerospace)" 185 "Beede Instruments" 192 "Floscan Instrument" 193 "Nobeltec" 198 "Mystic Valley Communications" 199 "Actia" 201 "Disenos Y Technologia" 211 "Digital Switching Systems" 215 "Xintex/Atena" 224 "EMMI NETWORK" 228 "ZF" 229 "Garmin" 233 "Yacht Monitoring Solutions" 235 "Sailormade Marine Telemetry/Tetra Technology" 243 "Eride" 257 "Honda Motor" 272 "Groco" 273 "Actisense" 274 "Amphenol LTW Technology" 275 "Navico" 283 "Hamilton Jet" 285 "Sea Recovery" 286 "Coelmo SRL Italy" 295 "BEP Marine" 304 "Empir Bus" 305 "NovAtel" 306 "Sleipner Motor" 307 "MBW Technologies" 315 "ICOM" 328 "Qwerty" 329 "Dief" 341 "Boening Automationstechnologie" 345 "Korean Maritime University" 351 "Thrane and Thrane" 355 "Mastervolt" 356 "Fischer Panda Generators" 358 "Victron Energy" 370 "Rolls Royce Marine" 373 "Electronic Design" 374 "Northern Lights" 378 "Glendinning" 381 "B & G" 384 "Rose Point Navigation Systems" 385 "Johnson Outdoors Marine Electronics Inc Geonav" 394 "Capi 2" 396 "Beyond Measure" 400 "Livorsi Marine" 404 "ComNav" 409 "Chetco" 419 "Fusion Electronics" 421 "Standard Horizon" 422 "True Heading" 426 "Egersund Marine Electronics" 427 "em-trak Marine Electronics" 431 "Tohatsu Co, JP" 437 "Digital Yacht" 438 "Comar Systems Limited" 440 "Cummins" 443 "VDO (aka Continental-Corporation)" 451 "Parker Hannifin aka Village Marine Tech" 459 "Alltek Marine Electronics" 460 "SAN GIORGIO S.E.I.N" 466 "Veethree Electronics & Marine" 470 "SI-TEX Marine Electronics" 471 "Sea Cross Marine" 475 "GME aka Standard Communications" 476 "Humminbird Marine Electronics" 478 "Ocean Sat" 481 "Chetco Digital Instruments" 493 "Watcheye" 499 "Lcj Capteurs" 502 "Attwood Marine" 503 "Naviop S.R.L." 504 "Vesper Marine" 510 "Marinesoft" 513 "Simarine" 517 "NoLand Engineering" 518 "Transas USA" 529 "National Instruments Korea" 530 "National Marine Electronics Association" 532 "Onwa Marine" 540 "Webasto" 571 "Marinecraft (South Korea)" 573 "McMurdo Group aka Orolia" 578 "Advansea" 579 "KVH" 580 "San Jose Technology" 583 "Yacht Control" 586 "Suzuki Motor" 591 "US Coast Guard" 595 "Ship Module aka Customware" 600 "Aquatic AV" 605 "Aventics" 606 "Intellian" 612 "SamwonIT" 614 "Arlt Tecnologies" 637 "Bavaria Yachts" 641 "Diverse Yacht Services" 644 "Wema U.S.A dba KUS" 658 "Shenzhen Jiuzhou Himunication" 688 "Rockford" 699 "Harman International" 704 "JL Audio" 708 "Lars Thrane" 715 "Autonnic" 717 "Yacht Devices" 734 "REAP Systems" 735 "AEM Performance Electronics" 739 "LxNav" 741 "Littelfuse, Inc (formerly Carling Technologies)" 743 "DaeMyung" 744 "Woosung" 748 "ISOTTA IFRA srl" 773 "Clarion US" 776 "HMI Systems" 777 "Ocean Signal" 778 "Seakeeper" 781 "Poly Planar" 785 "Fischer Panda DE" 795 "Broyda Industries" 796 "Canadian Automotive" 797 "Tides Marine" 798 "Lumishore" 799 "Still Water Designs and Audio" 802 "BJ Technologies (Beneteau)" 803 "Gill Sensors" 811 "Blue Water Desalination" 815 "FLIR" 824 "Undheim Systems" 826 "Lewmar" 838 "TeamSurv" 844 "Fell Marine" 847 "Oceanvolt" 862 "Prospec" 868 "Data Panel" 890 "L3 Technologies" 894 "Rhodan Marine Systems" 896 "Nexfour Solutions" 905 "ASA Electronics" 909 "Marines Co (South Korea)" 911 "Nautic-on" 917 "Sentinel" 929 "JL Marine Systems" 930 "Ecotronix" 944 "Zontisa Marine" 951 "EXOR International" 962 "Timbolier Industries" 963 "TJC Micro" 968 "Cox Powertrain" 969 "Blue Seas" 981 "Kobelt Manufacturing" 992 "Blue Ocean IOT" 997 "Xenta Systems" 999 "Signal K" 1004 "Ultraflex" 1008 "Lintest SmartBoat" 1011 "Soundmax" 1020 "Team Italia Marine (Onyx Marine Automation s.r.l)" 1021 "Entratech" 1022 "ITC" 1029 "The Marine Guardian" 1047 "Sonic" 1051 "ProNav" 1053 "Vetus Maxwell INC." 1056 "Lithium Pros" 1059 "Boatrax" 1062 "Marol Co ltd" 1065 "CALYPSO Instruments" 1066 "Spot Zero Water" 1069 "Lithionics Battery" 1070 "Quick-teck Electronics" 1075 "Uniden America" 1083 "Nauticoncept" 1084 "Shadow-Caster LED lighting" 1085 "Wet Sounds" 1088 "E-T-A Circuit Breakers" 1092 "Scheiber" 1100 "Smart Yachts International Limited" 1109 "Dockmate" 1114 "Bobs Machine" 1118 "L3Harris ASV" 1119 "Balmar" 1120 "Elettromedia" 1127 "Electromaax" 1140 "Across Oceans Systems" 1145 "Kiwi Yachting" 1150 "BSB Artificial Intelligence" 1151 "Orca Technologies" 1154 "TBS Electronics" 1158 "Technoton Electroics" 1160 "MG Energy Systems" 1169 "Sea Machine Robotics" 1171 "Vista Manufacturing" 1183 "Zipwake" 1186 "Sailmon" 1192 "Airmoniq Pro Kft" 1194 "Sierra Marine" 1200 "Xinuo Information Technology (Xiamen)" 1218 "Septentrio" 1233 "NKE Marine Electronics" 1238 "SuperTrack Aps" 1239 "Honda Electronics" 1245 "Raritan Engineering" 1249 "Integrated Power Solutions AG" 1260 "Interactive Technologies" 1283 "LTG-Tech" 1299 "Energy Solutions (UK)" 1300 "WATT Fuel Cell" 1302 "Pro Mainer" 1305 "Dragonfly Energy" 1306 "Koden Electronics" 1311 "Humphree" 1316 "Hinkley Yachts" 1317 "Global Marine Management GmbH (GMM)" 1320 "Triskel Marine" 1330 "Warwick Control Technologies" 1331 "Dolphin Charger" 1337 "Barnacle Systems" 1348 "Radian IoT" 1353 "Ocean LED Marine" 1359 "BluNav" 1361 "OVA (Nantong Saiyang Electronics Co., Ltd)" 1368 "RAD Propulsion" 1369 "Electric Yacht" 1372 "Elco Motor Yachts" 1384 "Tecnoseal Foundry S.r.l" 1385 "Pro Charging Systems" 1389 "EVEX" 1398 "Gobius Sensor Technology" 1403 "Arco Marine" 1408 "Lenco Marine" 1413 "Naocontrol" 1417 "Revatek" 1438 "Aeolionics" 1439 "PredictWind" 1440 "Egis Mobile Electric" 1445 "Starboard Yacht Group" 1446 "Roswell Marine" 1451 "ePropulsion (Guangdong ePropulsion Technology Ltd.)" 1452 "Micro-Air" 1453 "Vital Battery" 1458 "Ride Controller" 1460 "Tocaro Blue" 1461 "Vanquish Yachts" 1471 "FT Technologies" 1478 "Alps Alpine" 1481 "E-Force Marine" 1482 "CMC Marine" 1483 "Nanjing Sandemarine Information Technology" 1850 "Teleflex Marine (SeaStar Solutions)" 1851 "Raymarine" 1852 "Navionics" 1853 "Japan Radio" 1854 "Northstar Technologies" 1855 "Furuno" 1856 "Trimble" 1857 "Simrad" 1858 "Litton" 1859 "Kvasar" 1860 "MMP" 1861 "Vector Cantech" 1862 "Yamaha Marine" 1863 "Faria Instruments" ;
VAL_ 2650738944 Industry_Code 0 "Global" 1 "Highway" 2 "Agriculture" 3 "Construction" 4 "Marine Industry" 5 "Industrial" ;
VAL_ 2650739200 Manufacturer_Code 69 "ARKS Enterprises" 78 "FW Murphy/Enovation Controls" 80 "Twin Disc" 85 "Kohler Power Systems" 88 "Hemisphere GPS" 135 "Airmar" 137 "Maretron" 140 "Lowrance" 144 "Mercury Marine" 147 "Nautibus Electronic" 148 "Blue Water Data" 154 "Westerbeke" 157 "ISSPRO" 161 "Offshore Systems (UK)" 163 "Evinrude/BRP" 165 "CPAC Systems" 168 "Xantrex Technology" 169 "Marlin Technologies" 172 "Yanmar Marine" 174 "Volvo Penta" 176 "Carling Technologies Inc. (Moritz Aerospace)" 185 "Beede Instruments" 192 "Floscan Instrument" 193 "Nobeltec" 198 "Mystic Valley Communications" 199 "Actia" 201 "Disenos Y Technologia" 211 "Digital Switching Systems" 215 "Xintex/Atena" 224 "EMMI NETWORK" 228 "ZF" 229 "Garmin" 233 "Yacht Monitoring Solutions" 235 "Sailormade Marine Telemetry/Tetra Technology" 243 "Eride" 257 "Honda Motor" 272 "Groco" 273 "Actisense" 274 "Amphenol LTW Technology" 275 "Navico" 283 "Hamilton Jet" 285 "Sea Recovery" 286 "Coelmo SRL Italy" 295 "BEP Marine" 304 "Empir Bus" 305 "NovAtel" 306 "Sleipner Motor" 307 "MBW Technologies" 315 "ICOM" 328 "Qwerty" 329 "Dief" 341 "Boening Automationstechnologie" 345 "Korean Maritime University" 351 "Thrane and Thrane" 355 "Mastervolt" 356 "Fischer Panda Generators" 358 "Victron Energy" 370 "Rolls Royce Marine" 373 "Electronic Design" 374 "Northern Lights" 378 "Glendinning" 381 "B & G" 384 "Rose Point Navigation Systems" 385 "Johnson Outdoors Marine Electronics Inc Geonav" 394 "Capi 2" 396 "Beyond Measure" 400 "Livorsi Marine" 404 "ComNav" 409 "Chetco" 419 "Fusion Electronics" 421 "Standard Horizon" 422 "True Heading" 426 "Egersund Marine Electronics" 427 "em-trak Marine Electronics" 431 "Tohatsu Co, JP" 437 "Digital Yacht" 438 "Comar Systems Limited" 440 "Cummins" 443 "VDO (aka Continental-Corporation)" 451 "Parker Hannifin aka Village Marine Tech" 459 "Alltek Marine Electronics" 460 "SAN GIORGIO S.E.I.N" 466 "Veethree Electronics & Marine" 470 "SI-TEX Marine Electronics" 471 "Sea Cross Marine" 475 "GME aka Standard Communications" 476 "Humminbird Marine Electronics" 478 "Ocean Sat" 481 "Chetco Digital Instruments" 493 "Watcheye" 499 "Lcj Capteurs" 502 "Attwood Marine" 503 "Naviop S.R.L." 504 "Vesper Marine" 510 "Marinesoft" 513 "Simarine" 517 "NoLand Engineering" 518 "Transas USA" 529 "National Instruments Korea" 530 "National Marine Electronics Association" 532 "Onwa Marine" 540 "Webasto" 571 "Marinecraft (South Korea)" 573 "McMurdo Group aka Orolia" 578 "Advansea" 579 "KVH" 580 "San Jose Technology" 583 "Yacht Control" 586 "Suzuki Motor" 591 "US Coast Guard" 595 "Ship Module aka Customware" 600 "Aquatic AV" 605 "Aventics" 606 "Intellian" 612 "SamwonIT" 614 "Arlt Tecnologies" 637 "Bavaria Yachts" 641 "Diverse Yacht Services" 644 "Wema U.S.A dba KUS" 658 "Shenzhen Jiuzhou Himunication" 688 "Rockford" 699 "Harman International" 704 "JL Audio" 708 "Lars Thrane" 715 "Autonnic" 717 "Yacht Devices" 734 "REAP Systems" 735 "AEM Performance Electronics" 739 "LxNav" 741 "Littelfuse, Inc (formerly Carling Technologies)" 743 "DaeMyung" 744 "Woosung" 748 "ISOTTA IFRA srl" 773 "Clarion US" 776 "HMI Systems" 777 "Ocean Signal" 778 "Seakeeper" 781 "Poly Planar" 785 "Fischer Panda DE" 795 "Broyda Industries" 796 "Canadian Automotive" 797 "Tides Marine" 798 "Lumishore" 799 "Still Water Designs and Audio" 802 "BJ Technologies (Beneteau)" 803 "Gill Sensors" 811 "Blue Water Desalination" 815 "FLIR" 824 "Undheim Systems" 826 "Lewmar" 838 "TeamSurv" 844 "Fell Marine" 847 "Oceanvolt" 862 "Prospec" 868 "Data Panel" 890 "L3 Technologies" 894 "Rhodan Marine Systems" 896 "Nexfour Solutions" 905 "ASA Electronics" 909 "Marines Co (South Korea)" 911 "Nautic-on" 917 "Sentinel" 929 "JL Marine Systems" 930 "Ecotronix" 944 "Zontisa Marine" 951 "EXOR International" 962 "Timbolier Industries" 963 "TJC Micro" 968 "Cox Powertrain" 969 "Blue Seas" 981 "Kobelt Manufacturing" 992 "Blue Ocean IOT" 997 "Xenta Systems" 999 "Signal K" 1004 "Ultraflex" 1008 "Lintest SmartBoat" 1011 "Soundmax" 1020 "Team Italia Marine (Onyx Marine Automation s.r.l)" 1021 "Entratech" 1022 "ITC" 1029 "The Marine Guardian" 1047 "Sonic" 1051 "ProNav" 1053 "Vetus Maxwell INC." 1056 "Lithium Pros" 1059 "Boatrax" 1062 "Marol Co ltd" 1065 "CALYPSO Instruments" 1066 "Spot Zero Water" 1069 "Lithionics Battery" 1070 "Quick-teck Electronics" 1075 "Uniden America" 1083 "Nauticoncept" 1084 "Shadow-Caster LED lighting" 1085 "Wet Sounds" 1088 "E-T-A Circuit Breakers" 1092 "Scheiber" 1100 "Smart Yachts International Limited" 1109 "Dockmate" 1114 "Bobs Machine" 1118 "L3Harris ASV" 1119 "Balmar" 1120 "Elettromedia" 1127 "Electromaax" 1140 "Across Oceans Systems" 1145 "Kiwi Yachting" 1150 "BSB Artificial Intelligence" 1151 "Orca Technologies" 1154 "TBS Electronics" 1158 "Technoton Electroics" 1160 "MG Energy Systems" 1169 "Sea Machine Robotics" 1171 "Vista Manufacturing" 1183 "Zipwake" 1186 "Sailmon" 1192 "Airmoniq Pro Kft" 1194 "Sierra Marine" 1200 "Xinuo Information Technology (Xiamen)" 1218 "Septentrio" 1233 "NKE Marine Electronics" 1238 "SuperTrack Aps" 1239 "Honda Electronics" 1245 "Raritan Engineering" 1249 "Integrated Power Solutions AG" 1260 "Interactive Technologies" 1283 "LTG-Tech" 1299 "Energy Solutions (UK)" 1300 "WATT Fuel Cell" 1302 "Pro Mainer" 1305 "Dragonfly Energy" 1306 "Koden Electronics" 1311 "Humphree" 1316 "Hinkley Yachts" 1317 "Global Marine Management GmbH (GMM)" 1320 "Triskel Marine" 1330 "Warwick Control Technologies" 1331 "Dolphin Charger" 1337 "Barnacle Systems" 1348 "Radian IoT" 1353 "Ocean LED Marine" 1359 "BluNav" 1361 "OVA (Nantong Saiyang Electronics Co., Ltd)" 1368 "RAD Propulsion" 1369 "Electric Yacht" 1372 "Elco Motor Yachts" 1384 "Tecnoseal Foundry S.r.l" 1385 "Pro Charging Systems" 1389 "EVEX" 1398 "Gobius Sensor Technology" 1403 "Arco Marine" 1408 "Lenco Marine" 1413 "Naocontrol" 1417 "Revatek" 1438 "Aeolionics" 1439 "PredictWind" 1440 "Egis Mobile Electric" 1445 "Starboard Yacht Group" 1446 "Roswell Marine" 1451 "ePropulsion (Guangdong ePropulsion Technology Ltd.)" 1452 "Micro-Air" 1453 "Vital Battery" 1458 "Ride Controller" 1460 "Tocaro Blue" 1461 "Vanquish Yachts" 1471 "FT Technologies" 1478 "Alps Alpine" 1481 "E-Force Marine" 1482 "CMC Marine" 1483 "Nanjing Sandemarine Information Technology" 1850 "Teleflex Marine (SeaStar Solutions)" 1851 "Raymarine" 1852 "Navionics" 1853 "Japan Radio" 1854 "Northstar Technologies" 1855 "Furuno" 1856 "Trimble" 1857 "Simrad" 1858 "Litton" 1859 "Kvasar" 1860 "MMP" 1861 "Vector Cantech" 1862 "Yamaha Marine" 1863 "Faria Instruments" ;
VAL_ 2650739200 Industry_Code 0 "Global" 1 "Highway" 2 "Agriculture" 3 "Construction" 4 "Marine Industry" 5 "Industrial" ;
VAL_ 2583630336 Manufacturer_Code 69 "ARKS Enterprises" 78 "FW Murphy/Enovation Controls" 80 "Twin Disc" 85 "Kohler Power Systems" 88 "Hemisphere GPS" 135 "Airmar" 137 "Maretron" 140 "Lowrance" 144 "Mercury Marine" 147 "Nautibus Electronic" 148 "Blue Water Data" 154 "Westerbeke" 157 "ISSPRO" 161 "Offshore Systems (UK)" 163 "Evinrude/BRP" 165 "CPAC Systems" 168 "Xantrex Technology" 169 "Marlin Technologies" 172 "Yanmar Marine" 174 "Volvo Penta" 176 "Carling Technologies Inc. (Moritz Aerospace)" 185 "Beede Instruments" 192 "Floscan Instrument" 193 "Nobeltec" 198 "Mystic Valley Communications" 199 "Actia" 201 "Disenos Y Technologia" 211 "Digital Switching Systems" 215 "Xintex/Atena" 224 "EMMI NETWORK" 228 "ZF" 229 "Garmin" 233 "Yacht Monitoring Solutions" 235 "Sailormade Marine Telemetry/Tetra Technology" 243 "Eride" 257 "Honda Motor" 272 "Groco" 273 "Actisense" 274 "Amphenol LTW Technology" 275 "Navico" 283 "Hamilton Jet" 285 "Sea Recovery" 286 "Coelmo SRL Italy" 295 "BEP Marine" 304 "Empir Bus" 305 "NovAtel" 306 "Sleipner Motor" 307 "MBW Technologies" 315 "ICOM" 328 "Qwerty" 329 "Dief" 341 "Boening Automationstechnologie" 345 "Korean Maritime University" 351 "Thrane and Thrane" 355 "Mastervolt" 356 "Fischer Panda Generators" 358 "Victron Energy" 370 "Rolls Royce Marine" 373 "Electronic Design" 374 "Northern Lights" 378 "Glendinning" 381 "B & G" 384 "Rose Point Navigation Systems" 385 "Johnson Outdoors Marine Electronics Inc Geonav" 394 "Capi 2" 396 "Beyond Measure" 400 "Livorsi Marine" 404 "ComNav" 409 "Chetco" 419 "Fusion Electronics" 421 "Standard Horizon" 422 "True Heading" 426 "Egersund Marine Electronics" 427 "em-trak Marine Electronics" 431 "Tohatsu Co, JP" 437 "Digital Yacht" 438 "Comar Systems Limited" 440 "Cummins" 443 "VDO (aka Continental-Corporation)" 451 "Parker Hannifin aka Village Marine Tech" 459 "Alltek Marine Electronics" 460 "SAN GIORGIO S.E.I.N" 466 "Veethree Electronics & Marine" 470 "SI-TEX Marine Electronics" 471 "Sea Cross Marine" 475 "GME aka Standard Communications" 476 "Humminbird Marine Electronics" 478 "Ocean Sat" 481 "Chetco Digital Instruments" 493 "Watcheye" 499 "Lcj Capteurs" 502 "Attwood Marine" 503 "Naviop S.R.L." 504 "Vesper Marine" 510 "Marinesoft" 513 "Simarine" 517 "NoLand Engineering" 518 "Transas USA" 529 "National Instruments Korea" 530 "National Marine Electronics Association" 532 "Onwa Marine" 540 "Webasto" 571 "Marinecraft (South Korea)" 573 "McMurdo Group aka Orolia" 578 "Advansea" 579 "KVH" 580 "San Jose Technology" 583 "Yacht Control" 586 "Suzuki Motor" 591 "US Coast Guard" 595 "Ship Module aka Customware" 600 "Aquatic AV" 605 "Aventics" 606 "Intellian" 612 "SamwonIT" 614 "Arlt Tecnologies" 637 "Bavaria Yachts" 641 "Diverse Yacht Services" 644 "Wema U.S.A dba KUS" 658 "Shenzhen Jiuzhou Himunication" 688 "Rockford" 699 "Harman International" 704 "JL Audio" 708 "Lars Thrane" 715 "Autonnic" 717 "Yacht Devices" 734 "REAP Systems" 735 "AEM Performance Electronics" 739 "LxNav" 741 "Littelfuse, Inc (formerly Carling Technologies)" 743 "DaeMyung" 744 "Woosung" 748 "ISOTTA IFRA srl" 773 "Clarion US" 776 "HMI Systems" 777 "Ocean Signal" 778 "Seakeeper" 781 "Poly Planar" 785 "Fischer Panda DE" 795 "Broyda Industries" 796 "Canadian Automotive" 797 "Tides Marine" 798 "Lumishore" 799 "Still Water Designs and Audio" 802 "BJ Technologies (Beneteau)" 803 "Gill Sensors" 811 "Blue Water Desalination" 815 "FLIR" 824 "Undheim Systems" 826 "Lewmar" 838 "TeamSurv" 844 "Fell Marine" 847 "Oceanvolt" 862 "Prospec" 868 "Data Panel" 890 "L3 Technologies" 894 "Rhodan Marine Systems" 896 "Nexfour Solutions" 905 "ASA Electronics" 909 "Marines Co (South Korea)" 911 "Nautic-on" 917 "Sentinel" 929 "JL Marine Systems" 930 "Ecotronix" 944 "Zontisa Marine" 951 "EXOR International" 962 "Timbolier Industries" 963 "TJC Micro" 968 "Cox Powertrain" 969 "Blue Seas" 981 "Kobelt Manufacturing" 992 "Blue Ocean IOT" 997 "Xenta Systems" 999 "Signal K" 1004 "Ultraflex" 1008 "Lintest SmartBoat" 1011 "Soundmax" 1020 "Team Italia Marine (Onyx Marine Automation s.r.l)" 1021 "Entratech" 1022 "ITC" 1029 "The Marine Guardian" 1047 "Sonic" 1051 "ProNav" 1053 "Vetus Maxwell INC." 1056 "Lithium Pros" 1059 "Boatrax" 1062 "Marol Co ltd" 1065 "CALYPSO Instruments" 1066 "Spot Zero Water" 1069 "Lithionics Battery" 1070 "Quick-teck Electronics" 1075 "Uniden America" 1083 "Nauticoncept" 1084 "Shadow-Caster LED lighting" 1085 "Wet Sounds" 1088 "E-T-A Circuit Breakers" 1092 "Scheiber" 1100 "Smart Yachts International Limited" 1109 "Dockmate" 1114 "Bobs Machine" 1118 "L3Harris ASV" 1119 "Balmar" 1120 "Elettromedia" 1127 "Electromaax" 1140 "Across Oceans Systems" 1145 "Kiwi Yachting" 1150 "BSB Artificial Intelligence" 1151 "Orca Technologies" 1154 "TBS Electronics" 1158 "Technoton Electroics" 1160 "MG Energy Systems" 1169 "Sea Machine Robotics" 1171 "Vista Manufacturing" 1183 "Zipwake" 1186 "Sailmon" 1192 "Airmoniq Pro Kft" 1194 "Sierra Marine" 1200 "Xinuo Information Technology (Xiamen)" 1218 "Septentrio" 1233 "NKE Marine Electronics" 1238 "SuperTrack Aps" 1239 "Honda Electronics" 1245 "Raritan Engineering" 1249 "Integrated Power Solutions AG" 1260 "Interactive Technologies" 1283 "LTG-Tech" 1299 "Energy Solutions (UK)" 1300 "WATT Fuel Cell" 1302 "Pro Mainer" 1305 "Dragonfly Energy" 1306 "Koden Electronics" 1311 "Humphree" 1316 "Hinkley Yachts" 1317 "Global Marine Management GmbH (GMM)" 1320 "Triskel Marine" 1330 "Warwick Control Technologies" 1331 "Dolphin Charger" 1337 "Barnacle Systems" 1348 "Radian IoT" 1353 "Ocean LED Marine" 1359 "BluNav" 1361 "OVA (Nantong Saiyang Electronics Co., Ltd)" 1368 "RAD Propulsion" 1369 "Electric Yacht" 1372 "Elco Motor Yachts" 1384 "Tecnoseal Foundry S.r.l" 1385 "Pro Charging Systems" 1389 "EVEX" 1398 "Gobius Sensor Technology" 1403 "Arco Marine" 1408 "Lenco Marine" 1413 "Naocontrol" 1417 "Revatek" 1438 "Aeolionics" 1439 "PredictWind" 1440 "Egis Mobile Electric" 1445 "Starboard Yacht Group" 1446 "Roswell Marine" 1451 "ePropulsion (Guangdong ePropulsion Technology Ltd.)" 1452 "Micro-Air" 1453 "Vital Battery" 1458 "Ride Controller" 1460 "Tocaro Blue" 1461 "Vanquish Yachts" 1471 "FT Technologies" 1478 "Alps Alpine" 1481 "E-Force Marine" 1482 "CMC Marine" 1483 "Nanjing Sandemarine Information Technology" 1850 "Teleflex Marine (SeaStar Solutions)" 1851 "Raymarine" 1852 "Navionics" 1853 "Japan Radio" 1854 "Northstar Technologies" 1855 "Furuno" 1856 "Trimble" 1857 "Simrad" 1858 "Litton" 1859 "Kvasar" 1860 "MMP" 1861 "Vector Cantech" 1862 "Yamaha Marine" 1863 "Faria Instruments" ;
VAL_ 2583630336 Industry_Code 0 "Global" 1 "Highway" 2 "Agriculture" 3 "Construction" 4 "Marine Industry" 5 "Industrial" ;
VAL_ 2583630336 Manufacturer_Code 69 "ARKS Enterprises" 78 "FW Murphy/Enovation Controls" 80 "Twin Disc" 85 "Kohler Power Systems" 88 "Hemisphere GPS" 135 "Airmar" 137 "Maretron" 140 "Lowrance" 144 "Mercury Marine" 147 "Nautibus Electronic" 148 "Blue Water Data" 154 "Westerbeke" 157 "ISSPRO" 161 "Offshore Systems (UK)" 163 "Evinrude/BRP" 165 "CPAC Systems" 168 "Xantrex Technology" 169 "Marlin Technologies" 172 "Yanmar Marine" 174 "Volvo Penta" 176 "Carling Technologies Inc. (Moritz Aerospace)" 185 "Beede Instruments" 192 "Floscan Instrument" 193 "Nobeltec" 198 "Mystic Valley Communications" 199 "Actia" 201 "Disenos Y Technologia" 211 "Digital Switching Systems" 215 "Xintex/Atena" 224 "EMMI NETWORK" 228 "ZF" 229 "Garmin" 233 "Yacht Monitoring Solutions" 235 "Sailormade Marine Telemetry/Tetra Technology" 243 "Eride" 257 "Honda Motor" 272 "Groco" 273 "Actisense" 274 "Amphenol LTW Technology" 275 "Navico" 283 "Hamilton Jet" 285 "Sea Recovery" 286 "Coelmo SRL Italy" 295 "BEP Marine" 304 "Empir Bus" 305 "NovAtel" 306 "Sleipner Motor" 307 "MBW Technologies" 315 "ICOM" 328 "Qwerty" 329 "Dief" 341 "Boening Automationstechnologie" 345 "Korean Maritime University" 351 "Thrane and Thrane" 355 "Mastervolt" 356 "Fischer Panda Generators" 358 "Victron Energy" 370 "Rolls Royce Marine" 373 "Electronic Design" 374 "Northern Lights" 378 "Glendinning" 381 "B & G" 384 "Rose Point Navigation Systems" 385 "Johnson Outdoors Marine Electronics Inc Geonav" 394 "Capi 2" 396 "Beyond Measure" 400 "Livorsi Marine" 404 "ComNav" 409 "Chetco" 419 "Fusion Electronics" 421 "Standard Horizon" 422 "True Heading" 426 "Egersund Marine Electronics" 427 "em-trak Marine Electronics" 431 "Tohatsu Co, JP" 437 "Digital Yacht" 438 "Comar Systems Limited" 440 "Cummins" 443 "VDO (aka Continental-Corporation)" 451 "Parker Hannifin aka Village Marine Tech" 459 "Alltek Marine Electronics" 460 "SAN GIORGIO S.E.I.N" 466 "Veethree Electronics & Marine" 470 "SI-TEX Marine Electronics" 471 "Sea Cross Marine" 475 "GME aka Standard Communications" 476 "Humminbird Marine Electronics" 478 "Ocean Sat" 481 "Chetco Digital Instruments" 493 "Watcheye" 499 "Lcj Capteurs" 502 "Attwood Marine" 503 "Naviop S.R.L." 504 "Vesper Marine" 510 "Marinesoft" 513 "Simarine" 517 "NoLand Engineering" 518 "Transas USA" 529 "National Instruments Korea" 530 "National Marine Electronics Association" 532 "Onwa Marine" 540 "Webasto" 571 "Marinecraft (South Korea)" 573 "McMurdo Group aka Orolia" 578 "Advansea" 579 "KVH" 580 "San Jose Technology" 583 "Yacht Control" 586 "Suzuki Motor" 591 "US Coast Guard" 595 "Ship Module aka Customware" 600 "Aquatic AV" 605 "Aventics" 606 "Intellian" 612 "SamwonIT" 614 "Arlt Tecnologies" 637 "Bavaria Yachts" 641 "Diverse Yacht Services" 644 "Wema U.S.A dba KUS" 658 "Shenzhen Jiuzhou Himunication" 688 "Rockford" 699 "Harman International" 704 "JL Audio" 708 "Lars Thrane" 715 "Autonnic" 717 "Yacht Devices" 734 "REAP Systems" 735 "AEM Performance Electronics" 739 "LxNav" 741 "Littelfuse, Inc (formerly Carling Technologies)" 743 "DaeMyung" 744 "Woosung" 748 "ISOTTA IFRA srl" 773 "Clarion US" 776 "HMI Systems" 777 "Ocean Signal" 778 "Seakeeper" 781 "Poly Planar" 785 "Fischer Panda DE" 795 "Broyda Industries" 796 "Canadian Automotive" 797 "Tides Marine" 798 "Lumishore" 799 "Still Water Designs and Audio" 802 "BJ Technologies (Beneteau)" 803 "Gill Sensors" 811 "Blue Water Desalination" 815 "FLIR" 824 "Undheim Systems" 826 "Lewmar" 838 "TeamSurv" 844 "Fell Marine" 847 "Oceanvolt" 862 "Prospec" 868 "Data Panel" 890 "L3 Technologies" 894 "Rhodan Marine Systems" 896 "Nexfour Solutions" 905 "ASA Electronics" 909 "Marines Co (South Korea)" 911 "Nautic-on" 917 "Sentinel" 929 "JL Marine Systems" 930 "Ecotronix" 944 "Zontisa Marine" 951 "EXOR International" 962 "Timbolier Industries" 963 "TJC Micro" 968 "Cox Powertrain" 969 "Blue Seas" 981 "Kobelt Manufacturing" 992 "Blue Ocean IOT" 997 "Xenta Systems" 999 "Signal K" 1004 "Ultraflex" 1008 "Lintest SmartBoat" 1011 "Soundmax" 1020 "Team Italia Marine (Onyx Marine Automation s.r.l)" 1021 "Entratech" 1022 "ITC" 1029 "The Marine Guardian" 1047 "Sonic" 1051 "ProNav" 1053 "Vetus Maxwell INC." 1056 "Lithium Pros" 1059 "Boatrax" 1062 "Marol Co ltd" 1065 "CALYPSO Instruments" 1066 "Spot Zero Water" 1069 "Lithionics Battery" 1070 "Quick-teck Electronics" 1075 "Uniden America" 1083 "Nauticoncept" 1084 "Shadow-Caster LED lighting" 1085 "Wet Sounds" 1088 "E-T-A Circuit Breakers" 1092 "Scheiber" 1100 "Smart Yachts International Limited" 1109 "Dockmate" 1114 "Bobs Machine" 1118 "L3Harris ASV" 1119 "Balmar" 1120 "Elettromedia" 1127 "Electromaax" 1140 "Across Oceans Systems" 1145 "Kiwi Yachting" 1150 "BSB Artificial Intelligence" 1151 "Orca Technologies" 1154 "TBS Electronics" 1158 "Technoton Electroics" 1160 "MG Energy Systems" 1169 "Sea Machine Robotics" 1171 "Vista Manufacturing" 1183 "Zipwake" 1186 "Sailmon" 1192 "Airmoniq Pro Kft" 1194 "Sierra Marine" 1200 "Xinuo Information Technology (Xiamen)" 1218 "Septentrio" 1233 "NKE Marine Electronics" 1238 "SuperTrack Aps" 1239 "Honda Electronics" 1245 "Raritan Engineering" 1249 "Integrated Power Solutions AG" 1260 "Interactive Technologies" 1283 "LTG-Tech" 1299 "Energy Solutions (UK)" 1300 "WATT Fuel Cell" 1302 "Pro Mainer" 1305 "Dragonfly Energy" 1306 "Koden Electronics" 1311 "Humphree" 1316 "Hinkley Yachts" 1317 "Global Marine Management GmbH (GMM)" 1320 "Triskel Marine" 1330 "Warwick Control Technologies" 1331 "Dolphin Charger" 1337 "Barnacle Systems" 1348 "Radian IoT" 1353 "Ocean LED Marine" 1359 "BluNav" 1361 "OVA (Nantong Saiyang Electronics Co., Ltd)" 1368 "RAD Propulsion" 1369 "Electric Yacht" 1372 "Elco Motor Yachts" 1384 "Tecnoseal Foundry S.r.l" 1385 "Pro Charging Systems" 1389 "EVEX" 1398 "Gobius Sensor Technology" 1403 "Arco Marine" 1408 "Lenco Marine" 1413 "Naocontrol" 1417 "Revatek" 1438 "Aeolionics" 1439 "PredictWind" 1440 "Egis Mobile Electric" 1445 "Starboard Yacht Group" 1446 "Roswell Marine" 1451 "ePropulsion (Guangdong ePropulsion Technology Ltd.)" 1452 "Micro-Air" 1453 "Vital Battery" 1458 "Ride Controller" 1460 "Tocaro Blue" 1461 "Vanquish Yachts" 1471 "FT Technologies" 1478 "Alps Alpine" 1481 "E-Force Marine" 1482 "CMC Marine" 1483 "Nanjing Sandemarine Information Technology" 1850 "Teleflex Marine (SeaStar Solutions)" 1851 "Raymarine" 1852 "Navionics" 1853 "Japan Radio" 1854 "Northstar Technologies" 1855 "Furuno" 1856 "Trimble" 1857 "Simrad" 1858 "Litton" 1859 "Kvasar" 1860 "MMP" 1861 "Vector Cantech" 1862 "Yamaha Marine" 1863 "Faria Instruments" ;
VAL_ 2583630336 Industry_Code 0 "Global" 1 "Highway" 2 "Agriculture" 3 "Construction" 4 "Marine Industry" 5 "Industrial" ;
VAL_ 2583630592 Manufacturer_Code 69 "ARKS Enterprises" 78 "FW Murphy/Enovation Controls" 80 "Twin Disc" 85 "Kohler Power Systems" 88 "Hemisphere GPS" 135 "Airmar" 137 "Maretron" 140 "Lowrance" 144 "Mercury Marine" 147 "Nautibus Electronic" 148 "Blue Water Data" 154 "Westerbeke" 157 "ISSPRO" 161 "Offshore Systems (UK)" 163 "Evinrude/BRP" 165 "CPAC Systems" 168 "Xantrex Technology" 169 "Marlin Technologies" 172 "Yanmar Marine" 174 "Volvo Penta" 176 "Carling Technologies Inc. (Moritz Aerospace)" 185 "Beede Instruments" 192 "Floscan Instrument" 193 "Nobeltec" 198 "Mystic Valley Communications" 199 "Actia" 201 "Disenos Y Technologia" 211 "Digital Switching Systems" 215 "Xintex/Atena" 224 "EMMI NETWORK" 228 "ZF" 229 "Garmin" 233 "Yacht Monitoring Solutions" 235 "Sailormade Marine Telemetry/Tetra Technology" 243 "Eride" 257 "Honda Motor" 272 "Groco" 273 "Actisense" 274 "Amphenol LTW Technology" 275 "Navico" 283 "Hamilton Jet" 285 "Sea Recovery" 286 "Coelmo SRL Italy" 295 "BEP Marine" 304 "Empir Bus" 305 "NovAtel" 306 "Sleipner Motor" 307 "MBW Technologies" 315 "ICOM" 328 "Qwerty" 329 "Dief" 341 "Boening Automationstechnologie" 345 "Korean Maritime University" 351 "Thrane and Thrane" 355 "Mastervolt" 356 "Fischer Panda Generators" 358 "Victron Energy" 370 "Rolls Royce Marine" 373 "Electronic Design" 374 "Northern Lights" 378 "Glendinning" 381 "B & G" 384 "Rose Point Navigation Systems" 385 "Johnson Outdoors Marine Electronics Inc Geonav" 394 "Capi 2" 396 "Beyond Measure" 400 "Livorsi Marine" 404 "ComNav" 409 "Chetco" 419 "Fusion Electronics" 421 "Standard Horizon" 422 "True Heading" 426 "Egersund Marine Electronics" 427 "em-trak Marine Electronics" 431 "Tohatsu Co, JP" 437 "Digital Yacht" 438 "Comar Systems Limited" 440 "Cummins" 443 "VDO (aka Continental-Corporation)" 451 "Parker Hannifin aka Village Marine Tech" 459 "Alltek Marine Electronics" 460 "SAN GIORGIO S.E.I.N" 466 "Veethree Electronics & Marine" 470 "SI-TEX Marine Electronics" 471 "Sea Cross Marine" 475 "GME aka Standard Communications" 476 "Humminbird Marine Electronics" 478 "Ocean Sat" 481 "Chetco Digital Instruments" 493 "Watcheye" 499 "Lcj Capteurs" 502 "Attwood Marine" 503 "Naviop S.R.L." 504 "Vesper Marine" 510 "Marinesoft" 513 "Simarine" 517 "NoLand Engineering" 518 "Transas USA" 529 "National Instruments Korea" 530 "National Marine Electronics Association" 532 "Onwa Marine" 540 "Webasto" 571 "Marinecraft (South Korea)" 573 "McMurdo Group aka Orolia" 578 "Advansea" 579 "KVH" 580 "San Jose Technology" 583 "Yacht Control" 586 "Suzuki Motor" 591 "US Coast Guard" 595 "Ship Module aka Customware" 600 "Aquatic AV" 605 "Aventics" 606 "Intellian" 612 "SamwonIT" 614 "Arlt Tecnologies" 637 "Bavaria Yachts" 641 "Diverse Yacht Services" 644 "Wema U.S.A dba KUS" 658 "Shenzhen Jiuzhou Himunication" 688 "Rockford" 699 "Harman International" 704 "JL Audio" 708 "Lars Thrane" 715 "Autonnic" 717 "Yacht Devices" 734 "REAP Systems" 735 "AEM Performance Electronics" 739 "LxNav" 741 "Littelfuse, Inc (formerly Carling Technologies)" 743 "DaeMyung" 744 "Woosung" 748 "ISOTTA IFRA srl" 773 "Clarion US" 776 "HMI Systems" 777 "Ocean Signal" 778 "Seakeeper" 781 "Poly Planar" 785 "Fischer Panda DE" 795 "Broyda Industries" 796 "Canadian Automotive" 797 "Tides Marine" 798 "Lumishore" 799 "Still Water Designs and Audio" 802 "BJ Technologies (Beneteau)" 803 "Gill Sensors" 811 "Blue Water Desalination" 815 "FLIR" 824 "Undheim Systems" 826 "Lewmar" 838 "TeamSurv" 844 "Fell Marine" 847 "Oceanvolt" 862 "Prospec" 868 "Data Panel" 890 "L3 Technologies" 894 "Rhodan Marine Systems" 896 "Nexfour Solutions" 905 "ASA Electronics" 909 "Marines Co (South Korea)" 911 "Nautic-on" 917 "Sentinel" 929 "JL Marine Systems" 930 "Ecotronix" 944 "Zontisa Marine" 951 "EXOR International" 962 "Timbolier Industries" 963 "TJC Micro" 968 "Cox Powertrain" 969 "Blue Seas" 981 "Kobelt Manufacturing" 992 "Blue Ocean IOT" 997 "Xenta Systems" 999 "Signal K" 1004 "Ultraflex" 1008 "Lintest SmartBoat" 1011 "Soundmax" 1020 "Team Italia Marine (Onyx Marine Automation s.r.l)" 1021 "Entratech" 1022 "ITC" 1029 "The Marine Guardian" 1047 "Sonic" 1051 "ProNav" 1053 "Vetus Maxwell INC." 1056 "Lithium Pros" 1059 "Boatrax" 1062 "Marol Co ltd" 1065 "CALYPSO Instruments" 1066 "Spot Zero Water" 1069 "Lithionics Battery" 1070 "Quick-teck Electronics" 1075 "Uniden America" 1083 "Nauticoncept" 1084 "Shadow-Caster LED lighting" 1085 "Wet Sounds" 1088 "E-T-A Circuit Breakers" 1092 "Scheiber" 1100 "Smart Yachts International Limited" 1109 "Dockmate" 1114 "Bobs Machine" 1118 "L3Harris ASV" 1119 "Balmar" 1120 "Elettromedia" 1127 "Electromaax" 1140 "Across Oceans Systems" 1145 "Kiwi Yachting" 1150 "BSB Artificial Intelligence" 1151 "Orca Technologies" 1154 "TBS Electronics" 1158 "Technoton Electroics" 1160 "MG Energy Systems" 1169 "Sea Machine Robotics" 1171 "Vista Manufacturing" 1183 "Zipwake" 1186 "Sailmon" 1192 "Airmoniq Pro Kft" 1194 "Sierra Marine" 1200 "Xinuo Information Technology (Xiamen)" 1218 "Septentrio" 1233 "NKE Marine Electronics" 1238 "SuperTrack Aps" 1239 "Honda Electronics" 1245 "Raritan Engineering" 1249 "Integrated Power Solutions AG" 1260 "Interactive Technologies" 1283 "LTG-Tech" 1299 "Energy Solutions (UK)" 1300 "WATT Fuel Cell" 1302 "Pro Mainer" 1305 "Dragonfly Energy" 1306 "Koden Electronics" 1311 "Humphree" 1316 "Hinkley Yachts" 1317 "Global Marine Management GmbH (GMM)" 1320 "Triskel Marine" 1330 "Warwick Control Technologies" 1331 "Dolphin Charger" 1337 "Barnacle Systems" 1348 "Radian IoT" 1353 "Ocean LED Marine" 1359 "BluNav" 1361 "OVA (Nantong Saiyang Electronics Co., Ltd)" 1368 "RAD Propulsion" 1369 "Electric Yacht" 1372 "Elco Motor Yachts" 1384 "Tecnoseal Foundry S.r.l" 1385 "Pro Charging Systems" 1389 "EVEX" 1398 "Gobius Sensor Technology" 1403 "Arco Marine" 1408 "Lenco Marine" 1413 "Naocontrol" 1417 "Revatek" 1438 "Aeolionics" 1439 "PredictWind" 1440 "Egis Mobile Electric" 1445 "Starboard Yacht Group" 1446 "Roswell Marine" 1451 "ePropulsion (Guangdong ePropulsion Technology Ltd.)" 1452 "Micro-Air" 1453 "Vital Battery" 1458 "Ride Controller" 1460 "Tocaro Blue" 1461 "Vanquish Yachts" 1471 "FT Technologies" 1478 "Alps Alpine" 1481 "E-Force Marine" 1482 "CMC Marine" 1483 "Nanjing Sandemarine Information Technology" 1850 "Teleflex Marine (SeaStar Solutions)" 1851 "Raymarine" 1852 "Navionics" 1853 "Japan Radio" 1854 "Northstar Technologies" 1855 "Furuno" 1856 "Trimble" 1857 "Simrad" 1858 "Litton" 1859 "Kvasar" 1860 "MMP" 1861 "Vector Cantech" 1862 "Yamaha Marine" 1863 "Faria Instruments" ;
VAL_ 2583630592 Industry_Code 0 "Global" 1 "Highway" 2 "Agriculture" 3 "Construction" 4 "Marine Industry" 5 "Industrial" ;
VAL_ 2583630592 Manufacturer_Code 69 "ARKS Enterprises" 78 "FW Murphy/Enovation Controls" 80 "Twin Disc" 85 "Kohler Power Systems" 88 "Hemisphere GPS" 135 "Airmar" 137 "Maretron" 140 "Lowrance" 144 "Mercury Marine" 147 "Nautibus Electronic" 148 "Blue Water Data" 154 "Westerbeke" 157 "ISSPRO" 161 "Offshore Systems (UK)" 163 "Evinrude/BRP" 165 "CPAC Systems" 168 "Xantrex Technology" 169 "Marlin Technologies" 172 "Yanmar Marine" 174 "Volvo Penta" 176 "Carling Technologies Inc. (Moritz Aerospace)" 185 "Beede Instruments" 192 "Floscan Instrument" 193 "Nobeltec" 198 "Mystic Valley Communications" 199 "Actia" 201 "Disenos Y Technologia" 211 "Digital Switching Systems" 215 "Xintex/Atena" 224 "EMMI NETWORK" 228 "ZF" 229 "Garmin" 233 "Yacht Monitoring Solutions" 235 "Sailormade Marine Telemetry/Tetra Technology" 243 "Eride" 257 "Honda Motor" 272 "Groco" 273 "Actisense" 274 "Amphenol LTW Technology" 275 "Navico" 283 "Hamilton Jet" 285 "Sea Recovery" 286 "Coelmo SRL Italy" 295 "BEP Marine" 304 "Empir Bus" 305 "NovAtel" 306 "Sleipner Motor" 307 "MBW Technologies" 315 "ICOM" 328 "Qwerty" 329 "Dief" 341 "Boening Automationstechnologie" 345 "Korean Maritime University" 351 "Thrane and Thrane" 355 "Mastervolt" 356 "Fischer Panda Generators" 358 "Victron Energy" 370 "Rolls Royce Marine" 373 "Electronic Design" 374 "Northern Lights" 378 "Glendinning" 381 "B & G" 384 "Rose Point Navigation Systems" 385 "Johnson Outdoors Marine Electronics Inc Geonav" 394 "Capi 2" 396 "Beyond Measure" 400 "Livorsi Marine" 404 "ComNav" 409 "Chetco" 419 "Fusion Electronics" 421 "Standard Horizon" 422 "True Heading" 426 "Egersund Marine Electronics" 427 "em-trak Marine Electronics" 431 "Tohatsu Co, JP" 437 "Digital Yacht" 438 "Comar Systems Limited" 440 "Cummins" 443 "VDO (aka Continental-Corporation)" 451 "Parker Hannifin aka Village Marine Tech" 459 "Alltek Marine Electronics" 460 "SAN GIORGIO S.E.I.N" 466 "Veethree Electronics & Marine" 470 "SI-TEX Marine Electronics" 471 "Sea Cross Marine" 475 "GME aka Standard Communications" 476 "Humminbird Marine Electronics" 478 "Ocean Sat" 481 "Chetco Digital Instruments" 493 "Watcheye" 499 "Lcj Capteurs" 502 "Attwood Marine" 503 "Naviop S.R.L." 504 "Vesper Marine" 510 "Marinesoft" 513 "Simarine" 517 "NoLand Engineering" 518 "Transas USA" 529 "National Instruments Korea" 530 "National Marine Electronics Association" 532 "Onwa Marine" 540 "Webasto" 571 "Marinecraft (South Korea)" 573 "McMurdo Group aka Orolia" 578 "Advansea" 579 "KVH" 580 "San Jose Technology" 583 "Yacht Control" 586 "Suzuki Motor" 591 "US Coast Guard" 595 "Ship Module aka Customware" 600 "Aquatic AV" 605 "Aventics" 606 "Intellian" 612 "SamwonIT" 614 "Arlt Tecnologies" 637 "Bavaria Yachts" 641 "Diverse Yacht Services" 644 "Wema U.S.A dba KUS" 658 "Shenzhen Jiuzhou Himunication" 688 "Rockford" 699 "Harman International" 704 "JL Audio" 708 "Lars Thrane" 715 "Autonnic" 717 "Yacht Devices" 734 "REAP Systems" 735 "AEM Performance Electronics" 739 "LxNav" 741 "Littelfuse, Inc (formerly Carling Technologies)" 743 "DaeMyung" 744 "Woosung" 748 "ISOTTA IFRA srl" 773 "Clarion US" 776 "HMI Systems" 777 "Ocean Signal" 778 "Seakeeper" 781 "Poly Planar" 785 "Fischer Panda DE" 795 "Broyda Industries" 796 "Canadian Automotive" 797 "Tides Marine" 798 "Lumishore" 799 "Still Water Designs and Audio" 802 "BJ Technologies (Beneteau)" 803 "Gill Sensors" 811 "Blue Water Desalination" 815 "FLIR" 824 "Undheim Systems" 826 "Lewmar" 838 "TeamSurv" 844 "Fell Marine" 847 "Oceanvolt" 862 "Prospec" 868 "Data Panel" 890 "L3 Technologies" 894 "Rhodan Marine Systems" 896 "Nexfour Solutions" 905 "ASA Electronics" 909 "Marines Co (South Korea)" 911 "Nautic-on" 917 "Sentinel" 929 "JL Marine Systems" 930 "Ecotronix" 944 "Zontisa Marine" 951 "EXOR International" 962 "Timbolier Industries" 963 "TJC Micro" 968 "Cox Powertrain" 969 "Blue Seas" 981 "Kobelt Manufacturing" 992 "Blue Ocean IOT" 997 "Xenta Systems" 999 "Signal K" 1004 "Ultraflex" 1008 "Lintest SmartBoat" 1011 "Soundmax" 1020 "Team Italia Marine (Onyx Marine Automation s.r.l)" 1021 "Entratech" 1022 "ITC" 1029 "The Marine Guardian" 1047 "Sonic" 1051 "ProNav" 1053 "Vetus Maxwell INC." 1056 "Lithium Pros" 1059 "Boatrax" 1062 "Marol Co ltd" 1065 "CALYPSO Instruments" 1066 "Spot Zero Water" 1069 "Lithionics Battery" 1070 "Quick-teck Electronics" 1075 "Uniden America" 1083 "Nauticoncept" 1084 "Shadow-Caster LED lighting" 1085 "Wet Sounds" 1088 "E-T-A Circuit Breakers" 1092 "Scheiber" 1100 "Smart Yachts International Limited" 1109 "Dockmate" 1114 "Bobs Machine" 1118 "L3Harris ASV" 1119 "Balmar" 1120 "Elettromedia" 1127 "Electromaax" 1140 "Across Oceans Systems" 1145 "Kiwi Yachting" 1150 "BSB Artificial Intelligence" 1151 "Orca Technologies" 1154 "TBS Electronics" 1158 "Technoton Electroics" 1160 "MG Energy Systems" 1169 "Sea Machine Robotics" 1171 "Vista Manufacturing" 1183 "Zipwake" 1186 "Sailmon" 1192 "Airmoniq Pro Kft" 1194 "Sierra Marine" 1200 "Xinuo Information Technology (Xiamen)" 1218 "Septentrio" 1233 "NKE Marine Electronics" 1238 "SuperTrack Aps" 1239 "Honda Electronics" 1245 "Raritan Engineering" 1249 "Integrated Power Solutions AG" 1260 "Interactive Technologies" 1283 "LTG-Tech" 1299 "Energy Solutions (UK)" 1300 "WATT Fuel Cell" 1302 "Pro Mainer" 1305 "Dragonfly Energy" 1306 "Koden Electronics" 1311 "Humphree" 1316 "Hinkley Yachts" 1317 "Global Marine Management GmbH (GMM)" 1320 "Triskel Marine" 1330 "Warwick Control Technologies" 1331 "Dolphin Charger" 1337 "Barnacle Systems" 1348 "Radian IoT" 1353 "Ocean LED Marine" 1359 "BluNav" 1361 "OVA (Nantong Saiyang Electronics Co., Ltd)" 1368 "RAD Propulsion" 1369 "Electric Yacht" 1372 "Elco Motor Yachts" 1384 "Tecnoseal Foundry S.r.l" 1385 "Pro Charging Systems" 1389 "EVEX" 1398 "Gobius Sensor Technology" 1403 "Arco Marine" 1408 "Lenco Marine" 1413 "Naocontrol" 1417 "Revatek" 1438 "Aeolionics" 1439 "PredictWind" 1440 "Egis Mobile Electric" 1445 "Starboard Yacht Group" 1446 "Roswell Marine" 1451 "ePropulsion (Guangdong ePropulsion Technology Ltd.)" 1452 "Micro-Air" 1453 "Vital Battery" 1458 "Ride Controller" 1460 "Tocaro Blue" 1461 "Vanquish Yachts" 1471 "FT Technologies" 1478 "Alps Alpine" 1481 "E-Force Marine" 1482 "CMC Marine" 1483 "Nanjing Sandemarine Information Technology" 1850 "Teleflex Marine (SeaStar Solutions)" 1851 "Raymarine" 1852 "Navionics" 1853 "Japan Radio" 1854 "Northstar Technologies" 1855 "Furuno" 1856 "Trimble" 1857 "Simrad" 1858 "Litton" 1859 "Kvasar" 1860 "MMP" 1861 "Vector Cantech" 1862 "Yamaha Marine" 1863 "Faria Instruments" ;
VAL_ 2583630592 Industry_Code 0 "Global" 1 "Highway" 2 "Agriculture" 3 "Construction" 4 "Marine Industry" 5 "Industrial" ;
VAL_ 2583630848 Manufacturer_Code 69 "ARKS Enterprises" 78 "FW Murphy/Enovation Controls" 80 "Twin Disc" 85 "Kohler Power Systems" 88 "Hemisphere GPS" 135 "Airmar" 137 "Maretron" 140 "Lowrance" 144 "Mercury Marine" 147 "Nautibus Electronic" 148 "Blue Water Data" 154 "Westerbeke" 157 "ISSPRO" 161 "Offshore Systems (UK)" 163 "Evinrude/BRP" 165 "CPAC Systems" 168 "Xantrex Technology" 169 "Marlin Technologies" 172 "Yanmar Marine" 174 "Volvo Penta" 176 "Carling Technologies Inc. (Moritz Aerospace)" 185 "Beede Instruments" 192 "Floscan Instrument" 193 "Nobeltec" 198 "Mystic Valley Communications" 199 "Actia" 201 "Disenos Y Technologia" 211 "Digital Switching Systems" 215 "Xintex/Atena" 224 "EMMI NETWORK" 228 "ZF" 229 "Garmin" 233 "Yacht Monitoring Solutions" 235 "Sailormade Marine Telemetry/Tetra Technology" 243 "Eride" 257 "Honda Motor" 272 "Groco" 273 "Actisense" 274 "Amphenol LTW Technology" 275 "Navico" 283 "Hamilton Jet" 285 "Sea Recovery" 286 "Coelmo SRL Italy" 295 "BEP Marine" 304 "Empir Bus" 305 "NovAtel" 306 "Sleipner Motor" 307 "MBW Technologies" 315 "ICOM" 328 "Qwerty" 329 "Dief" 341 "Boening Automationstechnologie" 345 "Korean Maritime University" 351 "Thrane and Thrane" 355 "Mastervolt" 356 "Fischer Panda Generators" 358 "Victron Energy" 370 "Rolls Royce Marine" 373 "Electronic Design" 374 "Northern Lights" 378 "Glendinning" 381 "B & G" 384 "Rose Point Navigation Systems" 385 "Johnson Outdoors Marine Electronics Inc Geonav" 394 "Capi 2" 396 "Beyond Measure" 400 "Livorsi Marine" 404 "ComNav" 409 "Chetco" 419 "Fusion Electronics" 421 "Standard Horizon" 422 "True Heading" 426 "Egersund Marine Electronics" 427 "em-trak Marine Electronics" 431 "Tohatsu Co, JP" 437 "Digital Yacht" 438 "Comar Systems Limited" 440 "Cummins" 443 "VDO (aka Continental-Corporation)" 451 "Parker Hannifin aka Village Marine Tech" 459 "Alltek Marine Electronics" 460 "SAN GIORGIO S.E.I.N" 466 "Veethree Electronics & Marine" 470 "SI-TEX Marine Electronics" 471 "Sea Cross Marine" 475 "GME aka Standard Communications" 476 "Humminbird Marine Electronics" 478 "Ocean Sat" 481 "Chetco Digital Instruments" 493 "Watcheye" 499 "Lcj Capteurs" 502 "Attwood Marine" 503 "Naviop S.R.L." 504 "Vesper Marine" 510 "Marinesoft" 513 "Simarine" 517 "NoLand Engineering" 518 "Transas USA" 529 "National Instruments Korea" 530 "National Marine Electronics Association" 532 "Onwa Marine" 540 "Webasto" 571 "Marinecraft (South Korea)" 573 "McMurdo Group aka Orolia" 578 "Advansea" 579 "KVH" 580 "San Jose Technology" 583 "Yacht Control" 586 "Suzuki Motor" 591 "US Coast Guard" 595 "Ship Module aka Customware" 600 "Aquatic AV" 605 "Aventics" 606 "Intellian" 612 "SamwonIT" 614 "Arlt Tecnologies" 637 "Bavaria Yachts" 641 "Diverse Yacht Services" 644 "Wema U.S.A dba KUS" 658 "Shenzhen Jiuzhou Himunication" 688 "Rockford" 699 "Harman International" 704 "JL Audio" 708 "Lars Thrane" 715 "Autonnic" 717 "Yacht Devices" 734 "REAP Systems" 735 "AEM Performance Electronics" 739 "LxNav" 741 "Littelfuse, Inc (formerly Carling Technologies)" 743 "DaeMyung" 744 "Woosung" 748 "ISOTTA IFRA srl" 773 "Clarion US" 776 "HMI Systems" 777 "Ocean Signal" 778 "Seakeeper" 781 "Poly Planar" 785 "Fischer Panda DE" 795 "Broyda Industries" 796 "Canadian Automotive" 797 "Tides Marine" 798 "Lumishore" 799 "Still Water Designs and Audio" 802 "BJ Technologies (Beneteau)" 803 "Gill Sensors" 811 "Blue Water Desalination" 815 "FLIR" 824 "Undheim Systems" 826 "Lewmar" 838 "TeamSurv" 844 "Fell Marine" 847 "Oceanvolt" 862 "Prospec" 868 "Data Panel" 890 "L3 Technologies" 894 "Rhodan Marine Systems" 896 "Nexfour Solutions" 905 "ASA Electronics" 909 "Marines Co (South Korea)" 911 "Nautic-on" 917 "Sentinel" 929 "JL Marine Systems" 930 "Ecotronix" 944 "Zontisa Marine" 951 "EXOR International" 962 "Timbolier Industries" 963 "TJC Micro" 968 "Cox Powertrain" 969 "Blue Seas" 981 "Kobelt Manufacturing" 992 "Blue Ocean IOT" 997 "Xenta Systems" 999 "Signal K" 1004 "Ultraflex" 1008 "Lintest SmartBoat" 1011 "Soundmax" 1020 "Team Italia Marine (Onyx Marine Automation s.r.l)" 1021 "Entratech" 1022 "ITC" 1029 "The Marine Guardian" 1047 "Sonic" 1051 "ProNav" 1053 "Vetus Maxwell INC." 1056 "Lithium Pros" 1059 "Boatrax" 1062 "Marol Co ltd" 1065 "CALYPSO Instruments" 1066 "Spot Zero Water" 1069 "Lithionics Battery" 1070 "Quick-teck Electronics" 1075 "Uniden America" 1083 "Nauticoncept" 1084 "Shadow-Caster LED lighting" 1085 "Wet Sounds" 1088 "E-T-A Circuit Breakers" 1092 "Scheiber" 1100 "Smart Yachts International Limited" 1109 "Dockmate" 1114 "Bobs Machine" 1118 "L3Harris ASV" 1119 "Balmar" 1120 "Elettromedia" 1127 "Electromaax" 1140 "Across Oceans Systems" 1145 "Kiwi Yachting" 1150 "BSB Artificial Intelligence" 1151 "Orca Technologies" 1154 "TBS Electronics" 1158 "Technoton Electroics" 1160 "MG Energy Systems" 1169 "Sea Machine Robotics" 1171 "Vista Manufacturing" 1183 "Zipwake" 1186 "Sailmon" 1192 "Airmoniq Pro Kft" 1194 "Sierra Marine" 1200 "Xinuo Information Technology (Xiamen)" 1218 "Septentrio" 1233 "NKE Marine Electronics" 1238 "SuperTrack Aps" 1239 "Honda Electronics" 1245 "Raritan Engineering" 1249 "Integrated Power Solutions AG" 1260 "Interactive Technologies" 1283 "LTG-Tech" 1299 "Energy Solutions (UK)" 1300 "WATT Fuel Cell" 1302 "Pro Mainer" 1305 "Dragonfly Energy" 1306 "Koden Electronics" 1311 "Humphree" 1316 "Hinkley Yachts" 1317 "Global Marine Management GmbH (GMM)" 1320 "Triskel Marine" 1330 "Warwick Control Technologies" 1331 "Dolphin Charger" 1337 "Barnacle Systems" 1348 "Radian IoT" 1353 "Ocean LED Marine" 1359 "BluNav" 1361 "OVA (Nantong Saiyang Electronics Co., Ltd)" 1368 "RAD Propulsion" 1369 "Electric Yacht" 1372 "Elco Motor Yachts" 1384 "Tecnoseal Foundry S.r.l" 1385 "Pro Charging Systems" 1389 "EVEX" 1398 "Gobius Sensor Technology" 1403 "Arco Marine" 1408 "Lenco Marine" 1413 "Naocontrol" 1417 "Revatek" 1438 "Aeolionics" 1439 "PredictWind" 1440 "Egis Mobile Electric" 1445 "Starboard Yacht Group" 1446 "Roswell Marine" 1451 "ePropulsion (Guangdong ePropulsion Technology Ltd.)" 1452 "Micro-Air" 1453 "Vital Battery" 1458 "Ride Controller" 1460 "Tocaro Blue" 1461 "Vanquish Yachts" 1471 "FT Technologies" 1478 "Alps Alpine" 1481 "E-Force Marine" 1482 "CMC Marine" 1483 "Nanjing Sandemarine Information Technology" 1850 "Teleflex Marine (SeaStar Solutions)" 1851 "Raymarine" 1852 "Navionics" 1853 "Japan Radio" 1854 "Northstar Technologies" 1855 "Furuno" 1856 "Trimble" 1857 "Simrad" 1858 "Litton" 1859 "Kvasar" 1860 "MMP" 1861 "Vector Cantech" 1862 "Yamaha Marine" 1863 "Faria Instruments" ;
VAL_ 2583630848 Industry_Code 0 "Global" 1 "Highway" 2 "Agriculture" 3 "Construction" 4 "Marine Industry" 5 "Industrial" ;
VAL_ 2583630848 Switch_Status 0 "Off" 1 "On" ;
VAL_ 2583630848 Manufacturer_Code 69 "ARKS Enterprises" 78 "FW Murphy/Enovation Controls" 80 "Twin Disc" 85 "Kohler Power Systems" 88 "Hemisphere GPS" 135 "Airmar" 137 "Maretron" 140 "Lowrance" 144 "Mercury Marine" 147 "Nautibus Electronic" 148 "Blue Water Data" 154 "Westerbeke" 157 "ISSPRO" 161 "Offshore Systems (UK)" 163 "Evinrude/BRP" 165 "CPAC Systems" 168 "Xantrex Technology" 169 "Marlin Technologies" 172 "Yanmar Marine" 174 "Volvo Penta" 176 "Carling Technologies Inc. (Moritz Aerospace)" 185 "Beede Instruments" 192 "Floscan Instrument" 193 "Nobeltec" 198 "Mystic Valley Communications" 199 "Actia" 201 "Disenos Y Technologia" 211 "Digital Switching Systems" 215 "Xintex/Atena" 224 "EMMI NETWORK" 228 "ZF" 229 "Garmin" 233 "Yacht Monitoring Solutions" 235 "Sailormade Marine Telemetry/Tetra Technology" 243 "Eride" 257 "Honda Motor" 272 "Groco" 273 "Actisense" 274 "Amphenol LTW Technology" 275 "Navico" 283 "Hamilton Jet" 285 "Sea Recovery" 286 "Coelmo SRL Italy" 295 "BEP Marine" 304 "Empir Bus" 305 "NovAtel" 306 "Sleipner Motor" 307 "MBW Technologies" 315 "ICOM" 328 "Qwerty" 329 "Dief" 341 "Boening Automationstechnologie" 345 "Korean Maritime University" 351 "Thrane and Thrane" 355 "Mastervolt" 356 "Fischer Panda Generators" 358 "Victron Energy" 370 "Rolls Royce Marine" 373 "Electronic Design" 374 "Northern Lights" 378 "Glendinning" 381 "B & G" 384 "Rose Point Navigation Systems" 385 "Johnson Outdoors Marine Electronics Inc Geonav" 394 "Capi 2" 396 "Beyond Measure" 400 "Livorsi Marine" 404 "ComNav" 409 "Chetco" 419 "Fusion Electronics" 421 "Standard Horizon" 422 "True Heading" 426 "Egersund Marine Electronics" 427 "em-trak Marine Electronics" 431 "Tohatsu Co, JP" 437 "Digital Yacht" 438 "Comar Systems Limited" 440 "Cummins" 443 "VDO (aka Continental-Corporation)" 451 "Parker Hannifin aka Village Marine Tech" 459 "Alltek Marine Electronics" 460 "SAN GIORGIO S.E.I.N" 466 "Veethree Electronics & Marine" 470 "SI-TEX Marine Electronics" 471 "Sea Cross Marine" 475 "GME aka Standard Communications" 476 "Humminbird Marine Electronics" 478 "Ocean Sat" 481 "Chetco Digital Instruments" 493 "Watcheye" 499 "Lcj Capteurs" 502 "Attwood Marine" 503 "Naviop S.R.L." 504 "Vesper Marine" 510 "Marinesoft" 513 "Simarine" 517 "NoLand Engineering" 518 "Transas USA" 529 "National Instruments Korea" 530 "National Marine Electronics Association" 532 "Onwa Marine" 540 "Webasto" 571 "Marinecraft (South Korea)" 573 "McMurdo Group aka Orolia" 578 "Advansea" 579 "KVH" 580 "San Jose Technology" 583 "Yacht Control" 586 "Suzuki Motor" 591 "US Coast Guard" 595 "Ship Module aka Customware" 600 "Aquatic AV" 605 "Aventics" 606 "Intellian" 612 "SamwonIT" 614 "Arlt Tecnologies" 637 "Bavaria Yachts" 641 "Diverse Yacht Services" 644 "Wema U.S.A dba KUS" 658 "Shenzhen Jiuzhou Himunication" 688 "Rockford" 699 "Harman International" 704 "JL Audio" 708 "Lars Thrane" 715 "Autonnic" 717 "Yacht Devices" 734 "REAP Systems" 735 "AEM Performance Electronics" 739 "LxNav" 741 "Littelfuse, Inc (formerly Carling Technologies)" 743 "DaeMyung" 744 "Woosung" 748 "ISOTTA IFRA srl" 773 "Clarion US" 776 "HMI Systems" 777 "Ocean Signal" 778 "Seakeeper" 781 "Poly Planar" 785 "Fischer Panda DE" 795 "Broyda Industries" 796 "Canadian Automotive" 797 "Tides Marine" 798 "Lumishore" 799 "Still Water Designs and Audio" 802 "BJ Technologies (Beneteau)" 803 "Gill Sensors" 811 "Blue Water Desalination" 815 "FLIR" 824 "Undheim Systems" 826 "Lewmar" 838 "TeamSurv" 844 "Fell Marine" 847 "Oceanvolt" 862 "Prospec" 868 "Data Panel" 890 "L3 Technologies" 894 "Rhodan Marine Systems" 896 "Nexfour Solutions" 905 "ASA Electronics" 909 "Marines Co (South Korea)" 911 "Nautic-on" 917 "Sentinel" 929 "JL Marine Systems" 930 "Ecotronix" 944 "Zontisa Marine" 951 "EXOR International" 962 "Timbolier Industries" 963 "TJC Micro" 968 "Cox Powertrain" 969 "Blue Seas" 981 "Kobelt Manufacturing" 992 "Blue Ocean IOT" 997 "Xenta Systems" 999 "Signal K" 1004 "Ultraflex" 1008 "Lintest SmartBoat" 1011 "Soundmax" 1020 "Team Italia Marine (Onyx Marine Automation s.r.l)" 1021 "Entratech" 1022 "ITC" 1029 "The Marine Guardian" 1047 "Sonic" 1051 "ProNav" 1053 "Vetus Maxwell INC." 1056 "Lithium Pros" 1059 "Boatrax" 1062 "Marol Co ltd" 1065 "CALYPSO Instruments" 1066 "Spot Zero Water" 1069 "Lithionics Battery" 1070 "Quick-teck Electronics" 1075 "Uniden America" 1083 "Nauticoncept" 1084 "Shadow-Caster LED lighting" 1085 "Wet Sounds" 1088 "E-T-A Circuit Breakers" 1092 "Scheiber" 1100 "Smart Yachts International Limited" 1109 "Dockmate" 1114 "Bobs Machine" 1118 "L3Harris ASV" 1119 "Balmar" 1120 "Elettromedia" 1127 "Electromaax" 1140 "Across Oceans Systems" 1145 "Kiwi Yachting" 1150 "BSB Artificial Intelligence" 1151 "Orca Technologies" 1154 "TBS Electronics" 1158 "Technoton Electroics" 1160 "MG Energy Systems" 1169 "Sea Machine Robotics" 1171 "Vista Manufacturing" 1183 "Zipwake" 1186 "Sailmon" 1192 "Airmoniq Pro Kft" 1194 "Sierra Marine" 1200 "Xinuo Information Technology (Xiamen)" 1218 "Septentrio" 1233 "NKE Marine Electronics" 1238 "SuperTrack Aps" 1239 "Honda Electronics" 1245 "Raritan Engineering" 1249 "Integrated Power Solutions AG" 1260 "Interactive Technologies" 1283 "LTG-Tech" 1299 "Energy Solutions (UK)" 1300 "WATT Fuel Cell" 1302 "Pro Mainer" 1305 "Dragonfly Energy" 1306 "Koden Electronics" 1311 "Humphree" 1316 "Hinkley Yachts" 1317 "Global Marine Management GmbH (GMM)" 1320 "Triskel Marine" 1330 "Warwick Control Technologies" 1331 "Dolphin Charger" 1337 "Barnacle Systems" 1348 "Radian IoT" 1353 "Ocean LED Marine" 1359 "BluNav" 1361 "OVA (Nantong Saiyang Electronics Co., Ltd)" 1368 "RAD Propulsion" 1369 "Electric Yacht" 1372 "Elco Motor Yachts" 1384 "Tecnoseal Foundry S.r.l" 1385 "Pro Charging Systems" 1389 "EVEX" 1398 "Gobius Sensor Technology" 1403 "Arco Marine" 1408 "Lenco Marine" 1413 "Naocontrol" 1417 "Revatek" 1438 "Aeolionics" 1439 "PredictWind" 1440 "Egis Mobile Electric" 1445 "Starboard Yacht Group" 1446 "Roswell Marine" 1451 "ePropulsion (Guangdong ePropulsion Technology Ltd.)" 1452 "Micro-Air" 1453 "Vital Battery" 1458 "Ride Controller" 1460 "Tocaro Blue" 1461 "Vanquish Yachts" 1471 "FT Technologies" 1478 "Alps Alpine" 1481 "E-Force Marine" 1482 "CMC Marine" 1483 "Nanjing Sandemarine Information Technology" 1850 "Teleflex Marine (SeaStar Solutions)" 1851 "Raymarine" 1852 "Navionics" 1853 "Japan Radio" 1854 "Northstar Technologies" 1855 "Furuno" 1856 "Trimble" 1857 "Simrad" 1858 "Litton" 1859 "Kvasar" 1860 "MMP" 1861 "Vector Cantech" 1862 "Yamaha Marine" 1863 "Faria Instruments" ;
VAL_ 2583630848 Industry_Code 0 "Global" 1 "Highway" 2 "Agriculture" 3 "Construction" 4 "Marine Industry" 5 "Industrial" ;
VAL_ 2583630848 Tank_type 0 "Fuel" 1 "Water" 2 "Gray water" 3 "Live well" 4 "Oil" 5 "Black water" ;
CM_ SG_ 2583630080 Short_name "STRING field: decode bytes as ASCII (0x00/@/0xFF = terminator); canboat type: STRING_FIX";
CM_ SG_ 2583630080 Long_name "STRING field: decode bytes as ASCII (0x00/@/0xFF = terminator); canboat type: STRING_FIX";
CM_ SG_ 2583630336 SIM_Card_Phone_Number "STRING field: decode bytes as ASCII (0x00/@/0xFF = terminator); canboat type: STRING_LAU";
CM_ SG_ 2583630336 Network_Operator_Name "STRING field: decode bytes as ASCII (0x00/@/0xFF = terminator); canboat type: STRING_LAU";
CM_ SG_ 2583630592 Phone_Number "STRING field: decode bytes as ASCII (0x00/@/0xFF = terminator); canboat type: STRING_LAU";
CM_ SG_ 2583630592 Message "STRING field: decode bytes as ASCII (0x00/@/0xFF = terminator); canboat type: STRING_LAU";

BA_DEF_ BO_ "GenMsgCycleTime" INT 0 60000;
BA_DEF_ BO_ "ProtocolType" STRING;

BA_DEF_ BO_ "J1939PGN" INT 0 262143;
BA_ "J1939PGN" BO_ 2583628544 130827;
BA_ "J1939PGN" BO_ 2583628544 130827;
BA_ "J1939PGN" BO_ 2583628544 130827;
BA_ "J1939PGN" BO_ 2315193344 130828;
BA_ "J1939PGN" BO_ 2583628800 130828;
BA_ "J1939PGN" BO_ 2583628800 130828;
BA_ "J1939PGN" BO_ 2650737920 130829;
BA_ "J1939PGN" BO_ 2516520448 130830;
BA_ "J1939PGN" BO_ 2583629312 130830;
BA_ "J1939PGN" BO_ 2583629568 130831;
BA_ "J1939PGN" BO_ 2583629568 130831;
BA_ "J1939PGN" BO_ 2650738688 130832;
BA_ "J1939PGN" BO_ 2583629824 130832;
BA_ "J1939PGN" BO_ 2583630080 130833;
BA_ "J1939PGN" BO_ 2650738944 130833;
BA_ "J1939PGN" BO_ 2650738944 130833;
BA_ "J1939PGN" BO_ 2650739200 130834;
BA_ "J1939PGN" BO_ 2583630336 130834;
BA_ "J1939PGN" BO_ 2583630336 130834;
BA_ "J1939PGN" BO_ 2583630592 130835;
BA_ "J1939PGN" BO_ 2583630592 130835;
BA_ "J1939PGN" BO_ 2583630848 130836;
BA_ "GenMsgCycleTime" BO_ 2583630848 15000;
BA_ "J1939PGN" BO_ 2583630848 130836;
